VERSION "10.9.1"

NS_ :

BS_:

BU_: ACM ADAS_Body APM ASU_Gateway BCM BCM_BPM CCU_F CCU_R DUMMY_BCM_BPM DUMMY_ECU ETG LDM_L LDM_R OCS_P PSM_D SHVU_F SHVU_R TRM XGW_Body

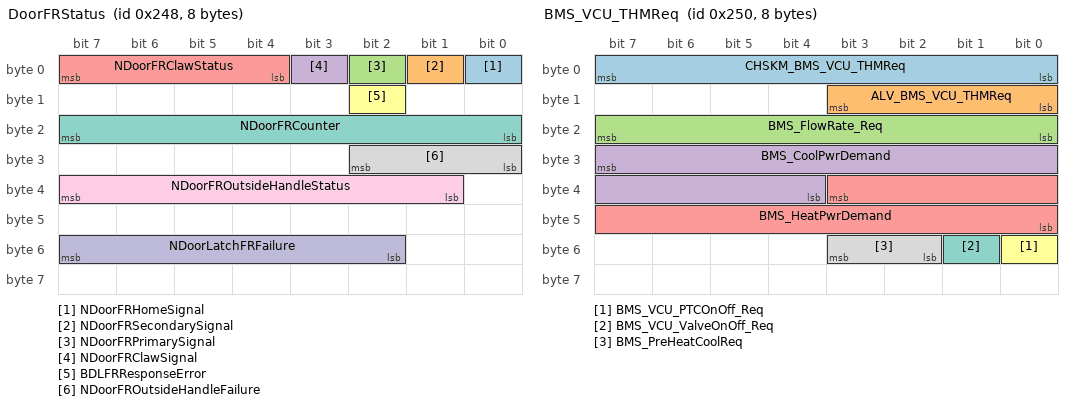
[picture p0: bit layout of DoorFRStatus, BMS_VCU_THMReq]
BO_ 584 DoorFRStatus: 8 XGW_Body
 SG_ NDoorFRHomeSignal : 0|1@0+ (1,0) [0|1] ""  BCM
 SG_ NDoorFRSecondarySignal : 1|1@0+ (1,0) [0|1] ""  BCM
 SG_ NDoorFRPrimarySignal : 2|1@0+ (1,0) [0|1] ""  BCM
 SG_ NDoorFRClawSignal : 3|1@0+ (1,0) [0|1] ""  BCM
 SG_ NDoorFRClawStatus : 7|4@0+ (1,0) [0|15] ""  BCM
 SG_ BDLFRResponseError : 10|1@0+ (1,0) [0|1] ""  BCM
 SG_ NDoorFRCounter : 23|8@0+ (1,0) [0|255] ""  BCM
 SG_ NDoorFROutsideHandleFailure : 26|3@0+ (1,0) [0|7] ""  BCM
 SG_ NDoorFROutsideHandleStatus : 39|7@0+ (1,0) [0|127] ""  BCM
 SG_ NDoorLatchFRFailure : 55|6@0+ (1,0) [0|63] ""  BCM

BO_ 592 BMS_VCU_THMReq: 8 XGW_Body
 SG_ CHSKM_BMS_VCU_THMReq : 7|8@0+ (1,0) [0|255] ""  BCM
 SG_ ALV_BMS_VCU_THMReq : 11|4@0+ (1,0) [0|14] ""  BCM
 SG_ BMS_FlowRate_Req : 23|8@0+ (1,0) [0|50] "l/min"  BCM
 SG_ BMS_CoolPwrDemand : 31|12@0+ (0.1,0) [0|10] "kW"  BCM
 SG_ BMS_HeatPwrDemand : 35|12@0+ (0.1,0) [0|10] "kW"  BCM
 SG_ BMS_VCU_PTCOnOff_Req : 48|1@0+ (1,0) [0|1] ""  BCM
 SG_ BMS_VCU_ValveOnOff_Req : 49|1@0+ (1,0) [0|1] ""  BCM
 SG_ BMS_PreHeatCoolReq : 51|2@0+ (1,0) [0|3] "" BCM

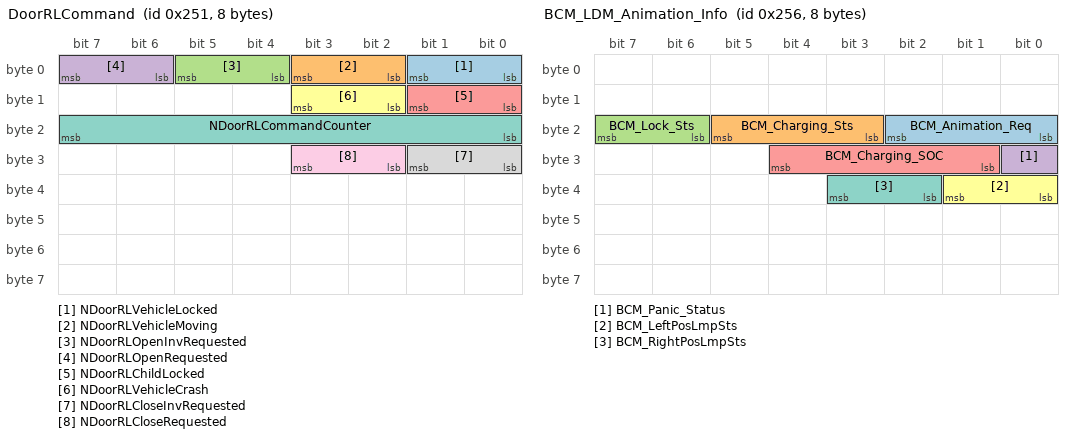
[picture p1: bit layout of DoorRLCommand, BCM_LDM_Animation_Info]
BO_ 593 DoorRLCommand: 8 BCM
 SG_ NDoorRLVehicleLocked : 1|2@0+ (1,0) [0|3] ""  DUMMY_ECU
 SG_ NDoorRLVehicleMoving : 3|2@0+ (1,0) [0|3] ""  DUMMY_ECU
 SG_ NDoorRLOpenInvRequested : 5|2@0+ (1,0) [0|3] ""  XGW_Body
 SG_ NDoorRLOpenRequested : 7|2@0+ (1,0) [0|3] ""  XGW_Body
 SG_ NDoorRLChildLocked : 9|2@0+ (1,0) [0|3] ""  DUMMY_ECU
 SG_ NDoorRLVehicleCrash : 11|2@0+ (1,0) [0|3] ""  DUMMY_ECU
 SG_ NDoorRLCommandCounter : 23|8@0+ (1,0) [0|255] ""  XGW_Body
 SG_ NDoorRLCloseInvRequested : 25|2@0+ (1,0) [0|3] ""  XGW_Body
 SG_ NDoorRLCloseRequested : 27|2@0+ (1,0) [0|3] ""  XGW_Body

BO_ 596 IDB_AVL_RPM_WHL_REAR: 8 XGW_Body
 SG_ CRC_AVL_RPM_WHL_REAR : 7|8@0+ (1,0) [0|255] ""  LDM_L,LDM_R
 SG_ ALIV_AVL_RPM_WHL_REAR : 11|4@0+ (1,0) [0|14] ""  LDM_L,LDM_R
 SG_ AVL_RPM_WHL_RLH : 23|16@0+ (0.0156,-511.9844) [-400|400] "rad/s"  LDM_L,LDM_R
 SG_ AVL_RPM_WHL_RRH : 39|16@0+ (0.0156,-511.9844) [-400|400] "rad/s"  LDM_L,LDM_R
 SG_ QU_AVL_RPM_WHL_RLH : 55|4@0+ (1,0) [0|15] "Bit"  LDM_L,LDM_R
 SG_ QU_AVL_RPM_WHL_RRH : 63|4@0+ (1,0) [0|15] "Bit"  LDM_L,LDM_R

BO_ 597 IDB_AVL_RPM_WHL_FRONT: 8 XGW_Body
 SG_ CRC_AVL_RPM_WHL_FRONT : 7|8@0+ (1,0) [0|255] ""  LDM_L,LDM_R
 SG_ ALIV_AVL_RPM_WHL_FRONT : 11|4@0+ (1,0) [0|14] ""  LDM_L,LDM_R
 SG_ AVL_RPM_WHL_FLH : 23|16@0+ (0.0156,-511.9844) [-400|400] "rad/s"  LDM_L,LDM_R
 SG_ AVL_RPM_WHL_FRH : 39|16@0+ (0.0156,-511.9844) [-400|400] "rad/s"  LDM_L,LDM_R
 SG_ QU_AVL_RPM_WHL_FLH : 55|4@0+ (1,0) [0|15] "Bit"  LDM_L,LDM_R
 SG_ QU_AVL_RPM_WHL_FRH : 63|4@0+ (1,0) [0|15] "Bit"  LDM_L,LDM_R

BO_ 598 BCM_LDM_Animation_Info: 8 BCM
 SG_ BCM_Animation_Req : 18|3@0+ (1,0) [0|7] ""  LDM_L,LDM_R
 SG_ BCM_Charging_Sts : 21|3@0+ (1,0) [0|7] ""  LDM_L,LDM_R
 SG_ BCM_Lock_Sts : 23|2@0+ (1,0) [0|3] ""  LDM_L,LDM_R
 SG_ BCM_Panic_Status : 24|1@0+ (1,0) [0|1] ""  LDM_L,LDM_R
 SG_ BCM_Charging_SOC : 28|4@0+ (1,0) [0|15] ""  LDM_L,LDM_R
 SG_ BCM_LeftPosLmpSts : 33|2@0+ (1,0) [0|3] ""  LDM_L
 SG_ BCM_RightPosLmpSts : 35|2@0+ (1,0) [0|3] ""  LDM_R

BO_ 618 ST_LCS_VEH: 3 ASU_Gateway
 SG_ ALIV_ST_LCS_VEH : 0|4@1+ (1,0) [0|14] ""  BCM,DUMMY_ECU
 SG_ ST_ECU_ST_LCS_VEH : 4|4@1+ (1,0) [0|15] ""  BCM,DUMMY_ECU
 SG_ QU_FN_LCS_VEH : 8|12@1+ (1,0) [0|0] ""  BCM,DUMMY_ECU

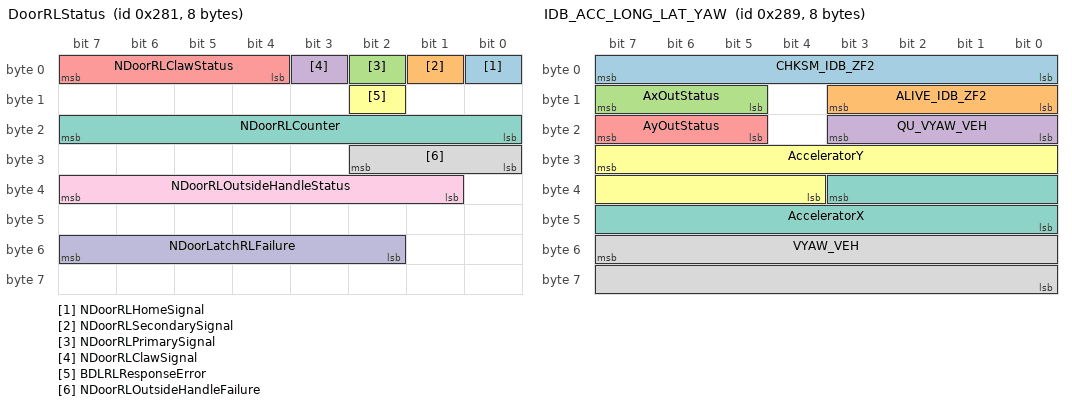
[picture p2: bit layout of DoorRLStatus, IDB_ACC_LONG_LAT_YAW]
BO_ 641 DoorRLStatus: 8 XGW_Body
 SG_ NDoorRLHomeSignal : 0|1@0+ (1,0) [0|1] ""  BCM
 SG_ NDoorRLSecondarySignal : 1|1@0+ (1,0) [0|1] ""  BCM
 SG_ NDoorRLPrimarySignal : 2|1@0+ (1,0) [0|1] ""  BCM
 SG_ NDoorRLClawSignal : 3|1@0+ (1,0) [0|1] ""  BCM
 SG_ NDoorRLClawStatus : 7|4@0+ (1,0) [0|15] ""  BCM
 SG_ BDLRLResponseError : 10|1@0+ (1,0) [0|1] ""  BCM
 SG_ NDoorRLCounter : 23|8@0+ (1,0) [0|255] ""  BCM
 SG_ NDoorRLOutsideHandleFailure : 26|3@0+ (1,0) [0|7] ""  BCM
 SG_ NDoorRLOutsideHandleStatus : 39|7@0+ (1,0) [0|127] ""  BCM
 SG_ NDoorLatchRLFailure : 55|6@0+ (1,0) [0|63] ""  BCM

BO_ 649 IDB_ACC_LONG_LAT_YAW: 8 XGW_Body
 SG_ CHKSM_IDB_ZF2 : 7|8@0+ (1,0) [0|255] ""  LDM_L,LDM_R
 SG_ ALIVE_IDB_ZF2 : 11|4@0+ (1,0) [0|14] ""  LDM_L,LDM_R
 SG_ AxOutStatus : 15|3@0+ (1,0) [0|7] ""  LDM_L,LDM_R
 SG_ QU_VYAW_VEH : 19|4@0+ (1,0) [0|15] ""  LDM_L,LDM_R
 SG_ AyOutStatus : 23|3@0+ (1,0) [0|7] ""  LDM_L,LDM_R
 SG_ AcceleratorY : 31|12@0+ (0.02713,-21.5928) [-21.593|21.5928] "m/s^2"  LDM_L,LDM_R
 SG_ AcceleratorX : 35|12@0+ (0.02713,-21.5928) [-21.593|21.5928] "m/s^2"  LDM_L,LDM_R
 SG_ VYAW_VEH : 55|16@0+ (0.005,-163.84) [-163.84|163.83] "°/s"  LDM_L,LDM_R

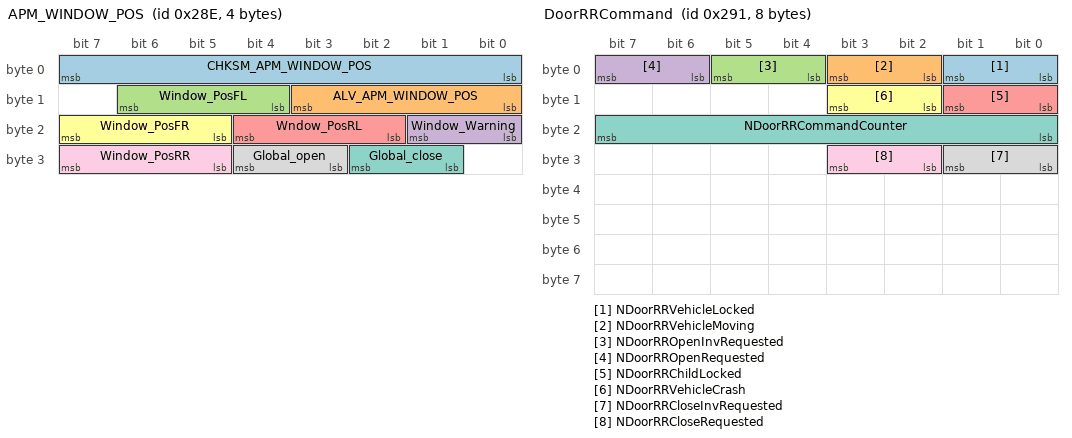
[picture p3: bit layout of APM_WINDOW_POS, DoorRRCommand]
BO_ 654 APM_WINDOW_POS: 4 APM
 SG_ CHKSM_APM_WINDOW_POS : 7|8@0+ (1,0) [0|255] ""  XGW_Body
 SG_ ALV_APM_WINDOW_POS : 11|4@0+ (1,0) [0|14] ""  XGW_Body
 SG_ Window_PosFL : 14|3@0+ (1,0) [0|7] "-"  XGW_Body
 SG_ Window_Warning : 17|2@0+ (1,0) [0|3] ""  XGW_Body
 SG_ Wndow_PosRL : 20|3@0+ (1,0) [0|7] ""  XGW_Body
 SG_ Window_PosFR : 23|3@0+ (1,0) [0|7] ""  XGW_Body
 SG_ Global_close : 26|2@0+ (1,0) [0|3] ""  XGW_Body
 SG_ Global_open : 28|2@0+ (1,0) [0|3] ""  XGW_Body
 SG_ Window_PosRR : 31|3@0+ (1,0) [0|7] "-"  XGW_Body

BO_ 657 DoorRRCommand: 8 BCM
 SG_ NDoorRRVehicleLocked : 1|2@0+ (1,0) [0|3] ""  DUMMY_ECU
 SG_ NDoorRRVehicleMoving : 3|2@0+ (1,0) [0|3] ""  DUMMY_ECU
 SG_ NDoorRROpenInvRequested : 5|2@0+ (1,0) [0|3] ""  XGW_Body
 SG_ NDoorRROpenRequested : 7|2@0+ (1,0) [0|3] ""  XGW_Body
 SG_ NDoorRRChildLocked : 9|2@0+ (1,0) [0|3] ""  DUMMY_ECU
 SG_ NDoorRRVehicleCrash : 11|2@0+ (1,0) [0|3] ""  DUMMY_ECU
 SG_ NDoorRRCommandCounter : 23|8@0+ (1,0) [0|255] ""  XGW_Body
 SG_ NDoorRRCloseInvRequested : 25|2@0+ (1,0) [0|3] ""  XGW_Body
 SG_ NDoorRRCloseRequested : 27|2@0+ (1,0) [0|3] ""  XGW_Body

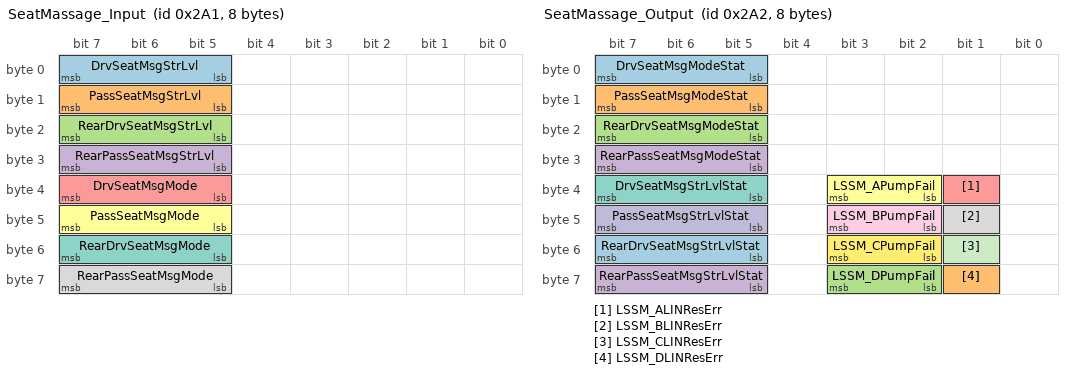
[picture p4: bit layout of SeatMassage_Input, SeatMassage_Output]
BO_ 673 SeatMassage_Input: 8 XGW_Body
 SG_ DrvSeatMsgStrLvl : 7|3@0+ (1,0) [0|7] ""  PSM_D
 SG_ PassSeatMsgStrLvl : 15|3@0+ (1,0) [0|7] ""  PSM_D
 SG_ RearDrvSeatMsgStrLvl : 23|3@0+ (1,0) [0|7] "-"  PSM_D
 SG_ RearPassSeatMsgStrLvl : 31|3@0+ (1,0) [0|7] ""  PSM_D
 SG_ DrvSeatMsgMode : 39|3@0+ (1,0) [0|7] ""  PSM_D
 SG_ PassSeatMsgMode : 47|3@0+ (1,0) [0|7] ""  PSM_D
 SG_ RearDrvSeatMsgMode : 55|3@0+ (1,0) [0|7] ""  PSM_D
 SG_ RearPassSeatMsgMode : 63|3@0+ (1,0) [0|7] "-"  PSM_D

BO_ 674 SeatMassage_Output: 8 PSM_D
 SG_ DrvSeatMsgModeStat : 7|3@0+ (1,0) [0|7] ""  XGW_Body
 SG_ PassSeatMsgModeStat : 15|3@0+ (1,0) [0|7] ""  XGW_Body
 SG_ RearDrvSeatMsgModeStat : 23|3@0+ (1,0) [0|7] ""  XGW_Body
 SG_ RearPassSeatMsgModeStat : 31|3@0+ (1,0) [0|7] ""  XGW_Body
 SG_ LSSM_ALINResErr : 33|1@0+ (1,0) [0|1] ""  XGW_Body
 SG_ LSSM_APumpFail : 35|2@0+ (1,0) [0|3] ""  XGW_Body
 SG_ DrvSeatMsgStrLvlStat : 39|3@0+ (1,0) [0|7] ""  XGW_Body
 SG_ LSSM_BLINResErr : 41|1@0+ (1,0) [0|1] ""  XGW_Body
 SG_ LSSM_BPumpFail : 43|2@0+ (1,0) [0|3] ""  XGW_Body
 SG_ PassSeatMsgStrLvlStat : 47|3@0+ (1,0) [0|7] "-"  XGW_Body
 SG_ LSSM_CLINResErr : 49|1@0+ (1,0) [0|1] ""  XGW_Body
 SG_ LSSM_CPumpFail : 51|2@0+ (1,0) [0|3] "-"  XGW_Body
 SG_ RearDrvSeatMsgStrLvlStat : 55|3@0+ (1,0) [0|7] "-"  XGW_Body
 SG_ LSSM_DLINResErr : 57|1@0+ (1,0) [0|1] ""  XGW_Body
 SG_ LSSM_DPumpFail : 59|2@0+ (1,0) [0|3] "-"  XGW_Body
 SG_ RearPassSeatMsgStrLvlStat : 63|3@0+ (1,0) [0|7] ""  XGW_Body

BO_ 676 SVC_EHC_EHC_2: 8 ASU_Gateway
 SG_ ID2 M : 0|8@1+ (1,0) [0|0] ""  BCM,XGW_Body
 SG_ ECU_ID_WUPREG m39 : 8|8@1+ (1,0) [0|127] ""  BCM,XGW_Body
 SG_ ID_FN_INQY m1 : 8|16@1+ (1,0) [0|0] ""  BCM,XGW_Body
 SG_ ID_FN_RQ_BUS m12 : 8|16@1+ (1,0) [0|0] ""  BCM,XGW_Body
 SG_ NO_CC_MESS_EXT m65 : 8|16@1+ (1,0) [0|65534] ""  BCM,XGW_Body
 SG_ NO_CC_MESS_STD m64 : 8|16@1+ (1,0) [0|65534] ""  BCM,XGW_Body
 SG_ WACA m39 : 16|8@1+ (1,0) [0|0] ""  BCM,XGW_Body
 SG_ ID_RQ_BUS m12 : 24|8@1+ (1,0) [0|0] ""  BCM,XGW_Body
 SG_ ST_CC_MESS_EXT m65 : 24|2@1+ (1,0) [0|0] ""  BCM,XGW_Body
 SG_ ST_CC_MESS_STD m64 : 24|2@1+ (1,0) [0|0] ""  BCM,XGW_Body
 SG_ TRANF_CC_MESS_EXT m65 : 26|4@1+ (1,0) [0|14] ""  BCM,XGW_Body
 SG_ TRANF_CC_MESS_STD m64 : 26|4@1+ (1,0) [0|14] ""  BCM,XGW_Body
 SG_ ST_IDC_CCLK_CC_MESS_EXT m65 : 30|2@1+ (1,0) [0|0] ""  BCM,XGW_Body
 SG_ ST_IDC_CCLK_CC_MESS_STD m64 : 30|2@1+ (1,0) [0|0] ""  BCM,XGW_Body
 SG_ NO_FRM_CC_MESS_EXT m65 : 32|4@1+ (1,0) [0|14] ""  BCM,XGW_Body
 SG_ ST_RQ_BUS m12 : 32|4@1+ (1,0) [0|0] ""  BCM,XGW_Body
 SG_ QUAN_FRM_CC_MESS_EXT m65 : 36|4@1+ (1,0) [0|14] ""  BCM,XGW_Body
 SG_ ST_LAW_RQ m12 : 36|4@1+ (1,0) [0|0] ""  BCM,XGW_Body
 SG_ DUR_FLLUPT m12 : 40|8@1+ (1,0) [0|254] "min"  BCM,XGW_Body
 SG_ UTDT_CC_MESS m65 : 40|24@1+ (1,0) [0|0] ""  BCM,XGW_Body

BO_ 714 IC_SENSOR: 8 XGW_Body
 SG_ CHKSM_IC_SENSOR : 7|8@0+ (1,0) [0|255] ""  ACM,ADAS_Body,APM,ASU_Gateway,BCM,BCM_BPM,CCU_F,CCU_R,ETG,LDM_L,LDM_R,OCS_P,PSM_D,SHVU_F,SHVU_R,TRM
 SG_ ALV_IC_SENSOR : 11|4@0+ (1,0) [0|14] ""  ACM,ADAS_Body,APM,ASU_Gateway,BCM,BCM_BPM,CCU_F,CCU_R,ETG,LDM_L,LDM_R,OCS_P,PSM_D,SHVU_F,SHVU_R,TRM
 SG_ MHU_STAT_AmbientTempRaw : 23|8@0+ (0.5,-40) [-40|85] "°C"  ACM,ADAS_Body,APM,ASU_Gateway,BCM,BCM_BPM,CCU_F,CCU_R,ETG,LDM_L,LDM_R,OCS_P,PSM_D,SHVU_F,SHVU_R,TRM
 SG_ MHU_STAT_FuelLevel : 31|8@0+ (1,0) [0|100] "l"  ACM,ADAS_Body,APM,ASU_Gateway,BCM,BCM_BPM,CCU_F,CCU_R,ETG,LDM_L,LDM_R,OCS_P,PSM_D,SHVU_F,SHVU_R,TRM
 SG_ MHU_STAT_AmbientTemp : 39|8@0+ (0.5,-40) [-40|85] "Degree C"  ACM,ADAS_Body,APM,ASU_Gateway,BCM,BCM_BPM,CCU_F,CCU_R,ETG,LDM_L,LDM_R,OCS_P,PSM_D,SHVU_F,SHVU_R,TRM
 SG_ MHU_STAT_CoolantLevelStatus : 47|2@0+ (1,0) [0|3] "-"  ACM,ADAS_Body,APM,ASU_Gateway,BCM,BCM_BPM,CCU_F,CCU_R,ETG,LDM_L,LDM_R,OCS_P,PSM_D,SHVU_F,SHVU_R,TRM

BO_ 715 IC_TEMP: 8 BCM
 SG_ TEMP_EX : 7|8@0+ (0.5,-40) [-40|85] "°C"  DUMMY_ECU,XGW_Body
 SG_ TEMP_EX_UNFILT : 15|8@0+ (0.5,-40) [-40|85] "°C"  CCU_F,CCU_R,DUMMY_ECU,LDM_L,LDM_R,XGW_Body

BO_ 753 IC_STAT_AIRBAG: 1 XGW_Body
 SG_ MHU_STAT_AirbagWarnLamp : 1|2@0+ (1,0) [0|3] ""  ACM

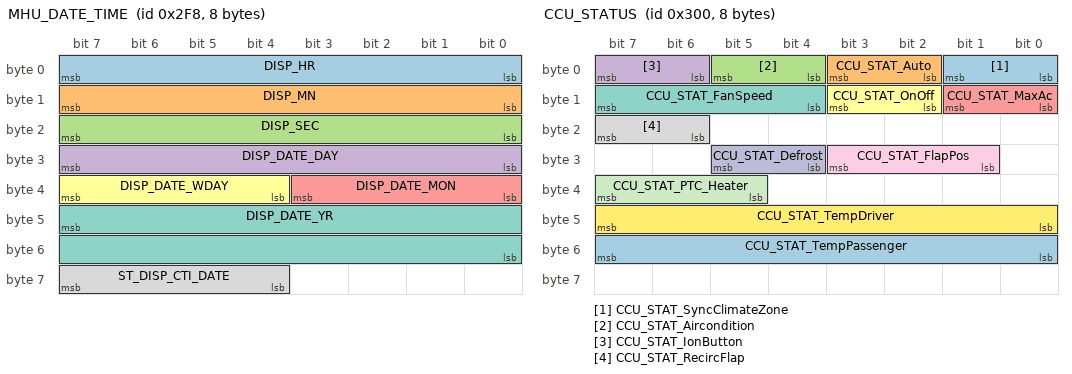
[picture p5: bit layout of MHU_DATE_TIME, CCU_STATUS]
BO_ 760 MHU_DATE_TIME: 8 XGW_Body
 SG_ DISP_HR : 7|8@0+ (1,0) [0|23] "h"  ACM,ADAS_Body,APM,ASU_Gateway,BCM,BCM_BPM,CCU_F,CCU_R,ETG,LDM_L,LDM_R,OCS_P,PSM_D,SHVU_F,SHVU_R,TRM
 SG_ DISP_MN : 15|8@0+ (1,0) [0|59] "min"  ACM,ADAS_Body,APM,ASU_Gateway,BCM,BCM_BPM,CCU_F,CCU_R,ETG,LDM_L,LDM_R,OCS_P,PSM_D,SHVU_F,SHVU_R,TRM
 SG_ DISP_SEC : 23|8@0+ (1,0) [0|59] "s"  ACM,ADAS_Body,APM,ASU_Gateway,BCM,BCM_BPM,CCU_F,CCU_R,ETG,LDM_L,LDM_R,OCS_P,PSM_D,SHVU_F,SHVU_R,TRM
 SG_ DISP_DATE_DAY : 31|8@0+ (1,0) [1|31] "Day"  ACM,ADAS_Body,APM,ASU_Gateway,BCM,BCM_BPM,CCU_F,CCU_R,ETG,LDM_L,LDM_R,OCS_P,PSM_D,SHVU_F,SHVU_R,TRM
 SG_ DISP_DATE_MON : 35|4@0+ (1,0) [1|12] "Month"  ACM,ADAS_Body,APM,ASU_Gateway,BCM,BCM_BPM,CCU_F,CCU_R,ETG,LDM_L,LDM_R,OCS_P,PSM_D,SHVU_F,SHVU_R,TRM
 SG_ DISP_DATE_WDAY : 39|4@0+ (1,0) [0|15] ""  ACM,ADAS_Body,APM,ASU_Gateway,BCM,BCM_BPM,CCU_F,CCU_R,ETG,LDM_L,LDM_R,OCS_P,PSM_D,SHVU_F,SHVU_R,TRM
 SG_ DISP_DATE_YR : 47|16@0+ (1,0) [1|65534] "Year"  ACM,ADAS_Body,APM,ASU_Gateway,BCM,BCM_BPM,CCU_F,CCU_R,ETG,LDM_L,LDM_R,OCS_P,PSM_D,SHVU_F,SHVU_R,TRM
 SG_ ST_DISP_CTI_DATE : 63|4@0+ (1,0) [0|15] ""  ACM,ADAS_Body,APM,ASU_Gateway,BCM,BCM_BPM,CCU_F,CCU_R,ETG,LDM_L,LDM_R,OCS_P,PSM_D,SHVU_F,SHVU_R,TRM

BO_ 768 CCU_STATUS: 8 CCU_F
 SG_ CCU_STAT_SyncClimateZone : 1|2@0+ (1,0) [0|3] ""  CCU_R,XGW_Body
 SG_ CCU_STAT_Auto : 3|2@0+ (1,0) [0|3] "-"  CCU_R,XGW_Body
 SG_ CCU_STAT_Aircondition : 5|2@0+ (1,0) [0|3] ""  CCU_R,XGW_Body
 SG_ CCU_STAT_IonButton : 7|2@0+ (1,0) [0|3] ""  CCU_R,XGW_Body
 SG_ CCU_STAT_MaxAc : 9|2@0+ (1,0) [0|3] ""  CCU_R,XGW_Body
 SG_ CCU_STAT_OnOff : 11|2@0+ (1,0) [0|3] "Bit"  CCU_R,XGW_Body
 SG_ CCU_STAT_FanSpeed : 15|4@0+ (1,0) [0|15] ""  CCU_R,XGW_Body
 SG_ CCU_STAT_RecircFlap : 23|2@0+ (1,0) [0|3] ""  CCU_R,XGW_Body
 SG_ CCU_STAT_FlapPos : 27|3@0+ (1,0) [0|7] ""  CCU_R,XGW_Body
 SG_ CCU_STAT_Defrost : 29|2@0+ (1,0) [0|3] "-"  CCU_R,XGW_Body
 SG_ CCU_STAT_PTC_Heater : 39|3@0+ (1,0) [0|7] "-"  CCU_R,XGW_Body
 SG_ CCU_STAT_TempDriver : 47|8@0+ (0.5,0) [16|32] "Degree C"  CCU_R,XGW_Body
 SG_ CCU_STAT_TempPassenger : 55|8@0+ (0.5,0) [16|32] "Degree C"  CCU_R,XGW_Body

BO_ 770 CCU_TEMP_PRESSURE: 6 CCU_F
 SG_ CHKSM_CCU_TEMP_PRESSURE : 7|8@0+ (1,0) [0|255] ""  XGW_Body
 SG_ ALV_CCU_TEMP_PRESSURE : 11|4@0+ (1,0) [0|14] ""  XGW_Body
 SG_ CCU_Pressure_AC : 23|6@0+ (1,0) [0|62] "bar"  XGW_Body
 SG_ CCU_InteriorTemp : 31|8@0+ (0.5,-40) [-40|85] "Degree C"  ACM,ADAS_Body,APM,ASU_Gateway,BCM,BCM_BPM,CCU_R,ETG,LDM_L,LDM_R,OCS_P,PSM_D,SHVU_F,SHVU_R,TRM,XGW_Body
 SG_ CCU_TempEx_AC : 39|8@0+ (0.5,-40) [-40|85] "Degree C"  ACM,ADAS_Body,APM,ASU_Gateway,BCM,BCM_BPM,CCU_R,ETG,LDM_L,LDM_R,OCS_P,PSM_D,SHVU_F,SHVU_R,TRM,XGW_Body
 SG_ CCU_EvaporatorTemp : 47|8@0+ (0.5,-40) [-40|85] "Degree C"  XGW_Body

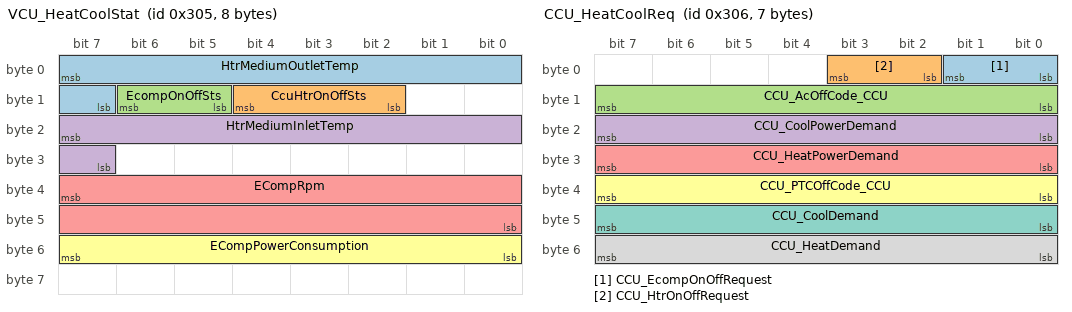
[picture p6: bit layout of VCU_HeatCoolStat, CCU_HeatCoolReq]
BO_ 773 VCU_HeatCoolStat: 8 XGW_Body
 SG_ HtrMediumOutletTemp : 7|9@0+ (0.5,-40) [-40|200] "°C"  CCU_F,CCU_R
 SG_ CcuHtrOnOffSts : 12|3@0+ (1,0) [0|7] ""  CCU_F,CCU_R
 SG_ EcompOnOffSts : 14|2@0+ (1,0) [0|3] ""  CCU_F,CCU_R
 SG_ HtrMediumInletTemp : 23|9@0+ (0.5,-40) [-40|200] "Degree C"  CCU_F,CCU_R
 SG_ ECompRpm : 39|16@0+ (1,0) [0|12000] "1/min"  CCU_F,CCU_R
 SG_ ECompPowerConsumption : 55|8@0+ (0.1,0) [0|12] "kW"  CCU_F,CCU_R

BO_ 774 CCU_HeatCoolReq: 7 CCU_F
 SG_ CCU_EcompOnOffRequest : 1|2@0+ (1,0) [0|3] ""  XGW_Body
 SG_ CCU_HtrOnOffRequest : 3|2@0+ (1,0) [0|3] ""  XGW_Body
 SG_ CCU_AcOffCode_CCU : 15|8@0+ (1,0) [0|255] ""  XGW_Body
 SG_ CCU_CoolPowerDemand : 23|8@0+ (0.1,0) [0|10] "kW"  XGW_Body
 SG_ CCU_HeatPowerDemand : 31|8@0+ (0.1,0) [0|10] "kW"  XGW_Body
 SG_ CCU_PTCOffCode_CCU : 39|8@0+ (1,0) [0|255] ""  XGW_Body
 SG_ CCU_CoolDemand : 47|8@0+ (0.5,0) [0|100] "%"  XGW_Body
 SG_ CCU_HeatDemand : 55|8@0+ (0.5,0) [0|100] "%"  XGW_Body

BO_ 775 CPD_OUTPUT: 3 XGW_Body
 SG_ CHKSM_CPD_Output_1 : 7|8@0+ (1,0) [0|255] ""  BCM
 SG_ ALV_CPD_Output_1 : 11|4@0+ (1,0) [0|14] ""  BCM
 SG_ OUT_Alert_TO_BCM : 14|3@0+ (1,0) [0|7] "-"  BCM,CCU_F,CCU_R
 SG_ CPD_State_information : 20|3@0+ (1,0) [0|7] "-"  BCM

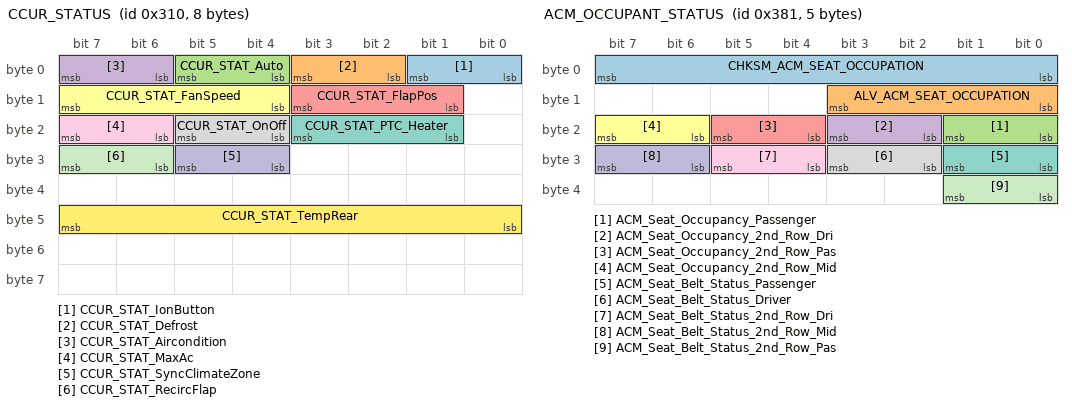
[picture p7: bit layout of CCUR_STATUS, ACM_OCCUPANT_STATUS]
BO_ 784 CCUR_STATUS: 8 CCU_F
 SG_ CCUR_STAT_IonButton : 1|2@0+ (1,0) [0|3] "-"  XGW_Body
 SG_ CCUR_STAT_Defrost : 3|2@0+ (1,0) [0|3] ""  XGW_Body
 SG_ CCUR_STAT_Auto : 5|2@0+ (1,0) [0|3] ""  XGW_Body
 SG_ CCUR_STAT_Aircondition : 7|2@0+ (1,0) [0|3] "-"  XGW_Body
 SG_ CCUR_STAT_FlapPos : 11|3@0+ (1,0) [0|7] "-"  XGW_Body
 SG_ CCUR_STAT_FanSpeed : 15|4@0+ (1,0) [0|15] "-"  XGW_Body
 SG_ CCUR_STAT_PTC_Heater : 19|3@0+ (1,0) [0|7] ""  XGW_Body
 SG_ CCUR_STAT_OnOff : 21|2@0+ (1,0) [0|3] "Bit"  XGW_Body
 SG_ CCUR_STAT_MaxAc : 23|2@0+ (1,0) [0|3] ""  XGW_Body
 SG_ CCUR_STAT_SyncClimateZone : 29|2@0+ (1,0) [0|3] "-"  XGW_Body
 SG_ CCUR_STAT_RecircFlap : 31|2@0+ (1,0) [0|3] "-"  XGW_Body
 SG_ CCUR_STAT_TempRear : 47|8@0+ (0.5,0) [16|32] "Degree C"  XGW_Body

BO_ 808 IC_RELATIVTIME: 8 BCM
 SG_ T_SEC_COU_REL : 0|32@1+ (1,0) [0|4294967294] "s"  ASU_Gateway
 SG_ T_DAY_COU_ABSL : 32|16@1+ (1,0) [0|65534] "Day"  ADAS_Body,DUMMY_ECU

BO_ 806 POD_StatusDCDC1: 8 XGW_Body
  SG_ CHSKM_POD_StatusDCDC1 : 7|8@0+ (1,0) [0|255] "" BCM
  SG_ ALV_POD_StatusDCDC1 : 11|4@0+ (1,0) [0|14] "" BCM
  SG_ POD_statusDCDC : 14|3@0+ (1,0) [0|7] "" BCM

BO_ 809 BCM_ODO: 8 BCM
 SG_ CRC_BCM_ODO : 7|8@0+ (1,0) [0|255] ""  XGW_Body
 SG_ ALIV_BCM_ODO : 11|4@0+ (1,0) [0|14] ""  XGW_Body
 SG_ Odometer_BCM : 23|20@0+ (1,0) [0|999999] "km"  XGW_Body
 SG_ SECCAN_BCM_ODO : 63|8@0+ (1,0) [0|255] ""  XGW_Body

BO_ 812 ASU_HEIGHT_LEVEL: 8 ASU_Gateway
 SG_ CRC_HGLV_EHC : 0|8@1+ (1,0) [0|255] ""  BCM,DUMMY_ECU
 SG_ ALIV_HGLV_EHC : 8|4@1+ (1,0) [0|14] ""  BCM,DUMMY_ECU
 SG_ HGLV_RLH_EHC : 16|8@1+ (1,-127) [-127|127] "mm"  BCM,DUMMY_ECU
 SG_ HGLV_RRH_EHC : 24|8@1+ (1,-127) [-127|127] "mm"  BCM,DUMMY_ECU
 SG_ QU_HGLV_RLH_EHC : 32|4@1+ (1,0) [0|15] ""  BCM,DUMMY_ECU
 SG_ QU_HGLV_RRH_EHC : 36|4@1+ (1,0) [0|15] ""  BCM,DUMMY_ECU

BO_ 816 IC_MILEAGE: 8 BCM
 SG_ MILE_KM : 7|24@0+ (1,0) [0|999999] "km"  ACM,ADAS_Body,APM,ASU_Gateway,BCM_BPM,CCU_F,CCU_R,DUMMY_ECU,ETG,LDM_L,LDM_R,OCS_P,PSM_D,SHVU_F,SHVU_R,TRM,XGW_Body
 SG_ FLLV_FUTA : 31|8@0+ (1,0) [0|254] "l"  ACM,ADAS_Body,APM,ASU_Gateway,BCM_BPM,CCU_F,CCU_R,DUMMY_ECU,ETG,LDM_L,LDM_R,OCS_P,PSM_D,SHVU_F,SHVU_R,TRM,XGW_Body
 SG_ RNG : 51|12@0+ (1,0) [0|4094] "km"  ACM,ADAS_Body,APM,ASU_Gateway,BCM_BPM,CCU_F,CCU_R,DUMMY_ECU,ETG,LDM_L,LDM_R,OCS_P,PSM_D,SHVU_F,SHVU_R,TRM,XGW_Body
 SG_ ST_FLLV_FUTA_SPAR : 55|2@0+ (1,0) [0|3] ""  ACM,ADAS_Body,APM,ASU_Gateway,BCM_BPM,CCU_F,CCU_R,DUMMY_ECU,ETG,LDM_L,LDM_R,OCS_P,PSM_D,SHVU_F,SHVU_R,TRM,XGW_Body

BO_ 880 MHU_SBR_Status: 8 XGW_Body
 SG_ CRC_MHU_SBR_Status : 7|8@0+ (1,0) [0|255] ""  ACM
 SG_ ALV_MHU_SBR_Status : 11|4@0+ (1,0) [0|14] ""  ACM
 SG_ SBR_STAT_Chime : 13|2@0+ (1,0) [0|3] ""  ACM
 SG_ SBR_STAT_Telltale : 15|2@0+ (1,0) [0|3] ""  ACM
 SG_ SBR_STAT_Active : 16|1@0+ (1,0) [0|1] ""  ACM

BO_ 896 BCM_VEHICLE_IDENT_NUMBER: 8 BCM
 SG_ VIN_Byte1 : 7|8@0+ (1,0) [0|255] ""  ACM,ADAS_Body,APM,ASU_Gateway,BCM_BPM,CCU_F,CCU_R,ETG,LDM_L,LDM_R,OCS_P,PSM_D,SHVU_F,SHVU_R,TRM,XGW_Body
 SG_ VIN_Byte2 : 15|8@0+ (1,0) [0|255] ""  ACM,ADAS_Body,APM,ASU_Gateway,BCM_BPM,CCU_F,CCU_R,ETG,LDM_L,LDM_R,OCS_P,PSM_D,SHVU_F,SHVU_R,TRM,XGW_Body
 SG_ VIN_Byte3 : 23|8@0+ (1,0) [0|255] ""  ACM,ADAS_Body,APM,ASU_Gateway,BCM_BPM,CCU_F,CCU_R,ETG,LDM_L,LDM_R,OCS_P,PSM_D,SHVU_F,SHVU_R,TRM,XGW_Body
 SG_ VIN_Byte4 : 31|8@0+ (1,0) [0|255] ""  ACM,ADAS_Body,APM,ASU_Gateway,BCM_BPM,CCU_F,CCU_R,ETG,LDM_L,LDM_R,OCS_P,PSM_D,SHVU_F,SHVU_R,TRM,XGW_Body
 SG_ VIN_Byte5 : 39|8@0+ (1,0) [0|255] ""  ACM,ADAS_Body,APM,ASU_Gateway,BCM_BPM,CCU_F,CCU_R,ETG,LDM_L,LDM_R,OCS_P,PSM_D,SHVU_F,SHVU_R,TRM,XGW_Body
 SG_ VIN_Byte6 : 47|8@0+ (1,0) [0|255] ""  ACM,ADAS_Body,APM,ASU_Gateway,BCM_BPM,CCU_F,CCU_R,ETG,LDM_L,LDM_R,OCS_P,PSM_D,SHVU_F,SHVU_R,TRM,XGW_Body
 SG_ VIN_Byte7 : 55|8@0+ (1,0) [0|255] ""  ACM,ADAS_Body,APM,ASU_Gateway,BCM_BPM,CCU_F,CCU_R,ETG,LDM_L,LDM_R,OCS_P,PSM_D,SHVU_F,SHVU_R,TRM,XGW_Body

BO_ 897 ACM_OCCUPANT_STATUS: 5 ACM
 SG_ CHKSM_ACM_SEAT_OCCUPATION : 7|8@0+ (1,0) [0|255] ""  ADAS_Body,XGW_Body,CCU_F
 SG_ ALV_ACM_SEAT_OCCUPATION : 11|4@0+ (1,0) [0|14] ""  ADAS_Body,XGW_Body,CCU_F
 SG_ ACM_Seat_Occupancy_Passenger : 17|2@0+ (1,0) [0|3] ""  BCM,XGW_Body,CCU_F
 SG_ ACM_Seat_Occupancy_2nd_Row_Dri : 19|2@0+ (1,0) [0|3] ""  BCM,XGW_Body,CCU_F
 SG_ ACM_Seat_Occupancy_2nd_Row_Pas : 21|2@0+ (1,0) [0|3] "-"  BCM,XGW_Body,CCU_F
 SG_ ACM_Seat_Occupancy_2nd_Row_Mid : 23|2@0+ (1,0) [0|3] "-"  BCM,XGW_Body,CCU_F
 SG_ ACM_Seat_Belt_Status_Passenger : 25|2@0+ (1,0) [0|3] ""  XGW_Body,CCU_F
 SG_ ACM_Seat_Belt_Status_Driver : 27|2@0+ (1,0) [0|3] ""  ADAS_Body,BCM,XGW_Body,CCU_F
 SG_ ACM_Seat_Belt_Status_2nd_Row_Dri : 29|2@0+ (1,0) [0|3] "-"  XGW_Body,CCU_F
 SG_ ACM_Seat_Belt_Status_2nd_Row_Mid : 31|2@0+ (1,0) [0|3] ""  XGW_Body,CCU_F
 SG_ ACM_Seat_Belt_Status_2nd_Row_Pas : 33|2@0+ (1,0) [0|3] "-"  XGW_Body,CCU_F

BO_ 905 VCU_Sts3: 8 XGW_Body
 SG_ VCU_IMMO_Sts : 35|2@0+ (1,0) [0|3] ""  BCM
 SG_ SECCAN_VCU_IMMO_Sts : 63|8@0+ (1,0) [0|255] ""  BCM

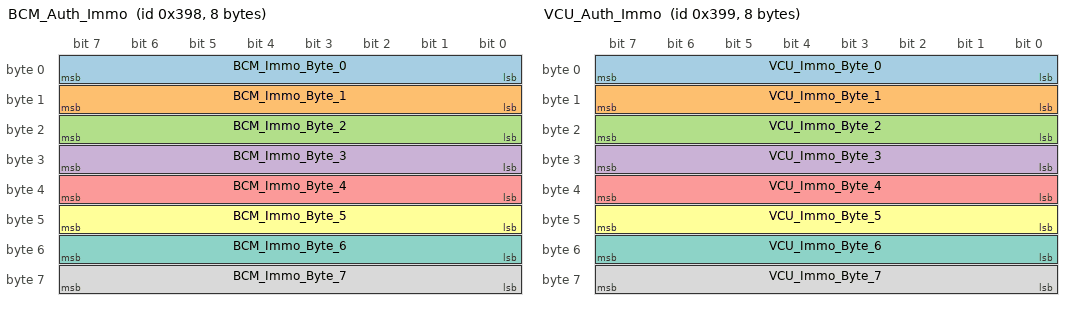
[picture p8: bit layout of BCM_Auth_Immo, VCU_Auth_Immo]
BO_ 920 BCM_Auth_Immo: 8 BCM
 SG_ BCM_Immo_Byte_0 : 7|8@0+ (1,0) [0|255] ""  XGW_Body
 SG_ BCM_Immo_Byte_1 : 15|8@0+ (1,0) [0|255] ""  XGW_Body
 SG_ BCM_Immo_Byte_2 : 23|8@0+ (1,0) [0|255] ""  XGW_Body
 SG_ BCM_Immo_Byte_3 : 31|8@0+ (1,0) [0|255] ""  XGW_Body
 SG_ BCM_Immo_Byte_4 : 39|8@0+ (1,0) [0|255] ""  XGW_Body
 SG_ BCM_Immo_Byte_5 : 47|8@0+ (1,0) [0|255] ""  XGW_Body
 SG_ BCM_Immo_Byte_6 : 55|8@0+ (1,0) [0|255] ""  XGW_Body
 SG_ BCM_Immo_Byte_7 : 63|8@0+ (1,0) [0|255] ""  XGW_Body

BO_ 921 VCU_Auth_Immo: 8 XGW_Body
 SG_ VCU_Immo_Byte_0 : 7|8@0+ (1,0) [0|255] ""  BCM
 SG_ VCU_Immo_Byte_1 : 15|8@0+ (1,0) [0|255] ""  BCM
 SG_ VCU_Immo_Byte_2 : 23|8@0+ (1,0) [0|255] ""  BCM
 SG_ VCU_Immo_Byte_3 : 31|8@0+ (1,0) [0|255] ""  BCM
 SG_ VCU_Immo_Byte_4 : 39|8@0+ (1,0) [0|255] ""  BCM
 SG_ VCU_Immo_Byte_5 : 47|8@0+ (1,0) [0|255] ""  BCM
 SG_ VCU_Immo_Byte_6 : 55|8@0+ (1,0) [0|255] ""  BCM
 SG_ VCU_Immo_Byte_7 : 63|8@0+ (1,0) [0|255] ""  BCM

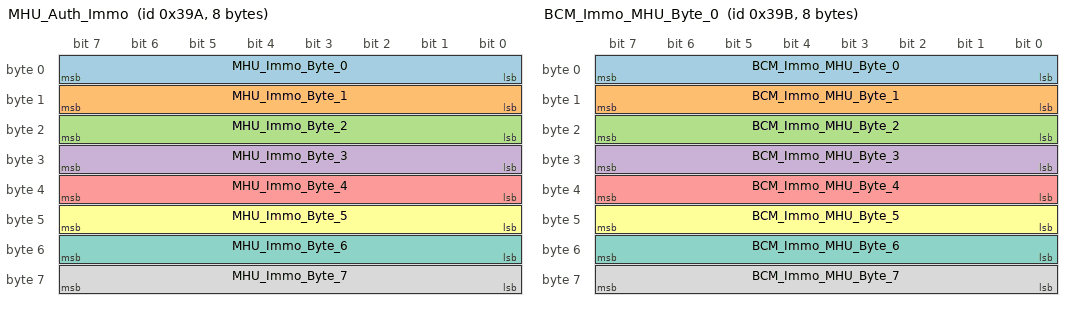
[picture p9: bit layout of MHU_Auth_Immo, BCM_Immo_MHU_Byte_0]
BO_ 922 MHU_Auth_Immo: 8 XGW_Body
 SG_ MHU_Immo_Byte_0 : 7|8@0+ (1,0) [0|255] "-"  ADAS_Body,BCM
 SG_ MHU_Immo_Byte_1 : 15|8@0+ (1,0) [0|255] "-"  BCM
 SG_ MHU_Immo_Byte_2 : 23|8@0+ (1,0) [0|255] ""  BCM
 SG_ MHU_Immo_Byte_3 : 31|8@0+ (1,0) [0|255] ""  BCM
 SG_ MHU_Immo_Byte_4 : 39|8@0+ (1,0) [0|255] ""  BCM
 SG_ MHU_Immo_Byte_5 : 47|8@0+ (1,0) [0|255] ""  BCM
 SG_ MHU_Immo_Byte_6 : 55|8@0+ (1,0) [0|255] ""  BCM
 SG_ MHU_Immo_Byte_7 : 63|8@0+ (1,0) [0|255] "-"  BCM

BO_ 923 BCM_Immo_MHU_Byte_0: 8 BCM
 SG_ BCM_Immo_MHU_Byte_0 : 7|8@0+ (1,0) [0|255] "-"  XGW_Body
 SG_ BCM_Immo_MHU_Byte_1 : 15|8@0+ (1,0) [0|255] "-"  XGW_Body
 SG_ BCM_Immo_MHU_Byte_2 : 23|8@0+ (1,0) [0|255] "-"  XGW_Body
 SG_ BCM_Immo_MHU_Byte_3 : 31|8@0+ (1,0) [0|255] "-"  XGW_Body
 SG_ BCM_Immo_MHU_Byte_4 : 39|8@0+ (1,0) [0|255] "-"  XGW_Body
 SG_ BCM_Immo_MHU_Byte_5 : 47|8@0+ (1,0) [0|255] ""  XGW_Body
 SG_ BCM_Immo_MHU_Byte_6 : 55|8@0+ (1,0) [0|255] "-"  XGW_Body
 SG_ BCM_Immo_MHU_Byte_7 : 63|8@0+ (1,0) [0|255] "-"  XGW_Body

BO_ 924 ADAS_Request_BODY: 4 ADAS_Body
 SG_ ADAS_Body_Checksum : 7|8@0+ (1,0) [0|255] ""  BCM
 SG_ ADAS_Body_Alive : 11|4@0+ (1,0) [0|14] ""  BCM
 SG_ SECCAN_Request_BODY : 23|8@0+ (1,0) [0|255] ""  BCM
 SG_ ADAS_AHB_LBPos : 28|3@0+ (1,0) [0|7] "-"  BCM
 SG_ ADAS_AHB_RBPos : 31|3@0+ (1,0) [0|7] ""  BCM

BO_ 925 BCM_HighBeam_PosReq: 4 BCM
 SG_ BCM_AHB_Override : 17|2@0+ (1,0) [0|3] ""  ADAS_Body,LDM_L,LDM_R,XGW_Body
 SG_ BCM_ADAS_AHB_RBPos_feed : 20|3@0+ (1,0) [0|7] ""  ADAS_Body
 SG_ BCM_ADAS_AHB_LBPos_feed : 23|3@0+ (1,0) [0|7] ""  ADAS_Body
 SG_ SECCAN_BCM_AHB_L : 31|8@0+ (1,0) [0|255] ""  ADAS_Body

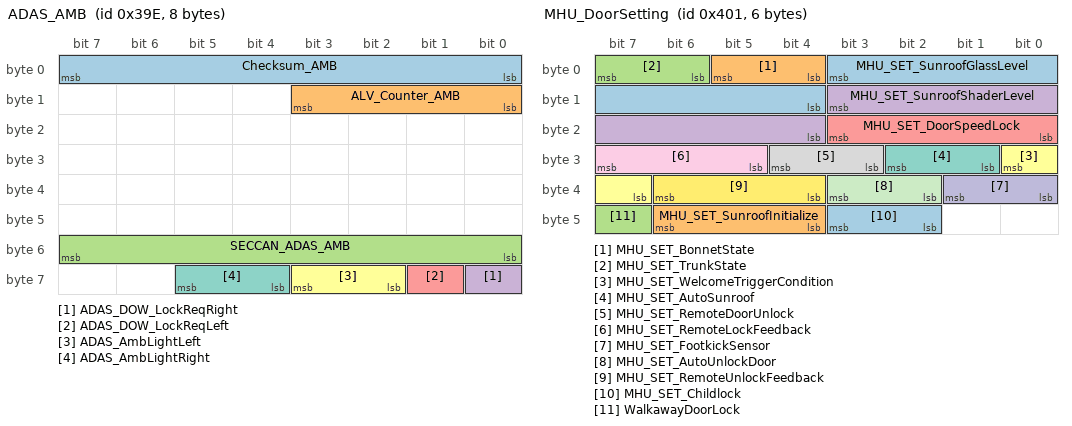
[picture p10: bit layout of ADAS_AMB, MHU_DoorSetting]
BO_ 926 ADAS_AMB: 8 ADAS_Body
 SG_ Checksum_AMB : 7|8@0+ (1,0) [0|255] ""  BCM
 SG_ ALV_Counter_AMB : 11|4@0+ (1,0) [0|14] ""  BCM
 SG_ SECCAN_ADAS_AMB : 55|8@0+ (1,0) [0|255] ""  BCM
 SG_ ADAS_DOW_LockReqRight : 56|1@0+ (1,0) [0|1] ""  BCM
 SG_ ADAS_DOW_LockReqLeft : 57|1@0+ (1,0) [0|1] ""  BCM
 SG_ ADAS_AmbLightLeft : 59|2@0+ (1,0) [0|3] ""  BCM
 SG_ ADAS_AmbLightRight : 61|2@0+ (1,0) [0|3] ""  BCM

BO_ 1015 MFS_Control_Button: 8 XGW_Body
 SG_ CHSKM_MFS_Control_Button : 7|8@0+ (1,0) [0|255] ""  BCM
 SG_ ALV_MFS_Control_Button : 11|4@0+ (1,0) [0|14] ""  BCM
 SG_ MFS_VoiceRecognitionOn_Off : 15|3@0+ (1,0) [0|4] "Bit"  BCM
 SG_ MFS_ISAControl : 17|2@0+ (1,0) [0|3] "Bit"  BCM
 SG_ MFS_CruiseSpeedIncrease : 20|3@0+ (1,0) [0|4] "Bit"  BCM
 SG_ MFS_TelephoneCall_EndCall : 23|3@0+ (1,0) [0|4] "Bit"  BCM
 SG_ MFS_LKAControl : 25|2@0+ (1,0) [0|3] "Bit"  BCM
 SG_ MFS_CruiseGapIncrease : 28|3@0+ (1,0) [0|4] "Bit"  BCM
 SG_ MFS_CruiseOn_Off : 31|3@0+ (1,0) [0|4] "Bit"  BCM
 SG_ MFS_CruiseGapDecrease : 34|3@0+ (1,0) [0|4] "Bit"  BCM
 SG_ MFS_CAN_RESControl : 36|2@0+ (1,0) [0|3] "-"  BCM
 SG_ MFS_CruiseSpeedDecrease : 39|3@0+ (1,0) [0|4] "Bit"  BCM
 SG_ MFS_M2Control : 41|2@0+ (1,0) [0|3] "Bit"  BCM
 SG_ MFS_SourseControl : 44|3@0+ (1,0) [0|4] "Bit"  BCM
 SG_ MFS_UpControl : 47|3@0+ (1,0) [0|4] "Bit"  BCM
 SG_ MFS_DownControl : 52|3@0+ (1,0) [0|4] "Bit"  BCM
 SG_ MFS_LeftControl : 55|3@0+ (1,0) [0|4] "Bit"  BCM
 SG_ MFS_Failure : 57|1@0+ (1,0) [0|1] "Bit"  BCM
 SG_ MFS_RightControl : 60|3@0+ (1,0) [0|4] "Bit"  BCM
 SG_ MFS_OK_Control : 63|3@0+ (1,0) [0|4] "Bit"  BCM

BO_ 1025 MHU_DoorSetting: 6 XGW_Body
 SG_ MHU_SET_SunroofGlassLevel : 3|8@0+ (1,0) [0|255] "%"  BCM
 SG_ MHU_SET_BonnetState : 5|2@0+ (1,0) [0|3] "-"  BCM
 SG_ MHU_SET_TrunkState : 7|2@0+ (1,0) [0|3] "-"  BCM
 SG_ MHU_SET_SunroofShaderLevel : 11|8@0+ (1,0) [0|255] "%"  BCM
 SG_ MHU_SET_DoorSpeedLock : 19|4@0+ (1,0) [0|7] ""  BCM
 SG_ MHU_SET_WelcomeTriggerCondition : 24|2@0+ (1,0) [0|3] ""  BCM
 SG_ MHU_SET_AutoSunroof : 26|2@0+ (1,0) [0|3] ""  BCM
 SG_ MHU_SET_RemoteDoorUnlock : 28|2@0+ (1,0) [0|3] "-"  BCM
 SG_ MHU_SET_RemoteLockFeedback : 31|3@0+ (1,0) [0|7] "-"  BCM
 SG_ MHU_SET_FootkickSensor : 33|2@0+ (1,0) [0|3] "-"  BCM
 SG_ MHU_SET_AutoUnlockDoor : 35|2@0+ (1,0) [0|3] ""  BCM
 SG_ MHU_SET_RemoteUnlockFeedback : 38|3@0+ (1,0) [0|7] ""  BCM
 SG_ MHU_SET_Childlock : 43|2@0+ (1,0) [0|3] ""  BCM
 SG_ MHU_SET_SunroofInitialize : 46|3@0+ (1,0) [0|7] ""  BCM
 SG_ WalkawayDoorLock : 47|1@0+ (1,0) [0|1] "" BCM

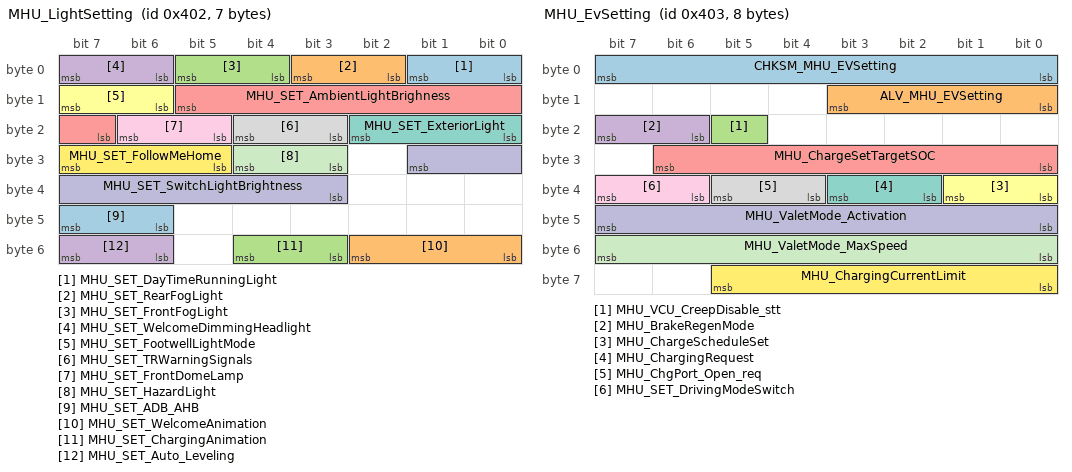
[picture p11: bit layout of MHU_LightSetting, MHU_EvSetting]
BO_ 1026 MHU_LightSetting: 7 XGW_Body
 SG_ MHU_SET_DayTimeRunningLight : 1|2@0+ (1,0) [0|3] "-"  BCM,LDM_L,LDM_R
 SG_ MHU_SET_RearFogLight : 3|2@0+ (1,0) [0|3] ""  BCM,LDM_L,LDM_R
 SG_ MHU_SET_FrontFogLight : 5|2@0+ (1,0) [0|3] ""  BCM,LDM_L,LDM_R
 SG_ MHU_SET_WelcomeDimmingHeadlight : 7|2@0+ (1,0) [0|3] ""  BCM,LDM_L,LDM_R
 SG_ MHU_SET_AmbientLightBrighness : 13|7@0+ (1,0) [0|100] "%"  BCM,LDM_L,LDM_R
 SG_ MHU_SET_FootwellLightMode : 15|2@0+ (1,0) [0|3] "-"  BCM,LDM_L,LDM_R
 SG_ MHU_SET_ExteriorLight : 18|3@0+ (1,0) [0|7] ""  BCM,LDM_L,LDM_R
 SG_ MHU_SET_TRWarningSignals : 20|2@0+ (1,0) [0|3] "" BCM
 SG_ MHU_SET_FrontDomeLamp : 22|2@0+ (1,0) [0|3] ""  BCM,LDM_L,LDM_R
 SG_ MHU_SET_SwitchLightBrightness : 25|7@0+ (1,0) [0|100] "%"  BCM,LDM_L,LDM_R
 SG_ MHU_SET_HazardLight : 28|2@0+ (1,0) [0|3] ""  BCM
 SG_ MHU_SET_FollowMeHome : 31|3@0+ (1,0) [0|7] ""  BCM,LDM_L,LDM_R
 SG_ MHU_SET_ADB_AHB : 47|2@0+ (1,0) [0|3] ""  BCM,LDM_L
 SG_ MHU_SET_WelcomeAnimation : 50|3@0+ (1,0) [0|5] ""  BCM
 SG_ MHU_SET_ChargingAnimation : 52|2@0+ (1,0) [0|3] ""  BCM
 SG_ MHU_SET_Auto_Leveling : 55|2@0+ (1,0) [0|3] "-"  BCM,LDM_L

BO_ 1027 MHU_EvSetting: 8 XGW_Body
 SG_ CHKSM_MHU_EVSetting : 7|8@0+ (1,0) [0|255] ""  BCM
 SG_ ALV_MHU_EVSetting : 11|4@0+ (1,0) [0|14] ""  BCM
 SG_ MHU_VCU_CreepDisable_stt : 21|1@0+ (1,0) [0|1] ""  BCM
 SG_ MHU_BrakeRegenMode : 23|2@0+ (1,0) [0|3] ""  DUMMY_ECU
 SG_ MHU_ChargeSetTargetSOC : 30|7@0+ (1,0) [10|100] "%"  DUMMY_ECU
 SG_ MHU_ChargeScheduleSet : 33|2@0+ (1,0) [0|3] ""  DUMMY_ECU
 SG_ MHU_ChargingRequest : 35|2@0+ (1,0) [0|3] "-"  BCM,DUMMY_ECU
 SG_ MHU_ChgPort_Open_req : 37|2@0+ (1,0) [0|3] "-"  BCM
 SG_ MHU_SET_DrivingModeSwitch : 39|2@0+ (1,0) [0|3] "-"  BCM
 SG_ MHU_ValetMode_Activation : 47|8@0+ (1,0) [0|255] ""  DUMMY_ECU
 SG_ MHU_ValetMode_MaxSpeed : 55|8@0+ (1,0) [0|255] "km/h"  DUMMY_ECU
 SG_ MHU_ChargingCurrentLimit : 61|6@0+ (1,0) [0|63] "A"  BCM

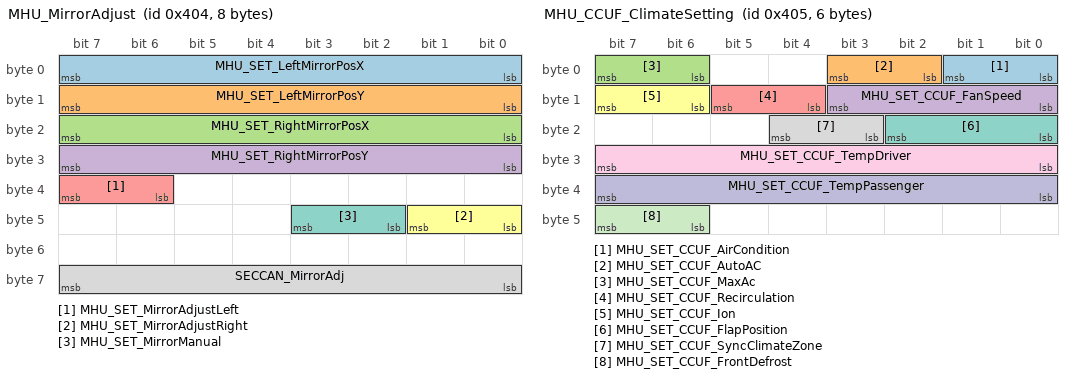
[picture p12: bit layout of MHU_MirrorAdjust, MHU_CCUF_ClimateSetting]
BO_ 1028 MHU_MirrorAdjust: 8 XGW_Body
 SG_ MHU_SET_LeftMirrorPosX : 7|8@0+ (1,-15) [-15|15] "deg"  BCM
 SG_ MHU_SET_LeftMirrorPosY : 15|8@0+ (1,-15) [-15|15] "deg"  BCM
 SG_ MHU_SET_RightMirrorPosX : 23|8@0+ (1,-15) [-15|15] "deg"  BCM
 SG_ MHU_SET_RightMirrorPosY : 31|8@0+ (1,-15) [-15|15] "deg"  BCM
 SG_ MHU_SET_MirrorAdjustLeft : 39|2@0+ (1,0) [0|3] "-"  BCM
 SG_ MHU_SET_MirrorAdjustRight : 41|2@0+ (1,0) [0|3] "-"  BCM
 SG_ MHU_SET_MirrorManual : 43|2@0+ (1,0) [0|3] ""  BCM
 SG_ SECCAN_MirrorAdj : 63|8@0+ (1,0) [0|255] ""  BCM

BO_ 1029 MHU_CCUF_ClimateSetting: 6 XGW_Body
 SG_ MHU_SET_CCUF_AirCondition : 1|2@0+ (1,0) [0|3] ""  CCU_F
 SG_ MHU_SET_CCUF_AutoAC : 3|2@0+ (1,0) [0|3] ""  CCU_F
 SG_ MHU_SET_CCUF_MaxAc : 7|2@0+ (1,0) [0|3] ""  CCU_F
 SG_ MHU_SET_CCUF_FanSpeed : 11|4@0+ (1,0) [0|7] "-"  CCU_F
 SG_ MHU_SET_CCUF_Recirculation : 13|2@0+ (1,0) [0|3] ""  CCU_F
 SG_ MHU_SET_CCUF_Ion : 15|2@0+ (1,0) [0|3] "-"  CCU_F
 SG_ MHU_SET_CCUF_FlapPosition : 18|3@0+ (1,0) [0|7] "-"  CCU_F
 SG_ MHU_SET_CCUF_SyncClimateZone : 20|2@0+ (1,0) [0|3] "-"  CCU_F
 SG_ MHU_SET_CCUF_TempDriver : 31|8@0+ (0.5,0) [16|32] "Degree C"  CCU_F
 SG_ MHU_SET_CCUF_TempPassenger : 39|8@0+ (0.5,0) [16|32] "Degree C"  CCU_F
 SG_ MHU_SET_CCUF_FrontDefrost : 47|2@0+ (1,0) [0|3] ""  CCU_F

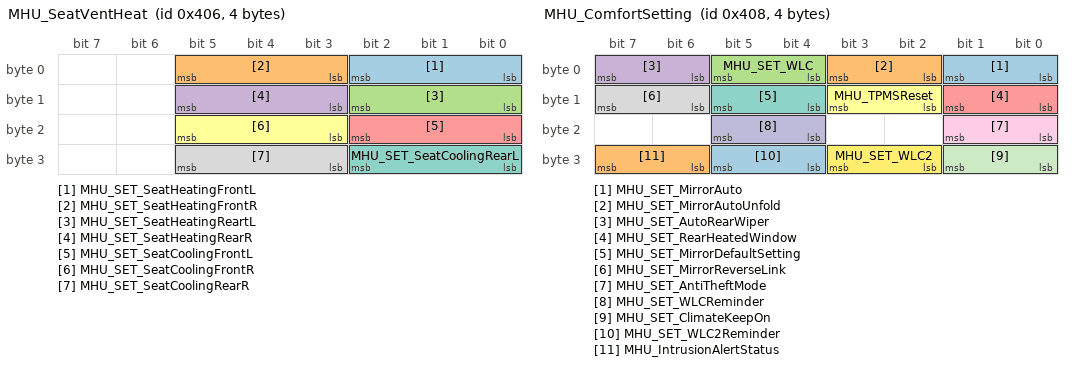
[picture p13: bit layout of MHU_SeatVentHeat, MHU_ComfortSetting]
BO_ 1030 MHU_SeatVentHeat: 4 XGW_Body
 SG_ MHU_SET_SeatHeatingFrontL : 2|3@0+ (1,0) [0|7] "-"  SHVU_F
 SG_ MHU_SET_SeatHeatingFrontR : 5|3@0+ (1,0) [0|7] "-"  SHVU_F
 SG_ MHU_SET_SeatHeatingReartL : 10|3@0+ (1,0) [0|7] "-"  SHVU_R
 SG_ MHU_SET_SeatHeatingRearR : 13|3@0+ (1,0) [0|7] "-"  SHVU_R
 SG_ MHU_SET_SeatCoolingFrontL : 18|3@0+ (1,0) [0|7] "-"  SHVU_F
 SG_ MHU_SET_SeatCoolingFrontR : 21|3@0+ (1,0) [0|7] ""  SHVU_F
 SG_ MHU_SET_SeatCoolingRearL : 26|3@0+ (1,0) [0|7] ""  SHVU_R
 SG_ MHU_SET_SeatCoolingRearR : 29|3@0+ (1,0) [0|7] "-"  SHVU_R

BO_ 1032 MHU_ComfortSetting: 4 XGW_Body
 SG_ MHU_SET_MirrorAuto : 1|2@0+ (1,0) [0|3] ""  BCM
 SG_ MHU_SET_MirrorAutoUnfold : 3|2@0+ (1,0) [0|3] ""  BCM
 SG_ MHU_SET_WLC : 5|2@0+ (1,0) [0|3] "-"  BCM
 SG_ MHU_SET_AutoRearWiper : 7|2@0+ (1,0) [0|3] "-"  BCM
 SG_ MHU_SET_RearHeatedWindow : 9|2@0+ (1,0) [0|3] ""  BCM
 SG_ MHU_TPMSReset : 11|2@0+ (1,0) [0|3] ""  BCM
 SG_ MHU_SET_MirrorDefaultSetting : 13|2@0+ (1,0) [0|3] ""  BCM
 SG_ MHU_SET_MirrorReverseLink : 15|2@0+ (1,0) [0|3] "-"  BCM
 SG_ MHU_SET_AntiTheftMode : 17|2@0+ (1,0) [0|3] ""  BCM
 SG_ MHU_SET_WLCReminder : 21|2@0+ (1,0) [0|3] ""  BCM
 SG_ MHU_SET_ClimateKeepOn : 25|2@0+ (1,0) [0|3] ""  BCM
 SG_ MHU_SET_WLC2 : 27|2@0+ (1,0) [0|3] "-"  BCM
 SG_ MHU_SET_WLC2Reminder : 29|2@0+ (1,0) [0|3] "-"  BCM
 SG_ MHU_IntrusionAlertStatus : 31|2@0+ (1,0) [0|3] "-"  BCM

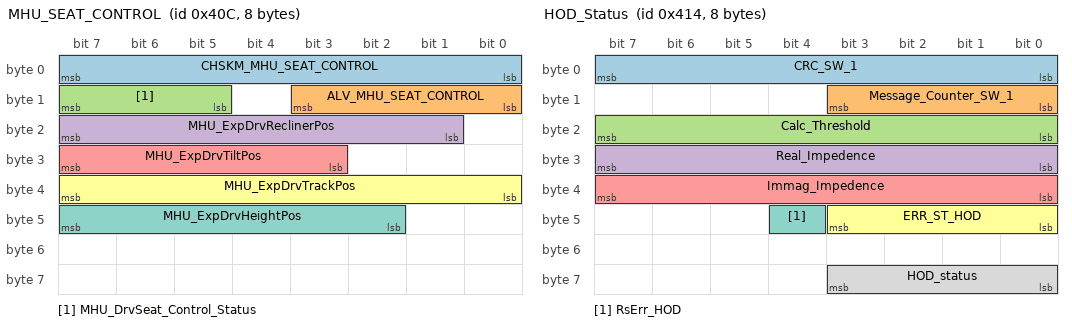
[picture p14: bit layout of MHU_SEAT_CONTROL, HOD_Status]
BO_ 1036 MHU_SEAT_CONTROL: 8 XGW_Body
 SG_ CHSKM_MHU_SEAT_CONTROL : 7|8@0+ (1,0) [0|255] ""  PSM_D
 SG_ ALV_MHU_SEAT_CONTROL : 11|4@0+ (1,0) [0|14] ""  PSM_D
 SG_ MHU_DrvSeat_Control_Status : 15|3@0+ (1,0) [0|7] "-"  PSM_D
 SG_ MHU_ExpDrvReclinerPos : 23|7@0+ (1,0) [0|127] "degree"  PSM_D
 SG_ MHU_ExpDrvTiltPos : 31|5@0+ (1,0) [0|31] "mm"  PSM_D
 SG_ MHU_ExpDrvTrackPos : 39|8@0+ (1,0) [0|255] "mm"  PSM_D
 SG_ MHU_ExpDrvHeightPos : 47|6@0+ (1,0) [0|63] "mm"  PSM_D

BO_ 1037 MHU_DIGIT_SPEED: 5 XGW_Body
 SG_ CHKSM_MHU_DIGIT_SPEED : 7|8@0+ (1,0) [0|255] ""  ACM
 SG_ ALV_MHU_DIGIT_SPEED : 11|4@0+ (1,0) [0|14] ""  ACM
 SG_ MHU_DigitSpeed : 23|9@0+ (1,0) [0|300] "km/h"  ACM

BO_ 1044 HOD_Status: 8 XGW_Body
 SG_ CRC_SW_1 : 7|8@0+ (1,0) [0|255] ""  ADAS_Body
 SG_ Message_Counter_SW_1 : 11|4@0+ (1,0) [0|14] ""  ADAS_Body
 SG_ Calc_Threshold : 23|8@0+ (1,0) [0|255] ""  ADAS_Body
 SG_ Real_Impedence : 31|8@0+ (1,0) [0|255] ""  ADAS_Body
 SG_ Immag_Impedence : 39|8@0+ (1,0) [0|255] ""  ADAS_Body
 SG_ ERR_ST_HOD : 43|4@0+ (1,0) [0|15] ""  ADAS_Body
 SG_ RsErr_HOD : 44|1@0+ (1,0) [0|1] ""  ADAS_Body
 SG_ HOD_status : 59|4@0+ (1,0) [0|15] ""  ADAS_Body

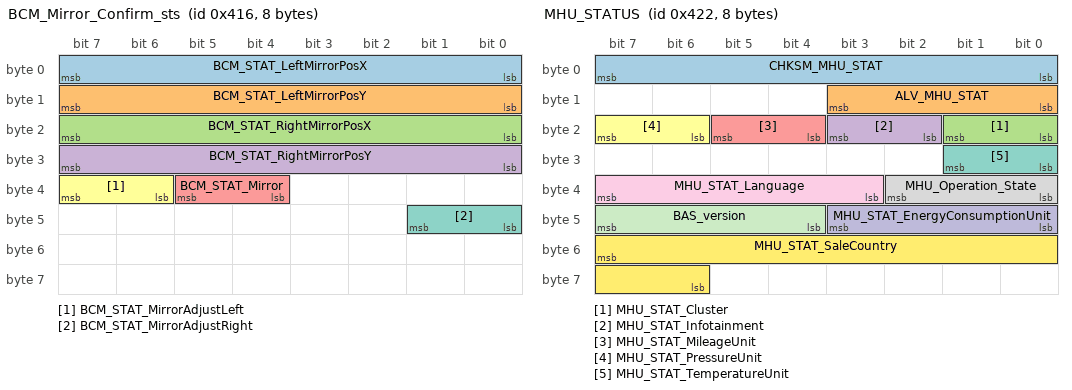
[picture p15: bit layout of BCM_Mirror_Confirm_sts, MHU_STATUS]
BO_ 1046 BCM_Mirror_Confirm_sts: 8 BCM
 SG_ BCM_STAT_LeftMirrorPosX : 7|8@0+ (1,-15) [-15|15] "deg"  ADAS_Body,XGW_Body
 SG_ BCM_STAT_LeftMirrorPosY : 15|8@0+ (1,-15) [-15|15] "deg"  ADAS_Body,XGW_Body
 SG_ BCM_STAT_RightMirrorPosX : 23|8@0+ (1,-15) [-15|15] "deg"  ADAS_Body,XGW_Body
 SG_ BCM_STAT_RightMirrorPosY : 31|8@0+ (1,-15) [-15|15] "deg"  ADAS_Body,XGW_Body
 SG_ BCM_STAT_Mirror : 37|2@0+ (1,0) [0|3] ""  ADAS_Body,XGW_Body
 SG_ BCM_STAT_MirrorAdjustLeft : 39|2@0+ (1,0) [0|3] "-"  ADAS_Body,XGW_Body
 SG_ BCM_STAT_MirrorAdjustRight : 41|2@0+ (1,0) [0|3] ""  ADAS_Body,XGW_Body

BO_ 1049 SHVU_F_Confirm_Sts: 2 SHVU_F
 SG_ SHVU_STAT_SeatHeatingFrontL : 2|3@0+ (1,0) [0|7] "-"  XGW_Body
 SG_ SHVU_STAT_SeatHeatingFrontR : 5|3@0+ (1,0) [0|7] "-"  XGW_Body
 SG_ SHVU_STAT_SeatCoolingFrontL : 10|3@0+ (1,0) [0|7] "-"  XGW_Body
 SG_ SHVU_STAT_SeatCoolingFrontR : 13|3@0+ (1,0) [0|7] ""  XGW_Body
 SG_ SHVU_STAT_FrontSeatVentSts : 15|2@0+ (1,0) [0|3] ""  XGW_Body

BO_ 1050 SHVU_R_Confirm_Sts: 2 SHVU_R
 SG_ SHVU_STAT_SeatCoolingRearL : 2|3@0+ (1,0) [0|7] "-"  XGW_Body
 SG_ SHVU_STAT_SeatCoolingRearR : 5|3@0+ (1,0) [0|7] ""  XGW_Body
 SG_ SHVU_STAT_SeatHeatingReartL : 10|3@0+ (1,0) [0|7] ""  XGW_Body
 SG_ SHVU_STAT_SeatHeatingRearR : 13|3@0+ (1,0) [0|7] ""  XGW_Body
 SG_ SHVU_STAT_RearSeatVentSts : 15|2@0+ (1,0) [0|3] ""  XGW_Body

BO_ 1052 PSM_SEAT_POSITION: 3 PSM_D
 SG_ CHKSM_PSM_SEAT_POSITION : 7|8@0+ (1,0) [0|255] ""  ACM,XGW_Body
 SG_ AVL_PSM_SEAT_POSITION : 11|4@0+ (1,0) [0|14] "-"  ACM,XGW_Body
 SG_ PSM_Seat_track_pos_Dri : 19|2@0+ (1,0) [0|3] ""  ACM,XGW_Body
 SG_ PSM_Seat_track_posPas : 21|2@0+ (1,0) [0|3] ""  ACM,XGW_Body

BO_ 1053 BCM_Comfort_Confirm_sts: 8 BCM
 SG_ BCM_STAT_AutoRearWiper : 1|2@0+ (1,0) [0|3] "-"  XGW_Body
 SG_ BCM_STAT_MirrorFoldSetting : 3|2@0+ (1,0) [0|3] ""  XGW_Body
 SG_ BCM_STAT_IMMO_KeyfobID2 : 7|3@0+ (1,0) [0|7] ""  XGW_Body
 SG_ BCM_STAT_MirrorAutoUnfold : 9|2@0+ (1,0) [0|3] "-"  XGW_Body
 SG_ BCM_STAT_MirrorReverseLink : 11|2@0+ (1,0) [0|3] ""  XGW_Body
 SG_ BCM_STAT_MirrorDefaultSTATting : 13|2@0+ (1,0) [0|3] "-"  XGW_Body
 SG_ BCM_STAT_WelcomeTriggerCondition : 15|2@0+ (1,0) [0|3] ""  XGW_Body
 SG_ BCM_STAT_FrontDomeLamp : 17|2@0+ (1,0) [0|3] "-"  XGW_Body
 SG_ BCM_STAT_FollowMeHome : 20|3@0+ (1,0) [0|7] "-"  XGW_Body
 SG_ BCM_STAT_ExteriorLight : 23|3@0+ (1,0) [0|7] "-"  XGW_Body
 SG_ BCM_STAT_RemoteLockFeedback : 26|3@0+ (1,0) [0|7] "-"  XGW_Body
 SG_ BCM_STAT_RemoteDoorUnlock : 28|2@0+ (1,0) [0|3] ""  XGW_Body
 SG_ BCM_STAT_AutoDoorUnlock : 30|2@0+ (1,0) [0|3] ""  XGW_Body
 SG_ BCM_STAT_WalkawayDoorLock : 31|1@0+ (1,0) [0|1] "" XGW_Body
 SG_ BCM_STAT_AmbientLightBrighness : 39|7@0+ (1,0) [0|100] "%"  XGW_Body
 SG_ BCM_STAT_WiperServiceMode : 42|2@0+ (1,0) [0|3] ""  XGW_Body
 SG_ BCM_STAT_IMMO_KeyfobID : 45|2@0+ (1,0) [0|3] ""  XGW_Body
 SG_ BCM_STAT_RearHeatedWindowMirror : 47|2@0+ (1,0) [0|3] ""  XGW_Body
 SG_ BCM_STAT_AntiTheftMode : 50|3@0+ (1,0) [0|7] "-"  XGW_Body
 SG_ BCM_STAT_ClimateKeepOnSts : 53|2@0+ (1,0) [0|3] ""  XGW_Body,CCU_F,CCU_R
 SG_ BCM_STAT_FKSfeedback : 55|2@0+ (1,0) [0|3] ""  XGW_Body
 SG_ SECCAN_CmftCnfrm : 63|8@0+ (1,0) [0|255] ""  XGW_Body

BO_ 1055 OCS_PasSts: 3 OCS_P
 SG_ OCS_P_CHKSM : 7|8@0+ (1,0) [0|255] ""  ACM
 SG_ OCS_P_AVL : 11|4@0+ (1,0) [0|14] ""  ACM
 SG_ OCS_Passenger_class_stat : 17|2@0+ (1,0) [0|3] ""  ACM

BO_ 1058 MHU_STATUS: 8 XGW_Body
 SG_ CHKSM_MHU_STAT : 7|8@0+ (1,0) [0|255] ""  ADAS_Body,CCU_F,PSM_D,SHVU_F,SHVU_R
 SG_ ALV_MHU_STAT : 11|4@0+ (1,0) [0|14] ""  ADAS_Body,CCU_F,PSM_D,SHVU_F,SHVU_R
 SG_ MHU_STAT_Cluster : 17|2@0+ (1,0) [0|3] "-"  CCU_F
 SG_ MHU_STAT_Infotainment : 19|2@0+ (1,0) [0|3] ""  CCU_F,PSM_D,SHVU_F,SHVU_R
 SG_ MHU_STAT_MileageUnit : 21|2@0+ (1,0) [0|3] ""  ADAS_Body,CCU_F,PSM_D,SHVU_F,SHVU_R
 SG_ MHU_STAT_PressureUnit : 23|2@0+ (1,0) [0|3] "-"  CCU_F,PSM_D,SHVU_F,SHVU_R
 SG_ MHU_STAT_TemperatureUnit : 25|2@0+ (1,0) [0|3] "-"  CCU_F,PSM_D,SHVU_F,SHVU_R
 SG_ MHU_Operation_State : 34|3@0+ (1,0) [0|7] ""  CCU_F,PSM_D,SHVU_F,SHVU_R
 SG_ MHU_STAT_Language : 39|5@0+ (1,0) [0|31] "-"  CCU_F,PSM_D,SHVU_F,SHVU_R
 SG_ MHU_STAT_EnergyConsumptionUnit : 43|4@0+ (1,0) [0|15] "-"  CCU_F,PSM_D,SHVU_F,SHVU_R
 SG_ BAS_version : 47|4@0+ (1,0) [0|15] "" Vector__XXX
 SG_ MHU_STAT_SaleCountry : 55|10@0+ (1,0) [0|1023] "-"  CCU_F,PSM_D,SHVU_F,SHVU_R

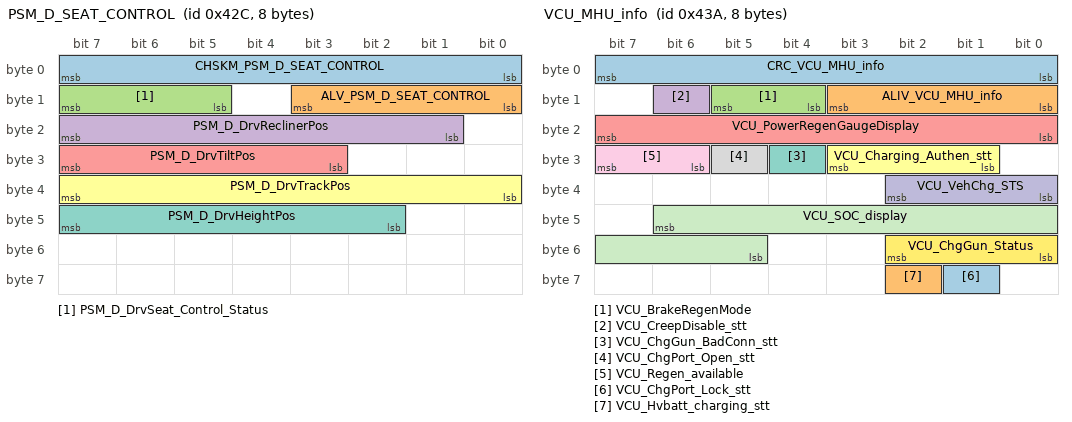
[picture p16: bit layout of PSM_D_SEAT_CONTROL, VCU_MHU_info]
BO_ 1068 PSM_D_SEAT_CONTROL: 8 PSM_D
 SG_ CHSKM_PSM_D_SEAT_CONTROL : 7|8@0+ (1,0) [0|255] ""  XGW_Body
 SG_ ALV_PSM_D_SEAT_CONTROL : 11|4@0+ (1,0) [0|14] ""  XGW_Body
 SG_ PSM_D_DrvSeat_Control_Status : 15|3@0+ (1,0) [0|7] ""  XGW_Body
 SG_ PSM_D_DrvReclinerPos : 23|7@0+ (1,0) [0|127] "degree"  XGW_Body
 SG_ PSM_D_DrvTiltPos : 31|5@0+ (1,0) [0|31] "mm"  XGW_Body
 SG_ PSM_D_DrvTrackPos : 39|8@0+ (1,0) [0|255] "mm"  XGW_Body
 SG_ PSM_D_DrvHeightPos : 47|6@0+ (1,0) [0|63] "mm"  XGW_Body

BO_ 1074 MHU_FOTA_STATUS: 8 XGW_Body
 SG_ MHU_FOTA_Checksum : 7|8@0+ (1,0) [0|255] ""  ACM,APM,ASU_Gateway,BCM,BCM_BPM,CCU_F,CCU_R,ETG,LDM_L,LDM_R,OCS_P,PSM_D,TRM
 SG_ MHU_FOTA_Alive_Counter : 11|4@0+ (1,0) [0|14] ""  ACM,APM,ASU_Gateway,BCM,BCM_BPM,CCU_F,CCU_R,ETG,LDM_L,LDM_R,OCS_P,PSM_D,TRM
 SG_ MHU_FOTA_State : 15|4@0+ (1,0) [0|14] "-"  ACM,APM,ASU_Gateway,BCM,BCM_BPM,CCU_F,CCU_R,ETG,LDM_L,LDM_R,OCS_P,PSM_D,TRM
 SG_ MHU_FOTA_Error_Code : 23|8@0+ (1,0) [0|255] "-"  ACM,APM,ASU_Gateway,BCM,BCM_BPM,CCU_F,CCU_R,ETG,LDM_L,LDM_R,OCS_P,PSM_D,TRM

BO_ 1077 BCM_SCM_LIN_Info: 1 BCM
 SG_ BCM_SCM_BC_Button : 1|2@0+ (1,0) [0|3] "-"  XGW_Body

BO_ 1082 VCU_MHU_info: 8 XGW_Body
 SG_ CRC_VCU_MHU_info : 7|8@0+ (1,0) [0|255] ""  BCM
 SG_ ALIV_VCU_MHU_info : 11|4@0+ (1,0) [0|14] ""  BCM
 SG_ VCU_BrakeRegenMode : 13|2@0+ (1,0) [0|3] "-"  BCM
 SG_ VCU_CreepDisable_stt : 14|1@0+ (1,0) [0|1] ""  BCM
 SG_ VCU_PowerRegenGaugeDisplay : 23|8@0+ (1,-100) [-100|100] "%"  BCM
 SG_ VCU_Charging_Authen_stt : 27|3@0+ (1,0) [0|7] "-"  BCM
 SG_ VCU_ChgGun_BadConn_stt : 28|1@0+ (1,0) [0|1] ""  BCM
 SG_ VCU_ChgPort_Open_stt : 29|1@0+ (1,0) [0|1] ""  BCM
 SG_ VCU_Regen_available : 31|2@0+ (1,0) [0|3] ""  BCM
 SG_ VCU_VehChg_STS : 34|3@0+ (1,0) [0|7] ""  BCM
 SG_ VCU_SOC_display : 46|10@0+ (0.1,0) [0|100] "%"  BCM
 SG_ VCU_ChgGun_Status : 50|3@0+ (1,0) [0|7] ""  BCM
 SG_ VCU_ChgPort_Lock_stt : 57|1@0+ (1,0) [0|1] ""  BCM
 SG_ VCU_Hvbatt_charging_stt : 58|1@0+ (1,0) [0|1] "-"  BCM

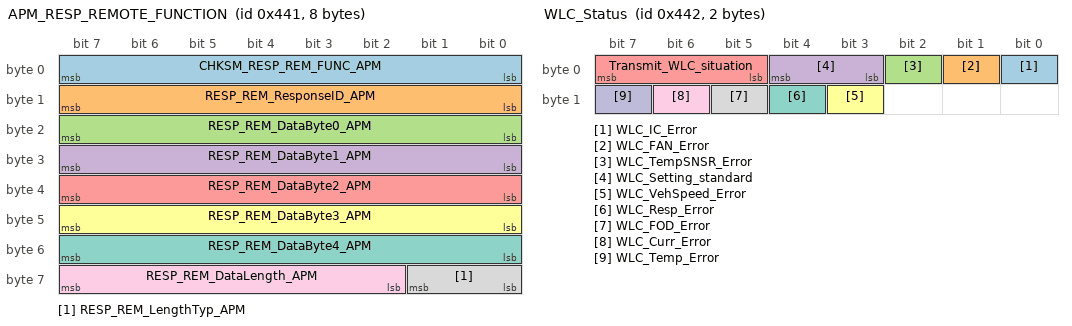
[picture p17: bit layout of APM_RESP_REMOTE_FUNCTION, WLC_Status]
BO_ 1089 APM_RESP_REMOTE_FUNCTION: 8 APM
 SG_ CHKSM_RESP_REM_FUNC_APM : 7|8@0+ (1,0) [0|255] ""  XGW_Body
 SG_ RESP_REM_ResponseID_APM : 15|8@0+ (1,0) [0|254] ""  XGW_Body
 SG_ RESP_REM_DataByte0_APM : 23|8@0+ (1,0) [0|254] ""  XGW_Body
 SG_ RESP_REM_DataByte1_APM : 31|8@0+ (1,0) [0|254] ""  XGW_Body
 SG_ RESP_REM_DataByte2_APM : 39|8@0+ (1,0) [0|254] ""  XGW_Body
 SG_ RESP_REM_DataByte3_APM : 47|8@0+ (1,0) [0|254] ""  XGW_Body
 SG_ RESP_REM_DataByte4_APM : 55|8@0+ (1,0) [0|254] ""  XGW_Body
 SG_ RESP_REM_LengthTyp_APM : 57|2@0+ (1,0) [0|3] ""  XGW_Body
 SG_ RESP_REM_DataLength_APM : 63|6@0+ (1,0) [0|63] ""  XGW_Body

BO_ 1090 WLC_Status: 2 BCM
 SG_ WLC_IC_Error : 0|1@0+ (1,0) [0|1] ""  XGW_Body
 SG_ WLC_FAN_Error : 1|1@0+ (1,0) [0|1] "-"  XGW_Body
 SG_ WLC_TempSNSR_Error : 2|1@0+ (1,0) [0|1] "-"  XGW_Body
 SG_ WLC_Setting_standard : 4|2@0+ (1,0) [0|3] "-"  XGW_Body
 SG_ Transmit_WLC_situation : 7|3@0+ (1,0) [0|7] ""  XGW_Body
 SG_ WLC_VehSpeed_Error : 11|1@0+ (1,0) [0|1] ""  XGW_Body
 SG_ WLC_Resp_Error : 12|1@0+ (1,0) [0|1] ""  XGW_Body
 SG_ WLC_FOD_Error : 13|1@0+ (1,0) [0|1] "-"  XGW_Body
 SG_ WLC_Curr_Error : 14|1@0+ (1,0) [0|1] "-"  XGW_Body
 SG_ WLC_Temp_Error : 15|1@0+ (1,0) [0|1] ""  XGW_Body

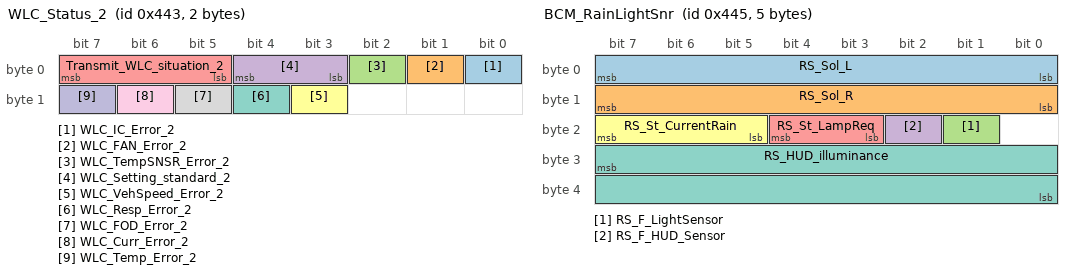
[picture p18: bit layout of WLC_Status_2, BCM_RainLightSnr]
BO_ 1091 WLC_Status_2: 2 BCM
 SG_ WLC_IC_Error_2 : 0|1@0+ (1,0) [0|1] "-"  XGW_Body
 SG_ WLC_FAN_Error_2 : 1|1@0+ (1,0) [0|1] ""  XGW_Body
 SG_ WLC_TempSNSR_Error_2 : 2|1@0+ (1,0) [0|1] "-"  XGW_Body
 SG_ WLC_Setting_standard_2 : 4|2@0+ (1,0) [0|3] ""  XGW_Body
 SG_ Transmit_WLC_situation_2 : 7|3@0+ (1,0) [0|7] ""  XGW_Body
 SG_ WLC_VehSpeed_Error_2 : 11|1@0+ (1,0) [0|1] ""  XGW_Body
 SG_ WLC_Resp_Error_2 : 12|1@0+ (1,0) [0|1] "-"  XGW_Body
 SG_ WLC_FOD_Error_2 : 13|1@0+ (1,0) [0|1] "-"  XGW_Body
 SG_ WLC_Curr_Error_2 : 14|1@0+ (1,0) [0|1] "-"  XGW_Body
 SG_ WLC_Temp_Error_2 : 15|1@0+ (1,0) [0|1] ""  XGW_Body

BO_ 1093 BCM_RainLightSnr: 5 BCM
 SG_ RS_Sol_L : 7|8@0+ (5,0) [0|1000] "W/m^2"  CCU_F,LDM_L,LDM_R,XGW_Body
 SG_ RS_Sol_R : 15|8@0+ (5,0) [0|1000] "W/m^2"  CCU_F,LDM_L,LDM_R,XGW_Body
 SG_ RS_F_LightSensor : 17|1@0+ (1,0) [0|1] ""  XGW_Body
 SG_ RS_F_HUD_Sensor : 18|1@0+ (1,0) [0|1] "cd/m2"  XGW_Body
 SG_ RS_St_LampReq : 20|2@0+ (1,0) [0|3] ""  CCU_F,LDM_L,LDM_R,XGW_Body
 SG_ RS_St_CurrentRain : 23|3@0+ (1,0) [0|7] ""  ADAS_Body,CCU_F,XGW_Body
 SG_ RS_HUD_illuminance : 31|16@0+ (1,0) [0|10000] "cd/m2"  ADAS_Body,XGW_Body

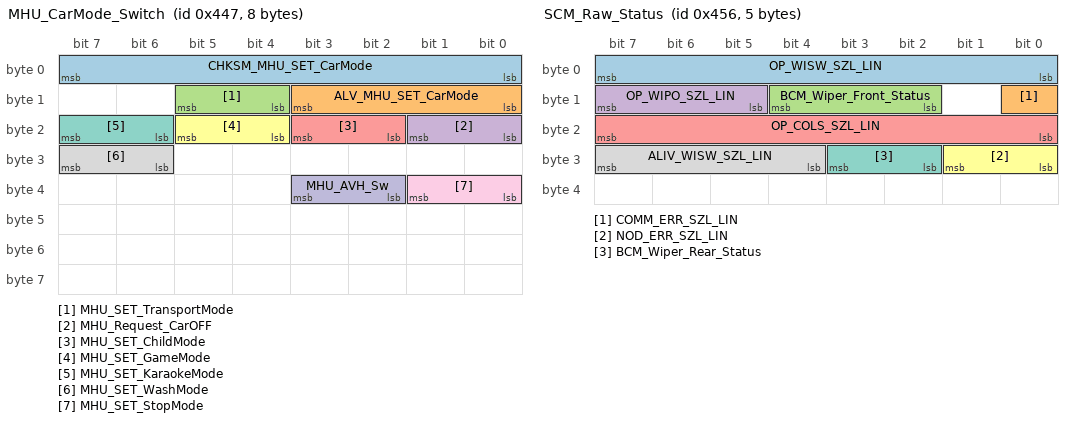
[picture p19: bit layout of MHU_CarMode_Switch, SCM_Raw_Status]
BO_ 1095 MHU_CarMode_Switch: 8 XGW_Body
 SG_ CHKSM_MHU_SET_CarMode : 7|8@0+ (1,0) [0|255] ""  BCM
 SG_ ALV_MHU_SET_CarMode : 11|4@0+ (1,0) [0|14] ""  BCM
 SG_ MHU_SET_TransportMode : 13|2@0+ (1,0) [0|3] "" BCM
 SG_ MHU_Request_CarOFF : 17|2@0+ (1,0) [0|3] "-"  BCM
 SG_ MHU_SET_ChildMode : 19|2@0+ (1,0) [0|3] ""  BCM
 SG_ MHU_SET_GameMode : 21|2@0+ (1,0) [0|3] ""  BCM
 SG_ MHU_SET_KaraokeMode : 23|2@0+ (1,0) [0|3] ""  BCM
 SG_ MHU_SET_WashMode : 31|2@0+ (1,0) [0|3] ""  BCM
 SG_ MHU_SET_StopMode : 33|2@0+ (1,0) [0|3] ""  BCM
 SG_ MHU_AVH_Sw : 35|2@0+ (1,0) [0|3] "" BCM

BO_ 1104 MHU_WindowSetting: 8 XGW_Body
 SG_ WindowLifterFrontL : 7|3@0+ (1,0) [0|7] ""  APM
 SG_ WindowLifterFrontR : 15|3@0+ (1,0) [0|7] ""  APM
 SG_ WindowLifterRearL : 23|3@0+ (1,0) [0|7] ""  APM
 SG_ WindowLifterRearR : 31|3@0+ (1,0) [0|7] ""  APM
 SG_ MHU_SET_WindowAutoClose : 39|3@0+ (1,0) [0|3] ""  APM

BO_ 1110 SCM_Raw_Status: 5 BCM
 SG_ OP_WISW_SZL_LIN : 7|8@0+ (1,0) [0|255] ""  ADAS_Body,XGW_Body
 SG_ COMM_ERR_SZL_LIN : 8|1@0+ (1,0) [0|1] ""  XGW_Body
 SG_ BCM_Wiper_Front_Status : 12|3@0+ (1,0) [0|7] ""  ADAS_Body,XGW_Body
 SG_ OP_WIPO_SZL_LIN : 15|3@0+ (1,0) [0|7] "-"  ADAS_Body,XGW_Body
 SG_ OP_COLS_SZL_LIN : 23|8@0+ (1,0) [0|255] "-"  ADAS_Body,XGW_Body
 SG_ NOD_ERR_SZL_LIN : 25|2@0+ (1,0) [0|3] ""  XGW_Body
 SG_ BCM_Wiper_Rear_Status : 27|2@0+ (1,0) [0|3] ""  XGW_Body
 SG_ ALIV_WISW_SZL_LIN : 31|4@0+ (1,0) [0|14] ""  ADAS_Body,XGW_Body

BO_ 1111 BCM_ALM_warning: 1 BCM
 SG_ AmbLight_Error_Z5 : 3|1@0+ (1,0) [0|1] "-"  XGW_Body
 SG_ AmbLight_Error_Z4 : 4|1@0+ (1,0) [0|1] ""  XGW_Body
 SG_ AmbLight_Error_Z3 : 5|1@0+ (1,0) [0|1] "-"  XGW_Body
 SG_ AmbLight_Error_Z2 : 6|1@0+ (1,0) [0|1] ""  XGW_Body
 SG_ AmbLight_Error_Z1 : 7|1@0+ (1,0) [0|1] ""  XGW_Body

BA_DEF_ BO_  "GenMsgSendType" ENUM  "Cyclic","NotUsed","NotUsed","NotUsed","NotUsed","NotUsed","NotUsed","IfActive","NoMsgSendType","NotUsed";
BA_DEF_ BO_  "GenMsgILSupport" ENUM  "No","Yes";
BA_DEF_ BO_  "DiagResponse" ENUM  "No","Yes";
BA_DEF_ BO_  "DiagRequest" ENUM  "No","Yes";
BA_DEF_ BO_  "NmAsrMessage" ENUM  "No","Yes";
BA_DEF_ BO_  "DiagState" ENUM  "No","Yes";
BA_DEF_ BO_  "DiagUudtResponse" ENUM  "False","True";
BA_DEF_ BO_  "GenMsgStartDelayTime" INT 0 65535;
BA_DEF_ BO_  "GenMsgDelayTime" INT 0 0;
BA_DEF_ BO_  "GenMsgNrOfRepetition" INT 0 0;
BA_DEF_ BO_  "GenMsgCycleTimeFast" INT 0 0;
BA_DEF_ BO_  "GenMsgCycleTime" INT 0 0;
BA_DEF_ SG_  "GenSigSendType" ENUM  "Cyclic","OnWrite","OnWriteWithRepetition","OnChange","OnChangeWithRepetition","IfActive","IfActiveWithRepetition","NoSigSendType","NotUsed","NotUsed","NotUsed","NotUsed","NotUsed";
BA_DEF_ SG_  "InvalidValue" STRING ;
BA_DEF_ SG_  "GenSigStartValue" INT 0 0;
BA_DEF_ SG_  "GenSigTimeoutTime_ALL" INT 0 65535;
BA_DEF_DEF_  "GenMsgSendType" "NoMsgSendType";
BA_DEF_DEF_  "GenMsgILSupport" "Yes";
BA_DEF_DEF_  "DiagResponse" "No";
BA_DEF_DEF_  "DiagRequest" "No";
BA_DEF_DEF_  "NmAsrMessage" "No";
BA_DEF_DEF_  "DiagState" "No";
BA_DEF_DEF_  "DiagUudtResponse" "False";
BA_DEF_DEF_  "GenMsgStartDelayTime" 0;
BA_DEF_DEF_  "GenMsgDelayTime" 0;
BA_DEF_DEF_  "GenMsgNrOfRepetition" 0;
BA_DEF_DEF_  "GenMsgCycleTimeFast" 0;
BA_DEF_DEF_  "GenMsgCycleTime" 0;
BA_DEF_DEF_  "GenSigSendType" "Cyclic";
BA_DEF_DEF_  "InvalidValue" "";
BA_DEF_DEF_  "GenSigStartValue" 0;
BA_DEF_DEF_  "GenSigTimeoutTime_ALL" 0;
BA_ "GenMsgCycleTime" BO_ 584 20;
BA_ "GenMsgSendType" BO_ 584 0;
BA_ "GenMsgCycleTime" BO_ 592 100;
BA_ "GenMsgILSupport" BO_ 592 0;
BA_ "GenMsgSendType" BO_ 592 0;
BA_ "GenMsgCycleTime" BO_ 593 20;
BA_ "GenMsgSendType" BO_ 593 0;
BA_ "GenMsgCycleTime" BO_ 596 20;
BA_ "GenMsgSendType" BO_ 596 0;
BA_ "GenMsgCycleTime" BO_ 597 20;
BA_ "GenMsgSendType" BO_ 597 0;
BA_ "GenMsgCycleTime" BO_ 598 50;
BA_ "GenMsgSendType" BO_ 598 0;
BA_ "GenMsgCycleTime" BO_ 618 200;
BA_ "GenMsgSendType" BO_ 618 0;
BA_ "GenMsgCycleTime" BO_ 641 20;
BA_ "GenMsgSendType" BO_ 641 0;
BA_ "GenMsgCycleTime" BO_ 649 20;
BA_ "GenMsgSendType" BO_ 649 0;
BA_ "GenMsgCycleTime" BO_ 654 100;
BA_ "GenMsgSendType" BO_ 654 0;
BA_ "GenMsgCycleTime" BO_ 657 20;
BA_ "GenMsgSendType" BO_ 657 0;
BA_ "GenMsgCycleTime" BO_ 673 80;
BA_ "GenMsgSendType" BO_ 673 0;
BA_ "GenMsgCycleTime" BO_ 674 80;
BA_ "GenMsgSendType" BO_ 674 0;
BA_ "GenMsgCycleTime" BO_ 676 1000;
BA_ "GenMsgCycleTime" BO_ 714 100;
BA_ "GenMsgSendType" BO_ 714 0;
BA_ "GenMsgCycleTime" BO_ 715 100;
BA_ "GenMsgSendType" BO_ 715 0;
BA_ "GenMsgCycleTime" BO_ 753 100;
BA_ "GenMsgSendType" BO_ 753 0;
BA_ "GenMsgCycleTime" BO_ 760 1000;
BA_ "GenMsgSendType" BO_ 760 0;
BA_ "GenMsgSendType" BO_ 768 0;
BA_ "GenMsgCycleTime" BO_ 768 1000;
BA_ "GenMsgCycleTimeFast" BO_ 768 20;
BA_ "GenMsgNrOfRepetition" BO_ 768 2;
BA_ "GenMsgCycleTime" BO_ 770 1000;
BA_ "GenMsgSendType" BO_ 770 0;
BA_ "GenMsgStartDelayTime" BO_ 770 25;
BA_ "GenMsgCycleTime" BO_ 773 100;
BA_ "GenMsgSendType" BO_ 773 0;
BA_ "GenMsgCycleTime" BO_ 774 100;
BA_ "GenMsgSendType" BO_ 774 0;
BA_ "GenMsgStartDelayTime" BO_ 774 5;
BA_ "GenMsgCycleTime" BO_ 775 1000;
BA_ "GenMsgSendType" BO_ 775 0;
BA_ "GenMsgSendType" BO_ 784 0;
BA_ "GenMsgCycleTime" BO_ 784 1000;
BA_ "GenMsgCycleTimeFast" BO_ 784 20;
BA_ "GenMsgNrOfRepetition" BO_ 784 2;
BA_ "GenMsgCycleTime" BO_ 806 100;
BA_ "GenMsgSendType" BO_ 806 0;
BA_ "GenMsgCycleTime" BO_ 808 1000;
BA_ "GenMsgSendType" BO_ 808 0;
BA_ "GenMsgCycleTime" BO_ 809 1000;
BA_ "GenMsgSendType" BO_ 809 0;
BA_ "GenMsgCycleTime" BO_ 812 200;
BA_ "GenMsgSendType" BO_ 812 0;
BA_ "GenMsgCycleTime" BO_ 816 100;
BA_ "GenMsgSendType" BO_ 816 0;
BA_ "GenMsgCycleTime" BO_ 880 300;
BA_ "GenMsgSendType" BO_ 880 0;
BA_ "GenMsgCycleTime" BO_ 896 1000;
BA_ "GenMsgSendType" BO_ 896 0;
BA_ "GenMsgCycleTime" BO_ 897 200;
BA_ "GenMsgSendType" BO_ 897 0;
BA_ "GenMsgDelayTime" BO_ 905 10;
BA_ "GenMsgDelayTime" BO_ 920 10;
BA_ "GenMsgDelayTime" BO_ 921 10;
BA_ "GenMsgCycleTimeFast" BO_ 922 100;
BA_ "GenMsgNrOfRepetition" BO_ 922 3;
BA_ "GenMsgCycleTimeFast" BO_ 923 100;
BA_ "GenMsgNrOfRepetition" BO_ 923 3;
BA_ "GenMsgCycleTime" BO_ 924 50;
BA_ "GenMsgSendType" BO_ 924 0;
BA_ "GenMsgCycleTime" BO_ 925 50;
BA_ "GenMsgSendType" BO_ 925 0;
BA_ "GenMsgCycleTime" BO_ 926 100;
BA_ "GenMsgSendType" BO_ 926 0;
BA_ "GenMsgCycleTime" BO_ 1015 1000;
BA_ "GenMsgCycleTimeFast" BO_ 1015 50;
BA_ "GenMsgNrOfRepetition" BO_ 1015 3;
BA_ "GenMsgSendType" BO_ 1015 0;
BA_ "GenMsgCycleTimeFast" BO_ 1025 100;
BA_ "GenMsgNrOfRepetition" BO_ 1025 3;
BA_ "GenMsgCycleTime" BO_ 1026 100;
BA_ "GenMsgCycleTimeFast" BO_ 1026 100;
BA_ "GenMsgNrOfRepetition" BO_ 1026 3;
BA_ "GenMsgSendType" BO_ 1026 0;
BA_ "GenMsgCycleTime" BO_ 1027 100;
BA_ "GenMsgSendType" BO_ 1027 0;
BA_ "GenMsgCycleTimeFast" BO_ 1028 100;
BA_ "GenMsgNrOfRepetition" BO_ 1028 3;
BA_ "GenMsgCycleTimeFast" BO_ 1029 50;
BA_ "GenMsgNrOfRepetition" BO_ 1029 3;
BA_ "GenMsgCycleTimeFast" BO_ 1030 100;
BA_ "GenMsgNrOfRepetition" BO_ 1030 3;
BA_ "GenMsgCycleTimeFast" BO_ 1032 100;
BA_ "GenMsgNrOfRepetition" BO_ 1032 3;
BA_ "GenMsgCycleTime" BO_ 1036 200;
BA_ "GenMsgSendType" BO_ 1036 0;
BA_ "GenMsgCycleTime" BO_ 1037 120;
BA_ "GenMsgSendType" BO_ 1037 0;
BA_ "GenMsgCycleTime" BO_ 1044 500;
BA_ "GenMsgSendType" BO_ 1044 0;
BA_ "GenMsgCycleTime" BO_ 1046 100;
BA_ "GenMsgSendType" BO_ 1046 0;
BA_ "GenMsgCycleTime" BO_ 1052 1000;
BA_ "GenMsgSendType" BO_ 1052 0;
BA_ "GenMsgCycleTime" BO_ 1053 100;
BA_ "GenMsgSendType" BO_ 1053 0;
BA_ "GenMsgCycleTime" BO_ 1055 500;
BA_ "GenMsgSendType" BO_ 1055 0;
BA_ "GenMsgCycleTime" BO_ 1058 1000;
BA_ "GenMsgSendType" BO_ 1058 0;
BA_ "GenMsgCycleTime" BO_ 1068 200;
BA_ "GenMsgSendType" BO_ 1068 0;
BA_ "GenMsgCycleTime" BO_ 1074 500;
BA_ "GenMsgSendType" BO_ 1074 0;
BA_ "GenMsgCycleTimeFast" BO_ 1077 100;
BA_ "GenMsgNrOfRepetition" BO_ 1077 3;
BA_ "GenMsgCycleTime" BO_ 1082 100;
BA_ "GenMsgSendType" BO_ 1082 0;
BA_ "GenMsgCycleTimeFast" BO_ 1089 100;
BA_ "GenMsgNrOfRepetition" BO_ 1089 3;
BA_ "GenMsgCycleTime" BO_ 1090 500;
BA_ "GenMsgSendType" BO_ 1090 0;
BA_ "GenMsgCycleTime" BO_ 1091 500;
BA_ "GenMsgSendType" BO_ 1091 0;
BA_ "GenMsgCycleTime" BO_ 1093 100;
BA_ "GenMsgSendType" BO_ 1093 0;
BA_ "GenMsgCycleTime" BO_ 1095 200;
BA_ "GenMsgSendType" BO_ 1095 0;
BA_ "GenMsgCycleTimeFast" BO_ 1104 100;
BA_ "GenMsgNrOfRepetition" BO_ 1104 3;
BA_ "GenSigStartValue" SG_ 584 NDoorFRHomeSignal 1;
BA_ "GenSigTimeoutTime_ALL" SG_ 584 NDoorFRHomeSignal 200;
BA_ "InvalidValue" SG_ 584 NDoorFRHomeSignal "null";
BA_ "GenSigStartValue" SG_ 584 NDoorFRSecondarySignal 1;
BA_ "GenSigTimeoutTime_ALL" SG_ 584 NDoorFRSecondarySignal 200;
BA_ "InvalidValue" SG_ 584 NDoorFRSecondarySignal "null";
BA_ "GenSigStartValue" SG_ 584 NDoorFRPrimarySignal 1;
BA_ "GenSigTimeoutTime_ALL" SG_ 584 NDoorFRPrimarySignal 200;
BA_ "InvalidValue" SG_ 584 NDoorFRPrimarySignal "null";
BA_ "GenSigStartValue" SG_ 584 NDoorFRClawSignal 1;
BA_ "GenSigTimeoutTime_ALL" SG_ 584 NDoorFRClawSignal 200;
BA_ "InvalidValue" SG_ 584 NDoorFRClawSignal "null";
BA_ "GenSigStartValue" SG_ 584 NDoorFRClawStatus 15;
BA_ "GenSigTimeoutTime_ALL" SG_ 584 NDoorFRClawStatus 200;
BA_ "InvalidValue" SG_ 584 NDoorFRClawStatus "null";
BA_ "GenSigTimeoutTime_ALL" SG_ 584 BDLFRResponseError 200;
BA_ "InvalidValue" SG_ 584 BDLFRResponseError "null";
BA_ "GenSigTimeoutTime_ALL" SG_ 584 NDoorFRCounter 200;
BA_ "InvalidValue" SG_ 584 NDoorFRCounter "null";
BA_ "GenSigTimeoutTime_ALL" SG_ 584 NDoorFROutsideHandleFailure 200;
BA_ "InvalidValue" SG_ 584 NDoorFROutsideHandleFailure "null";
BA_ "GenSigStartValue" SG_ 584 NDoorFROutsideHandleStatus 1;
BA_ "GenSigTimeoutTime_ALL" SG_ 584 NDoorFROutsideHandleStatus 200;
BA_ "InvalidValue" SG_ 584 NDoorFROutsideHandleStatus "null";
BA_ "GenSigTimeoutTime_ALL" SG_ 584 NDoorLatchFRFailure 200;
BA_ "InvalidValue" SG_ 584 NDoorLatchFRFailure "null";
BA_ "GenSigTimeoutTime_ALL" SG_ 592 CHSKM_BMS_VCU_THMReq 500;
BA_ "InvalidValue" SG_ 592 CHSKM_BMS_VCU_THMReq "null";
BA_ "GenSigTimeoutTime_ALL" SG_ 592 ALV_BMS_VCU_THMReq 500;
BA_ "InvalidValue" SG_ 592 ALV_BMS_VCU_THMReq "Fh";
BA_ "GenSigTimeoutTime_ALL" SG_ 592 BMS_FlowRate_Req 500;
BA_ "InvalidValue" SG_ 592 BMS_FlowRate_Req "FFh";
BA_ "GenSigTimeoutTime_ALL" SG_ 592 BMS_CoolPwrDemand 500;
BA_ "InvalidValue" SG_ 592 BMS_CoolPwrDemand "FFFh";
BA_ "GenSigTimeoutTime_ALL" SG_ 592 BMS_HeatPwrDemand 500;
BA_ "InvalidValue" SG_ 592 BMS_HeatPwrDemand "FFFh";
BA_ "GenSigTimeoutTime_ALL" SG_ 592 BMS_VCU_PTCOnOff_Req 500;
BA_ "InvalidValue" SG_ 592 BMS_VCU_PTCOnOff_Req "null";
BA_ "GenSigTimeoutTime_ALL" SG_ 592 BMS_VCU_ValveOnOff_Req 500;
BA_ "InvalidValue" SG_ 592 BMS_VCU_ValveOnOff_Req "null";
BA_ "GenSigTimeoutTime_ALL" SG_ 592 BMS_PreHeatCoolReq 500;
BA_ "InvalidValue" SG_ 592 BMS_PreHeatCoolReq "3h";
BA_ "GenSigTimeoutTime_ALL" SG_ 593 NDoorRLVehicleLocked 200;
BA_ "InvalidValue" SG_ 593 NDoorRLVehicleLocked "1h";
BA_ "GenSigTimeoutTime_ALL" SG_ 593 NDoorRLVehicleMoving 200;
BA_ "InvalidValue" SG_ 593 NDoorRLVehicleMoving "1h";
BA_ "GenSigTimeoutTime_ALL" SG_ 593 NDoorRLOpenInvRequested 200;
BA_ "InvalidValue" SG_ 593 NDoorRLOpenInvRequested "1h";
BA_ "GenSigStartValue" SG_ 593 NDoorRLOpenRequested 3;
BA_ "GenSigTimeoutTime_ALL" SG_ 593 NDoorRLOpenRequested 200;
BA_ "InvalidValue" SG_ 593 NDoorRLOpenRequested "2h";
BA_ "GenSigStartValue" SG_ 593 NDoorRLChildLocked 3;
BA_ "GenSigTimeoutTime_ALL" SG_ 593 NDoorRLChildLocked 200;
BA_ "InvalidValue" SG_ 593 NDoorRLChildLocked "1h";
BA_ "GenSigStartValue" SG_ 593 NDoorRLVehicleCrash 3;
BA_ "GenSigTimeoutTime_ALL" SG_ 593 NDoorRLVehicleCrash 200;
BA_ "InvalidValue" SG_ 593 NDoorRLVehicleCrash "1h";
BA_ "GenSigTimeoutTime_ALL" SG_ 593 NDoorRLCommandCounter 200;
BA_ "InvalidValue" SG_ 593 NDoorRLCommandCounter "null";
BA_ "GenSigTimeoutTime_ALL" SG_ 593 NDoorRLCloseInvRequested 200;
BA_ "InvalidValue" SG_ 593 NDoorRLCloseInvRequested "null";
BA_ "GenSigTimeoutTime_ALL" SG_ 593 NDoorRLCloseRequested 200;
BA_ "InvalidValue" SG_ 593 NDoorRLCloseRequested "null";
BA_ "GenSigTimeoutTime_ALL" SG_ 596 CRC_AVL_RPM_WHL_REAR 200;
BA_ "InvalidValue" SG_ 596 CRC_AVL_RPM_WHL_REAR "null";
BA_ "GenSigTimeoutTime_ALL" SG_ 596 ALIV_AVL_RPM_WHL_REAR 200;
BA_ "InvalidValue" SG_ 596 ALIV_AVL_RPM_WHL_REAR "Fh";
BA_ "GenSigStartValue" SG_ 596 AVL_RPM_WHL_RLH 32819;
BA_ "GenSigTimeoutTime_ALL" SG_ 596 AVL_RPM_WHL_RLH 200;
BA_ "InvalidValue" SG_ 596 AVL_RPM_WHL_RLH "null";
BA_ "GenSigStartValue" SG_ 596 AVL_RPM_WHL_RRH 32819;
BA_ "GenSigTimeoutTime_ALL" SG_ 596 AVL_RPM_WHL_RRH 200;
BA_ "InvalidValue" SG_ 596 AVL_RPM_WHL_RRH "null";
BA_ "GenSigTimeoutTime_ALL" SG_ 596 QU_AVL_RPM_WHL_RLH 200;
BA_ "InvalidValue" SG_ 596 QU_AVL_RPM_WHL_RLH "Fh";
BA_ "GenSigTimeoutTime_ALL" SG_ 596 QU_AVL_RPM_WHL_RRH 200;
BA_ "InvalidValue" SG_ 596 QU_AVL_RPM_WHL_RRH "Fh";
BA_ "GenSigTimeoutTime_ALL" SG_ 597 CRC_AVL_RPM_WHL_FRONT 200;
BA_ "InvalidValue" SG_ 597 CRC_AVL_RPM_WHL_FRONT "null";
BA_ "GenSigTimeoutTime_ALL" SG_ 597 ALIV_AVL_RPM_WHL_FRONT 200;
BA_ "InvalidValue" SG_ 597 ALIV_AVL_RPM_WHL_FRONT "Fh";
BA_ "GenSigStartValue" SG_ 597 AVL_RPM_WHL_FLH 32819;
BA_ "GenSigTimeoutTime_ALL" SG_ 597 AVL_RPM_WHL_FLH 200;
BA_ "InvalidValue" SG_ 597 AVL_RPM_WHL_FLH "null";
BA_ "GenSigStartValue" SG_ 597 AVL_RPM_WHL_FRH 32819;
BA_ "GenSigTimeoutTime_ALL" SG_ 597 AVL_RPM_WHL_FRH 200;
BA_ "InvalidValue" SG_ 597 AVL_RPM_WHL_FRH "null";
BA_ "GenSigTimeoutTime_ALL" SG_ 597 QU_AVL_RPM_WHL_FLH 200;
BA_ "InvalidValue" SG_ 597 QU_AVL_RPM_WHL_FLH "Fh";
BA_ "GenSigTimeoutTime_ALL" SG_ 597 QU_AVL_RPM_WHL_FRH 200;
BA_ "InvalidValue" SG_ 597 QU_AVL_RPM_WHL_FRH "Fh";
BA_ "GenSigTimeoutTime_ALL" SG_ 598 BCM_Animation_Req 200;
BA_ "InvalidValue" SG_ 598 BCM_Animation_Req "7h";
BA_ "GenSigTimeoutTime_ALL" SG_ 598 BCM_Charging_Sts 200;
BA_ "InvalidValue" SG_ 598 BCM_Charging_Sts "7h";
BA_ "GenSigTimeoutTime_ALL" SG_ 598 BCM_Lock_Sts 200;
BA_ "InvalidValue" SG_ 598 BCM_Lock_Sts "3h";
BA_ "GenSigTimeoutTime_ALL" SG_ 598 BCM_Panic_Status 200;
BA_ "InvalidValue" SG_ 598 BCM_Panic_Status "null";
BA_ "GenSigTimeoutTime_ALL" SG_ 598 BCM_Charging_SOC 200;
BA_ "InvalidValue" SG_ 598 BCM_Charging_SOC "Fh";
BA_ "GenSigTimeoutTime_ALL" SG_ 598 BCM_LeftPosLmpSts 200;
BA_ "InvalidValue" SG_ 598 BCM_LeftPosLmpSts "3h";
BA_ "GenSigTimeoutTime_ALL" SG_ 598 BCM_RightPosLmpSts 200;
BA_ "InvalidValue" SG_ 598 BCM_RightPosLmpSts "3h";
BA_ "GenSigTimeoutTime_ALL" SG_ 618 ALIV_ST_LCS_VEH 1000;
BA_ "InvalidValue" SG_ 618 ALIV_ST_LCS_VEH "Fh";
BA_ "GenSigTimeoutTime_ALL" SG_ 618 ST_ECU_ST_LCS_VEH 1000;
BA_ "InvalidValue" SG_ 618 ST_ECU_ST_LCS_VEH "null";
BA_ "GenSigTimeoutTime_ALL" SG_ 618 QU_FN_LCS_VEH 1000;
BA_ "InvalidValue" SG_ 618 QU_FN_LCS_VEH "null";
BA_ "GenSigStartValue" SG_ 641 NDoorRLHomeSignal 1;
BA_ "GenSigTimeoutTime_ALL" SG_ 641 NDoorRLHomeSignal 200;
BA_ "InvalidValue" SG_ 641 NDoorRLHomeSignal "null";
BA_ "GenSigStartValue" SG_ 641 NDoorRLSecondarySignal 1;
BA_ "GenSigTimeoutTime_ALL" SG_ 641 NDoorRLSecondarySignal 200;
BA_ "InvalidValue" SG_ 641 NDoorRLSecondarySignal "null";
BA_ "GenSigStartValue" SG_ 641 NDoorRLPrimarySignal 1;
BA_ "GenSigTimeoutTime_ALL" SG_ 641 NDoorRLPrimarySignal 200;
BA_ "InvalidValue" SG_ 641 NDoorRLPrimarySignal "null";
BA_ "GenSigStartValue" SG_ 641 NDoorRLClawSignal 1;
BA_ "GenSigTimeoutTime_ALL" SG_ 641 NDoorRLClawSignal 200;
BA_ "InvalidValue" SG_ 641 NDoorRLClawSignal "null";
BA_ "GenSigStartValue" SG_ 641 NDoorRLClawStatus 15;
BA_ "GenSigTimeoutTime_ALL" SG_ 641 NDoorRLClawStatus 200;
BA_ "InvalidValue" SG_ 641 NDoorRLClawStatus "Fh";
BA_ "GenSigTimeoutTime_ALL" SG_ 641 BDLRLResponseError 200;
BA_ "InvalidValue" SG_ 641 BDLRLResponseError "null";
BA_ "GenSigTimeoutTime_ALL" SG_ 641 NDoorRLCounter 200;
BA_ "InvalidValue" SG_ 641 NDoorRLCounter "null";
BA_ "GenSigTimeoutTime_ALL" SG_ 641 NDoorRLOutsideHandleFailure 200;
BA_ "InvalidValue" SG_ 641 NDoorRLOutsideHandleFailure "null";
BA_ "GenSigStartValue" SG_ 641 NDoorRLOutsideHandleStatus 1;
BA_ "GenSigTimeoutTime_ALL" SG_ 641 NDoorRLOutsideHandleStatus 200;
BA_ "InvalidValue" SG_ 641 NDoorRLOutsideHandleStatus "null";
BA_ "GenSigTimeoutTime_ALL" SG_ 641 NDoorLatchRLFailure 200;
BA_ "InvalidValue" SG_ 641 NDoorLatchRLFailure "null";
BA_ "GenSigTimeoutTime_ALL" SG_ 649 CHKSM_IDB_ZF2 200;
BA_ "InvalidValue" SG_ 649 CHKSM_IDB_ZF2 "0";
BA_ "GenSigTimeoutTime_ALL" SG_ 649 ALIVE_IDB_ZF2 200;
BA_ "InvalidValue" SG_ 649 ALIVE_IDB_ZF2 "Fh";
BA_ "GenSigTimeoutTime_ALL" SG_ 649 AxOutStatus 200;
BA_ "InvalidValue" SG_ 649 AxOutStatus "1h";
BA_ "GenSigStartValue" SG_ 649 QU_VYAW_VEH 8;
BA_ "GenSigTimeoutTime_ALL" SG_ 649 QU_VYAW_VEH 200;
BA_ "InvalidValue" SG_ 649 QU_VYAW_VEH "Fh";
BA_ "GenSigTimeoutTime_ALL" SG_ 649 AyOutStatus 200;
BA_ "InvalidValue" SG_ 649 AyOutStatus "1h";
BA_ "GenSigStartValue" SG_ 649 AcceleratorY 795;
BA_ "GenSigTimeoutTime_ALL" SG_ 649 AcceleratorY 200;
BA_ "InvalidValue" SG_ 649 AcceleratorY "FFFh";
BA_ "GenSigTimeoutTime_ALL" SG_ 649 AcceleratorX 200;
BA_ "InvalidValue" SG_ 649 AcceleratorX "FFFh";
BA_ "GenSigStartValue" SG_ 649 VYAW_VEH 32768;
BA_ "GenSigTimeoutTime_ALL" SG_ 649 VYAW_VEH 200;
BA_ "InvalidValue" SG_ 649 VYAW_VEH "FFFFh";
BA_ "GenSigTimeoutTime_ALL" SG_ 654 CHKSM_APM_WINDOW_POS 500;
BA_ "InvalidValue" SG_ 654 CHKSM_APM_WINDOW_POS "null";
BA_ "GenSigTimeoutTime_ALL" SG_ 654 ALV_APM_WINDOW_POS 500;
BA_ "InvalidValue" SG_ 654 ALV_APM_WINDOW_POS "Fh";
BA_ "GenSigTimeoutTime_ALL" SG_ 654 Window_PosFL 500;
BA_ "InvalidValue" SG_ 654 Window_PosFL "7h";
BA_ "GenSigTimeoutTime_ALL" SG_ 654 Window_Warning 500;
BA_ "InvalidValue" SG_ 654 Window_Warning "3h";
BA_ "GenSigTimeoutTime_ALL" SG_ 654 Wndow_PosRL 500;
BA_ "InvalidValue" SG_ 654 Wndow_PosRL "7h";
BA_ "GenSigTimeoutTime_ALL" SG_ 654 Window_PosFR 500;
BA_ "InvalidValue" SG_ 654 Window_PosFR "7h";
BA_ "GenSigTimeoutTime_ALL" SG_ 654 Global_close 500;
BA_ "InvalidValue" SG_ 654 Global_close "3h";
BA_ "GenSigTimeoutTime_ALL" SG_ 654 Global_open 500;
BA_ "InvalidValue" SG_ 654 Global_open "3h";
BA_ "GenSigTimeoutTime_ALL" SG_ 654 Window_PosRR 500;
BA_ "InvalidValue" SG_ 654 Window_PosRR "7h";
BA_ "GenSigTimeoutTime_ALL" SG_ 657 NDoorRRVehicleLocked 200;
BA_ "InvalidValue" SG_ 657 NDoorRRVehicleLocked "1h";
BA_ "GenSigTimeoutTime_ALL" SG_ 657 NDoorRRVehicleMoving 200;
BA_ "InvalidValue" SG_ 657 NDoorRRVehicleMoving "1h";
BA_ "GenSigTimeoutTime_ALL" SG_ 657 NDoorRROpenInvRequested 200;
BA_ "InvalidValue" SG_ 657 NDoorRROpenInvRequested "1h";
BA_ "GenSigStartValue" SG_ 657 NDoorRROpenRequested 3;
BA_ "GenSigTimeoutTime_ALL" SG_ 657 NDoorRROpenRequested 200;
BA_ "InvalidValue" SG_ 657 NDoorRROpenRequested "2h";
BA_ "GenSigStartValue" SG_ 657 NDoorRRChildLocked 3;
BA_ "GenSigTimeoutTime_ALL" SG_ 657 NDoorRRChildLocked 200;
BA_ "InvalidValue" SG_ 657 NDoorRRChildLocked "1h";
BA_ "GenSigStartValue" SG_ 657 NDoorRRVehicleCrash 3;
BA_ "GenSigTimeoutTime_ALL" SG_ 657 NDoorRRVehicleCrash 200;
BA_ "InvalidValue" SG_ 657 NDoorRRVehicleCrash "1h";
BA_ "GenSigTimeoutTime_ALL" SG_ 657 NDoorRRCommandCounter 200;
BA_ "InvalidValue" SG_ 657 NDoorRRCommandCounter "null";
BA_ "GenSigTimeoutTime_ALL" SG_ 657 NDoorRRCloseInvRequested 200;
BA_ "InvalidValue" SG_ 657 NDoorRRCloseInvRequested "null";
BA_ "GenSigTimeoutTime_ALL" SG_ 657 NDoorRRCloseRequested 200;
BA_ "InvalidValue" SG_ 657 NDoorRRCloseRequested "null";
BA_ "GenSigStartValue" SG_ 673 DrvSeatMsgStrLvl 1;
BA_ "GenSigTimeoutTime_ALL" SG_ 673 DrvSeatMsgStrLvl 800;
BA_ "InvalidValue" SG_ 673 DrvSeatMsgStrLvl "7h";
BA_ "GenSigStartValue" SG_ 673 PassSeatMsgStrLvl 1;
BA_ "GenSigTimeoutTime_ALL" SG_ 673 PassSeatMsgStrLvl 800;
BA_ "InvalidValue" SG_ 673 PassSeatMsgStrLvl "7h";
BA_ "GenSigStartValue" SG_ 673 RearDrvSeatMsgStrLvl 1;
BA_ "GenSigTimeoutTime_ALL" SG_ 673 RearDrvSeatMsgStrLvl 800;
BA_ "InvalidValue" SG_ 673 RearDrvSeatMsgStrLvl "7h";
BA_ "GenSigStartValue" SG_ 673 RearPassSeatMsgStrLvl 1;
BA_ "GenSigTimeoutTime_ALL" SG_ 673 RearPassSeatMsgStrLvl 800;
BA_ "InvalidValue" SG_ 673 RearPassSeatMsgStrLvl "7h";
BA_ "GenSigTimeoutTime_ALL" SG_ 673 DrvSeatMsgMode 800;
BA_ "InvalidValue" SG_ 673 DrvSeatMsgMode "7h";
BA_ "GenSigTimeoutTime_ALL" SG_ 673 PassSeatMsgMode 800;
BA_ "InvalidValue" SG_ 673 PassSeatMsgMode "7h";
BA_ "GenSigTimeoutTime_ALL" SG_ 673 RearDrvSeatMsgMode 800;
BA_ "InvalidValue" SG_ 673 RearDrvSeatMsgMode "7h";
BA_ "GenSigTimeoutTime_ALL" SG_ 673 RearPassSeatMsgMode 800;
BA_ "InvalidValue" SG_ 673 RearPassSeatMsgMode "7h";
BA_ "GenSigTimeoutTime_ALL" SG_ 674 DrvSeatMsgModeStat 800;
BA_ "InvalidValue" SG_ 674 DrvSeatMsgModeStat "7h";
BA_ "GenSigTimeoutTime_ALL" SG_ 674 PassSeatMsgModeStat 800;
BA_ "InvalidValue" SG_ 674 PassSeatMsgModeStat "7h";
BA_ "GenSigTimeoutTime_ALL" SG_ 674 RearDrvSeatMsgModeStat 800;
BA_ "InvalidValue" SG_ 674 RearDrvSeatMsgModeStat "7h";
BA_ "GenSigTimeoutTime_ALL" SG_ 674 RearPassSeatMsgModeStat 800;
BA_ "InvalidValue" SG_ 674 RearPassSeatMsgModeStat "7h";
BA_ "GenSigTimeoutTime_ALL" SG_ 674 LSSM_ALINResErr 800;
BA_ "InvalidValue" SG_ 674 LSSM_ALINResErr "null";
BA_ "GenSigTimeoutTime_ALL" SG_ 674 LSSM_APumpFail 800;
BA_ "InvalidValue" SG_ 674 LSSM_APumpFail "null";
BA_ "GenSigStartValue" SG_ 674 DrvSeatMsgStrLvlStat 1;
BA_ "GenSigTimeoutTime_ALL" SG_ 674 DrvSeatMsgStrLvlStat 800;
BA_ "InvalidValue" SG_ 674 DrvSeatMsgStrLvlStat "7h";
BA_ "GenSigTimeoutTime_ALL" SG_ 674 LSSM_BLINResErr 800;
BA_ "InvalidValue" SG_ 674 LSSM_BLINResErr "null";
BA_ "GenSigTimeoutTime_ALL" SG_ 674 LSSM_BPumpFail 800;
BA_ "InvalidValue" SG_ 674 LSSM_BPumpFail "null";
BA_ "GenSigStartValue" SG_ 674 PassSeatMsgStrLvlStat 1;
BA_ "GenSigTimeoutTime_ALL" SG_ 674 PassSeatMsgStrLvlStat 800;
BA_ "InvalidValue" SG_ 674 PassSeatMsgStrLvlStat "7h";
BA_ "GenSigTimeoutTime_ALL" SG_ 674 LSSM_CLINResErr 800;
BA_ "InvalidValue" SG_ 674 LSSM_CLINResErr "null";
BA_ "GenSigTimeoutTime_ALL" SG_ 674 LSSM_CPumpFail 800;
BA_ "InvalidValue" SG_ 674 LSSM_CPumpFail "null";
BA_ "GenSigStartValue" SG_ 674 RearDrvSeatMsgStrLvlStat 1;
BA_ "GenSigTimeoutTime_ALL" SG_ 674 RearDrvSeatMsgStrLvlStat 800;
BA_ "InvalidValue" SG_ 674 RearDrvSeatMsgStrLvlStat "7h";
BA_ "GenSigTimeoutTime_ALL" SG_ 674 LSSM_DLINResErr 800;
BA_ "InvalidValue" SG_ 674 LSSM_DLINResErr "null";
BA_ "GenSigTimeoutTime_ALL" SG_ 674 LSSM_DPumpFail 800;
BA_ "InvalidValue" SG_ 674 LSSM_DPumpFail "null";
BA_ "GenSigStartValue" SG_ 674 RearPassSeatMsgStrLvlStat 1;
BA_ "GenSigTimeoutTime_ALL" SG_ 674 RearPassSeatMsgStrLvlStat 800;
BA_ "InvalidValue" SG_ 674 RearPassSeatMsgStrLvlStat "7h";
BA_ "GenSigTimeoutTime_ALL" SG_ 676 ID2 5000;
BA_ "GenSigTimeoutTime_ALL" SG_ 676 ECU_ID_WUPREG 5000;
BA_ "InvalidValue" SG_ 676 ECU_ID_WUPREG "null";
BA_ "GenSigTimeoutTime_ALL" SG_ 676 ID_FN_INQY 5000;
BA_ "InvalidValue" SG_ 676 ID_FN_INQY "null";
BA_ "GenSigTimeoutTime_ALL" SG_ 676 ID_FN_RQ_BUS 5000;
BA_ "InvalidValue" SG_ 676 ID_FN_RQ_BUS "null";
BA_ "GenSigTimeoutTime_ALL" SG_ 676 NO_CC_MESS_EXT 5000;
BA_ "GenSigTimeoutTime_ALL" SG_ 676 NO_CC_MESS_STD 5000;
BA_ "InvalidValue" SG_ 676 NO_CC_MESS_STD "null";
BA_ "GenSigTimeoutTime_ALL" SG_ 676 WACA 5000;
BA_ "InvalidValue" SG_ 676 WACA "null";
BA_ "GenSigTimeoutTime_ALL" SG_ 676 ID_RQ_BUS 5000;
BA_ "GenSigTimeoutTime_ALL" SG_ 676 ST_CC_MESS_EXT 5000;
BA_ "GenSigTimeoutTime_ALL" SG_ 676 ST_CC_MESS_STD 5000;
BA_ "GenSigTimeoutTime_ALL" SG_ 676 TRANF_CC_MESS_EXT 5000;
BA_ "GenSigTimeoutTime_ALL" SG_ 676 TRANF_CC_MESS_STD 5000;
BA_ "GenSigTimeoutTime_ALL" SG_ 676 ST_IDC_CCLK_CC_MESS_EXT 5000;
BA_ "GenSigTimeoutTime_ALL" SG_ 676 ST_IDC_CCLK_CC_MESS_STD 5000;
BA_ "GenSigTimeoutTime_ALL" SG_ 676 NO_FRM_CC_MESS_EXT 5000;
BA_ "GenSigTimeoutTime_ALL" SG_ 676 ST_RQ_BUS 5000;
BA_ "GenSigTimeoutTime_ALL" SG_ 676 QUAN_FRM_CC_MESS_EXT 5000;
BA_ "GenSigTimeoutTime_ALL" SG_ 676 ST_LAW_RQ 5000;
BA_ "GenSigTimeoutTime_ALL" SG_ 676 DUR_FLLUPT 5000;
BA_ "GenSigTimeoutTime_ALL" SG_ 676 UTDT_CC_MESS 5000;
BA_ "GenSigTimeoutTime_ALL" SG_ 714 CHKSM_IC_SENSOR 500;
BA_ "InvalidValue" SG_ 714 CHKSM_IC_SENSOR "null";
BA_ "GenSigTimeoutTime_ALL" SG_ 714 ALV_IC_SENSOR 500;
BA_ "InvalidValue" SG_ 714 ALV_IC_SENSOR "Fh";
BA_ "GenSigStartValue" SG_ 714 MHU_STAT_AmbientTempRaw 80;
BA_ "GenSigTimeoutTime_ALL" SG_ 714 MHU_STAT_AmbientTempRaw 500;
BA_ "InvalidValue" SG_ 714 MHU_STAT_AmbientTempRaw "FFh";
BA_ "GenSigTimeoutTime_ALL" SG_ 714 MHU_STAT_FuelLevel 500;
BA_ "InvalidValue" SG_ 714 MHU_STAT_FuelLevel "FFh";
BA_ "GenSigStartValue" SG_ 714 MHU_STAT_AmbientTemp 80;
BA_ "GenSigTimeoutTime_ALL" SG_ 714 MHU_STAT_AmbientTemp 500;
BA_ "InvalidValue" SG_ 714 MHU_STAT_AmbientTemp "FFh";
BA_ "GenSigTimeoutTime_ALL" SG_ 714 MHU_STAT_CoolantLevelStatus 500;
BA_ "InvalidValue" SG_ 714 MHU_STAT_CoolantLevelStatus "3h";
BA_ "GenSigTimeoutTime_ALL" SG_ 715 TEMP_EX 500;
BA_ "InvalidValue" SG_ 715 TEMP_EX "FFh";
BA_ "GenSigTimeoutTime_ALL" SG_ 715 TEMP_EX_UNFILT 500;
BA_ "InvalidValue" SG_ 715 TEMP_EX_UNFILT "FFh";
BA_ "GenSigTimeoutTime_ALL" SG_ 753 MHU_STAT_AirbagWarnLamp 500;
BA_ "InvalidValue" SG_ 753 MHU_STAT_AirbagWarnLamp "3h";
BA_ "GenSigTimeoutTime_ALL" SG_ 760 DISP_HR 5000;
BA_ "InvalidValue" SG_ 760 DISP_HR "FFh";
BA_ "GenSigTimeoutTime_ALL" SG_ 760 DISP_MN 5000;
BA_ "InvalidValue" SG_ 760 DISP_MN "FFh";
BA_ "GenSigTimeoutTime_ALL" SG_ 760 DISP_SEC 5000;
BA_ "InvalidValue" SG_ 760 DISP_SEC "FFh";
BA_ "GenSigStartValue" SG_ 760 DISP_DATE_DAY 1;
BA_ "GenSigTimeoutTime_ALL" SG_ 760 DISP_DATE_DAY 5000;
BA_ "InvalidValue" SG_ 760 DISP_DATE_DAY "FFh";
BA_ "GenSigStartValue" SG_ 760 DISP_DATE_MON 1;
BA_ "GenSigTimeoutTime_ALL" SG_ 760 DISP_DATE_MON 5000;
BA_ "InvalidValue" SG_ 760 DISP_DATE_MON "Fh";
BA_ "GenSigTimeoutTime_ALL" SG_ 760 DISP_DATE_WDAY 5000;
BA_ "InvalidValue" SG_ 760 DISP_DATE_WDAY "Fh";
BA_ "GenSigStartValue" SG_ 760 DISP_DATE_YR 1;
BA_ "GenSigTimeoutTime_ALL" SG_ 760 DISP_DATE_YR 5000;
BA_ "InvalidValue" SG_ 760 DISP_DATE_YR "FFFFh";
BA_ "GenSigTimeoutTime_ALL" SG_ 760 ST_DISP_CTI_DATE 5000;
BA_ "InvalidValue" SG_ 760 ST_DISP_CTI_DATE "Fh";
BA_ "GenSigSendType" SG_ 768 CCU_STAT_SyncClimateZone 4;
BA_ "InvalidValue" SG_ 768 CCU_STAT_SyncClimateZone "3h";
BA_ "GenSigSendType" SG_ 768 CCU_STAT_Auto 4;
BA_ "InvalidValue" SG_ 768 CCU_STAT_Auto "3h";
BA_ "GenSigSendType" SG_ 768 CCU_STAT_Aircondition 4;
BA_ "InvalidValue" SG_ 768 CCU_STAT_Aircondition "3h";
BA_ "GenSigSendType" SG_ 768 CCU_STAT_IonButton 4;
BA_ "InvalidValue" SG_ 768 CCU_STAT_IonButton "3h";
BA_ "GenSigSendType" SG_ 768 CCU_STAT_MaxAc 4;
BA_ "InvalidValue" SG_ 768 CCU_STAT_MaxAc "3h";
BA_ "GenSigSendType" SG_ 768 CCU_STAT_OnOff 4;
BA_ "GenSigStartValue" SG_ 768 CCU_STAT_OnOff 3;
BA_ "InvalidValue" SG_ 768 CCU_STAT_OnOff "3h";
BA_ "GenSigSendType" SG_ 768 CCU_STAT_FanSpeed 4;
BA_ "InvalidValue" SG_ 768 CCU_STAT_FanSpeed "Fh";
BA_ "GenSigSendType" SG_ 768 CCU_STAT_RecircFlap 4;
BA_ "GenSigStartValue" SG_ 768 CCU_STAT_RecircFlap 1;
BA_ "InvalidValue" SG_ 768 CCU_STAT_RecircFlap "3h";
BA_ "GenSigSendType" SG_ 768 CCU_STAT_FlapPos 4;
BA_ "InvalidValue" SG_ 768 CCU_STAT_FlapPos "7h";
BA_ "GenSigSendType" SG_ 768 CCU_STAT_Defrost 4;
BA_ "InvalidValue" SG_ 768 CCU_STAT_Defrost "3h";
BA_ "GenSigSendType" SG_ 768 CCU_STAT_PTC_Heater 4;
BA_ "InvalidValue" SG_ 768 CCU_STAT_PTC_Heater "7h";
BA_ "GenSigSendType" SG_ 768 CCU_STAT_TempDriver 4;
BA_ "GenSigStartValue" SG_ 768 CCU_STAT_TempDriver 40;
BA_ "InvalidValue" SG_ 768 CCU_STAT_TempDriver "FFh";
BA_ "GenSigSendType" SG_ 768 CCU_STAT_TempPassenger 4;
BA_ "GenSigStartValue" SG_ 768 CCU_STAT_TempPassenger 40;
BA_ "InvalidValue" SG_ 768 CCU_STAT_TempPassenger "FFh";
BA_ "GenSigTimeoutTime_ALL" SG_ 770 CHKSM_CCU_TEMP_PRESSURE 5000;
BA_ "InvalidValue" SG_ 770 CHKSM_CCU_TEMP_PRESSURE "null";
BA_ "GenSigTimeoutTime_ALL" SG_ 770 ALV_CCU_TEMP_PRESSURE 5000;
BA_ "InvalidValue" SG_ 770 ALV_CCU_TEMP_PRESSURE "Fh";
BA_ "GenSigTimeoutTime_ALL" SG_ 770 CCU_Pressure_AC 5000;
BA_ "InvalidValue" SG_ 770 CCU_Pressure_AC "3Fh";
BA_ "GenSigStartValue" SG_ 770 CCU_InteriorTemp 80;
BA_ "GenSigTimeoutTime_ALL" SG_ 770 CCU_InteriorTemp 5000;
BA_ "InvalidValue" SG_ 770 CCU_InteriorTemp "FFh";
BA_ "GenSigStartValue" SG_ 770 CCU_TempEx_AC 80;
BA_ "GenSigTimeoutTime_ALL" SG_ 770 CCU_TempEx_AC 5000;
BA_ "InvalidValue" SG_ 770 CCU_TempEx_AC "FFh";
BA_ "GenSigStartValue" SG_ 770 CCU_EvaporatorTemp 80;
BA_ "GenSigTimeoutTime_ALL" SG_ 770 CCU_EvaporatorTemp 5000;
BA_ "InvalidValue" SG_ 770 CCU_EvaporatorTemp "FFh";
BA_ "GenSigStartValue" SG_ 773 HtrMediumOutletTemp 80;
BA_ "GenSigTimeoutTime_ALL" SG_ 773 HtrMediumOutletTemp 500;
BA_ "InvalidValue" SG_ 773 HtrMediumOutletTemp "1FFh";
BA_ "GenSigTimeoutTime_ALL" SG_ 773 CcuHtrOnOffSts 500;
BA_ "InvalidValue" SG_ 773 CcuHtrOnOffSts "7h";
BA_ "GenSigTimeoutTime_ALL" SG_ 773 EcompOnOffSts 500;
BA_ "InvalidValue" SG_ 773 EcompOnOffSts "3h";
BA_ "GenSigStartValue" SG_ 773 HtrMediumInletTemp 80;
BA_ "GenSigTimeoutTime_ALL" SG_ 773 HtrMediumInletTemp 500;
BA_ "InvalidValue" SG_ 773 HtrMediumInletTemp "1FFh";
BA_ "GenSigTimeoutTime_ALL" SG_ 773 ECompRpm 500;
BA_ "InvalidValue" SG_ 773 ECompRpm "FFFFh";
BA_ "GenSigTimeoutTime_ALL" SG_ 773 ECompPowerConsumption 500;
BA_ "InvalidValue" SG_ 773 ECompPowerConsumption "null";
BA_ "GenSigTimeoutTime_ALL" SG_ 774 CCU_EcompOnOffRequest 500;
BA_ "InvalidValue" SG_ 774 CCU_EcompOnOffRequest "3h";
BA_ "GenSigTimeoutTime_ALL" SG_ 774 CCU_HtrOnOffRequest 500;
BA_ "InvalidValue" SG_ 774 CCU_HtrOnOffRequest "3h";
BA_ "GenSigTimeoutTime_ALL" SG_ 774 CCU_AcOffCode_CCU 500;
BA_ "InvalidValue" SG_ 774 CCU_AcOffCode_CCU "FFh";
BA_ "GenSigTimeoutTime_ALL" SG_ 774 CCU_CoolPowerDemand 500;
BA_ "InvalidValue" SG_ 774 CCU_CoolPowerDemand "FFh";
BA_ "GenSigTimeoutTime_ALL" SG_ 774 CCU_HeatPowerDemand 500;
BA_ "InvalidValue" SG_ 774 CCU_HeatPowerDemand "FFh";
BA_ "GenSigTimeoutTime_ALL" SG_ 774 CCU_PTCOffCode_CCU 500;
BA_ "InvalidValue" SG_ 774 CCU_PTCOffCode_CCU "FFh";
BA_ "GenSigTimeoutTime_ALL" SG_ 774 CCU_CoolDemand 500;
BA_ "InvalidValue" SG_ 774 CCU_CoolDemand "FFh";
BA_ "GenSigTimeoutTime_ALL" SG_ 774 CCU_HeatDemand 500;
BA_ "InvalidValue" SG_ 774 CCU_HeatDemand "FFh";
BA_ "GenSigTimeoutTime_ALL" SG_ 775 CHKSM_CPD_Output_1 5000;
BA_ "InvalidValue" SG_ 775 CHKSM_CPD_Output_1 "null";
BA_ "GenSigTimeoutTime_ALL" SG_ 775 ALV_CPD_Output_1 5000;
BA_ "InvalidValue" SG_ 775 ALV_CPD_Output_1 "Fh";
BA_ "GenSigTimeoutTime_ALL" SG_ 775 OUT_Alert_TO_BCM 5000;
BA_ "InvalidValue" SG_ 775 OUT_Alert_TO_BCM "7h";
BA_ "GenSigTimeoutTime_ALL" SG_ 775 CPD_State_information 5000;
BA_ "InvalidValue" SG_ 775 CPD_State_information "null";
BA_ "GenSigSendType" SG_ 784 CCUR_STAT_IonButton 4;
BA_ "InvalidValue" SG_ 784 CCUR_STAT_IonButton "3h";
BA_ "GenSigSendType" SG_ 784 CCUR_STAT_Defrost 4;
BA_ "InvalidValue" SG_ 784 CCUR_STAT_Defrost "3h";
BA_ "GenSigSendType" SG_ 784 CCUR_STAT_Auto 4;
BA_ "InvalidValue" SG_ 784 CCUR_STAT_Auto "3h";
BA_ "GenSigSendType" SG_ 784 CCUR_STAT_Aircondition 4;
BA_ "InvalidValue" SG_ 784 CCUR_STAT_Aircondition "3h";
BA_ "GenSigSendType" SG_ 784 CCUR_STAT_FlapPos 4;
BA_ "InvalidValue" SG_ 784 CCUR_STAT_FlapPos "7h";
BA_ "GenSigSendType" SG_ 784 CCUR_STAT_FanSpeed 4;
BA_ "InvalidValue" SG_ 784 CCUR_STAT_FanSpeed "Fh";
BA_ "GenSigSendType" SG_ 784 CCUR_STAT_PTC_Heater 4;
BA_ "InvalidValue" SG_ 784 CCUR_STAT_PTC_Heater "7h";
BA_ "GenSigSendType" SG_ 784 CCUR_STAT_OnOff 4;
BA_ "GenSigStartValue" SG_ 784 CCUR_STAT_OnOff 3;
BA_ "InvalidValue" SG_ 784 CCUR_STAT_OnOff "3h";
BA_ "GenSigSendType" SG_ 784 CCUR_STAT_MaxAc 4;
BA_ "InvalidValue" SG_ 784 CCUR_STAT_MaxAc "3h";
BA_ "GenSigSendType" SG_ 784 CCUR_STAT_SyncClimateZone 4;
BA_ "InvalidValue" SG_ 784 CCUR_STAT_SyncClimateZone "3h";
BA_ "GenSigSendType" SG_ 784 CCUR_STAT_RecircFlap 4;
BA_ "GenSigStartValue" SG_ 784 CCUR_STAT_RecircFlap 1;
BA_ "InvalidValue" SG_ 784 CCUR_STAT_RecircFlap "3h";
BA_ "GenSigSendType" SG_ 784 CCUR_STAT_TempRear 4;
BA_ "GenSigStartValue" SG_ 784 CCUR_STAT_TempRear 40;
BA_ "InvalidValue" SG_ 784 CCUR_STAT_TempRear "null";
BA_ "GenSigTimeoutTime_ALL" SG_ 806 CHSKM_POD_StatusDCDC1 500;
BA_ "GenSigTimeoutTime_ALL" SG_ 806 ALV_POD_StatusDCDC1 500;
BA_ "InvalidValue" SG_ 806 ALV_POD_StatusDCDC1 "Fh";
BA_ "GenSigTimeoutTime_ALL" SG_ 806 POD_statusDCDC 500;
BA_ "InvalidValue" SG_ 806 POD_statusDCDC "7h";
BA_ "GenSigTimeoutTime_ALL" SG_ 808 T_SEC_COU_REL 5000;
BA_ "InvalidValue" SG_ 808 T_SEC_COU_REL "FFFFFFFFh";
BA_ "GenSigTimeoutTime_ALL" SG_ 808 T_DAY_COU_ABSL 5000;
BA_ "InvalidValue" SG_ 808 T_DAY_COU_ABSL "FFFFh";
BA_ "GenSigTimeoutTime_ALL" SG_ 809 CRC_BCM_ODO 5000;
BA_ "InvalidValue" SG_ 809 CRC_BCM_ODO "null";
BA_ "GenSigTimeoutTime_ALL" SG_ 809 ALIV_BCM_ODO 5000;
BA_ "InvalidValue" SG_ 809 ALIV_BCM_ODO "Fh";
BA_ "GenSigTimeoutTime_ALL" SG_ 809 Odometer_BCM 5000;
BA_ "InvalidValue" SG_ 809 Odometer_BCM "FFFFFh";
BA_ "GenSigTimeoutTime_ALL" SG_ 809 SECCAN_BCM_ODO 5000;
BA_ "InvalidValue" SG_ 809 SECCAN_BCM_ODO "null";
BA_ "GenSigTimeoutTime_ALL" SG_ 812 CRC_HGLV_EHC 1000;
BA_ "InvalidValue" SG_ 812 CRC_HGLV_EHC "null";
BA_ "GenSigTimeoutTime_ALL" SG_ 812 ALIV_HGLV_EHC 1000;
BA_ "InvalidValue" SG_ 812 ALIV_HGLV_EHC "Fh";
BA_ "GenSigStartValue" SG_ 812 HGLV_RLH_EHC 127;
BA_ "GenSigTimeoutTime_ALL" SG_ 812 HGLV_RLH_EHC 1000;
BA_ "InvalidValue" SG_ 812 HGLV_RLH_EHC "null";
BA_ "GenSigStartValue" SG_ 812 HGLV_RRH_EHC 127;
BA_ "GenSigTimeoutTime_ALL" SG_ 812 HGLV_RRH_EHC 1000;
BA_ "InvalidValue" SG_ 812 HGLV_RRH_EHC "null";
BA_ "GenSigTimeoutTime_ALL" SG_ 812 QU_HGLV_RLH_EHC 1000;
BA_ "InvalidValue" SG_ 812 QU_HGLV_RLH_EHC "null";
BA_ "GenSigTimeoutTime_ALL" SG_ 812 QU_HGLV_RRH_EHC 1000;
BA_ "InvalidValue" SG_ 812 QU_HGLV_RRH_EHC "null";
BA_ "GenSigTimeoutTime_ALL" SG_ 816 MILE_KM 500;
BA_ "InvalidValue" SG_ 816 MILE_KM "FFFFFFh";
BA_ "GenSigTimeoutTime_ALL" SG_ 816 FLLV_FUTA 500;
BA_ "InvalidValue" SG_ 816 FLLV_FUTA "FFh";
BA_ "GenSigTimeoutTime_ALL" SG_ 816 RNG 500;
BA_ "InvalidValue" SG_ 816 RNG "FFFh";
BA_ "GenSigTimeoutTime_ALL" SG_ 816 ST_FLLV_FUTA_SPAR 500;
BA_ "InvalidValue" SG_ 816 ST_FLLV_FUTA_SPAR "3h";
BA_ "GenSigTimeoutTime_ALL" SG_ 880 CRC_MHU_SBR_Status 1500;
BA_ "GenSigTimeoutTime_ALL" SG_ 880 ALV_MHU_SBR_Status 1500;
BA_ "InvalidValue" SG_ 880 ALV_MHU_SBR_Status "Fh";
BA_ "GenSigStartValue" SG_ 880 SBR_STAT_Chime 3;
BA_ "GenSigTimeoutTime_ALL" SG_ 880 SBR_STAT_Chime 1500;
BA_ "InvalidValue" SG_ 880 SBR_STAT_Chime "3h";
BA_ "GenSigStartValue" SG_ 880 SBR_STAT_Telltale 3;
BA_ "GenSigTimeoutTime_ALL" SG_ 880 SBR_STAT_Telltale 1500;
BA_ "InvalidValue" SG_ 880 SBR_STAT_Telltale "3h";
BA_ "GenSigTimeoutTime_ALL" SG_ 880 SBR_STAT_Active 1500;
BA_ "GenSigTimeoutTime_ALL" SG_ 896 VIN_Byte1 5000;
BA_ "InvalidValue" SG_ 896 VIN_Byte1 "null";
BA_ "GenSigTimeoutTime_ALL" SG_ 896 VIN_Byte2 5000;
BA_ "InvalidValue" SG_ 896 VIN_Byte2 "null";
BA_ "GenSigTimeoutTime_ALL" SG_ 896 VIN_Byte3 5000;
BA_ "InvalidValue" SG_ 896 VIN_Byte3 "null";
BA_ "GenSigTimeoutTime_ALL" SG_ 896 VIN_Byte4 5000;
BA_ "InvalidValue" SG_ 896 VIN_Byte4 "null";
BA_ "GenSigTimeoutTime_ALL" SG_ 896 VIN_Byte5 5000;
BA_ "InvalidValue" SG_ 896 VIN_Byte5 "null";
BA_ "GenSigTimeoutTime_ALL" SG_ 896 VIN_Byte6 5000;
BA_ "InvalidValue" SG_ 896 VIN_Byte6 "null";
BA_ "GenSigTimeoutTime_ALL" SG_ 896 VIN_Byte7 5000;
BA_ "InvalidValue" SG_ 896 VIN_Byte7 "null";
BA_ "GenSigTimeoutTime_ALL" SG_ 897 CHKSM_ACM_SEAT_OCCUPATION 1000;
BA_ "InvalidValue" SG_ 897 CHKSM_ACM_SEAT_OCCUPATION "null";
BA_ "GenSigTimeoutTime_ALL" SG_ 897 ALV_ACM_SEAT_OCCUPATION 1000;
BA_ "InvalidValue" SG_ 897 ALV_ACM_SEAT_OCCUPATION "Fh";
BA_ "GenSigTimeoutTime_ALL" SG_ 897 ACM_Seat_Occupancy_Passenger 1000;
BA_ "InvalidValue" SG_ 897 ACM_Seat_Occupancy_Passenger "null";
BA_ "GenSigTimeoutTime_ALL" SG_ 897 ACM_Seat_Occupancy_2nd_Row_Dri 1000;
BA_ "InvalidValue" SG_ 897 ACM_Seat_Occupancy_2nd_Row_Dri "null";
BA_ "GenSigTimeoutTime_ALL" SG_ 897 ACM_Seat_Occupancy_2nd_Row_Pas 1000;
BA_ "InvalidValue" SG_ 897 ACM_Seat_Occupancy_2nd_Row_Pas "null";
BA_ "GenSigTimeoutTime_ALL" SG_ 897 ACM_Seat_Occupancy_2nd_Row_Mid 1000;
BA_ "InvalidValue" SG_ 897 ACM_Seat_Occupancy_2nd_Row_Mid "null";
BA_ "GenSigTimeoutTime_ALL" SG_ 897 ACM_Seat_Belt_Status_Passenger 1000;
BA_ "InvalidValue" SG_ 897 ACM_Seat_Belt_Status_Passenger "null";
BA_ "GenSigTimeoutTime_ALL" SG_ 897 ACM_Seat_Belt_Status_Driver 1000;
BA_ "InvalidValue" SG_ 897 ACM_Seat_Belt_Status_Driver "null";
BA_ "GenSigTimeoutTime_ALL" SG_ 897 ACM_Seat_Belt_Status_2nd_Row_Dri 1000;
BA_ "InvalidValue" SG_ 897 ACM_Seat_Belt_Status_2nd_Row_Dri "null";
BA_ "GenSigTimeoutTime_ALL" SG_ 897 ACM_Seat_Belt_Status_2nd_Row_Mid 1000;
BA_ "InvalidValue" SG_ 897 ACM_Seat_Belt_Status_2nd_Row_Mid "null";
BA_ "GenSigTimeoutTime_ALL" SG_ 897 ACM_Seat_Belt_Status_2nd_Row_Pas 1000;
BA_ "InvalidValue" SG_ 897 ACM_Seat_Belt_Status_2nd_Row_Pas "null";
BA_ "GenSigSendType" SG_ 905 VCU_IMMO_Sts 1;
BA_ "InvalidValue" SG_ 905 VCU_IMMO_Sts "null";
BA_ "GenSigSendType" SG_ 905 SECCAN_VCU_IMMO_Sts 1;
BA_ "InvalidValue" SG_ 905 SECCAN_VCU_IMMO_Sts "null";
BA_ "GenSigSendType" SG_ 920 BCM_Immo_Byte_0 1;
BA_ "InvalidValue" SG_ 920 BCM_Immo_Byte_0 "null";
BA_ "GenSigSendType" SG_ 920 BCM_Immo_Byte_1 1;
BA_ "InvalidValue" SG_ 920 BCM_Immo_Byte_1 "null";
BA_ "GenSigSendType" SG_ 920 BCM_Immo_Byte_2 1;
BA_ "InvalidValue" SG_ 920 BCM_Immo_Byte_2 "null";
BA_ "GenSigSendType" SG_ 920 BCM_Immo_Byte_3 1;
BA_ "InvalidValue" SG_ 920 BCM_Immo_Byte_3 "null";
BA_ "GenSigSendType" SG_ 920 BCM_Immo_Byte_4 1;
BA_ "InvalidValue" SG_ 920 BCM_Immo_Byte_4 "null";
BA_ "GenSigSendType" SG_ 920 BCM_Immo_Byte_5 1;
BA_ "InvalidValue" SG_ 920 BCM_Immo_Byte_5 "null";
BA_ "GenSigSendType" SG_ 920 BCM_Immo_Byte_6 1;
BA_ "InvalidValue" SG_ 920 BCM_Immo_Byte_6 "null";
BA_ "GenSigSendType" SG_ 920 BCM_Immo_Byte_7 1;
BA_ "InvalidValue" SG_ 920 BCM_Immo_Byte_7 "null";
BA_ "GenSigSendType" SG_ 921 VCU_Immo_Byte_0 1;
BA_ "InvalidValue" SG_ 921 VCU_Immo_Byte_0 "null";
BA_ "GenSigSendType" SG_ 921 VCU_Immo_Byte_1 1;
BA_ "InvalidValue" SG_ 921 VCU_Immo_Byte_1 "null";
BA_ "GenSigSendType" SG_ 921 VCU_Immo_Byte_2 1;
BA_ "InvalidValue" SG_ 921 VCU_Immo_Byte_2 "null";
BA_ "GenSigSendType" SG_ 921 VCU_Immo_Byte_3 1;
BA_ "InvalidValue" SG_ 921 VCU_Immo_Byte_3 "null";
BA_ "GenSigSendType" SG_ 921 VCU_Immo_Byte_4 1;
BA_ "InvalidValue" SG_ 921 VCU_Immo_Byte_4 "null";
BA_ "GenSigSendType" SG_ 921 VCU_Immo_Byte_5 1;
BA_ "InvalidValue" SG_ 921 VCU_Immo_Byte_5 "null";
BA_ "GenSigSendType" SG_ 921 VCU_Immo_Byte_6 1;
BA_ "InvalidValue" SG_ 921 VCU_Immo_Byte_6 "null";
BA_ "GenSigSendType" SG_ 921 VCU_Immo_Byte_7 1;
BA_ "InvalidValue" SG_ 921 VCU_Immo_Byte_7 "null";
BA_ "GenSigSendType" SG_ 922 MHU_Immo_Byte_0 2;
BA_ "InvalidValue" SG_ 922 MHU_Immo_Byte_0 "null";
BA_ "GenSigSendType" SG_ 922 MHU_Immo_Byte_1 2;
BA_ "InvalidValue" SG_ 922 MHU_Immo_Byte_1 "null";
BA_ "GenSigSendType" SG_ 922 MHU_Immo_Byte_2 2;
BA_ "InvalidValue" SG_ 922 MHU_Immo_Byte_2 "null";
BA_ "GenSigSendType" SG_ 922 MHU_Immo_Byte_3 2;
BA_ "InvalidValue" SG_ 922 MHU_Immo_Byte_3 "null";
BA_ "GenSigSendType" SG_ 922 MHU_Immo_Byte_4 2;
BA_ "InvalidValue" SG_ 922 MHU_Immo_Byte_4 "null";
BA_ "GenSigSendType" SG_ 922 MHU_Immo_Byte_5 2;
BA_ "InvalidValue" SG_ 922 MHU_Immo_Byte_5 "null";
BA_ "GenSigSendType" SG_ 922 MHU_Immo_Byte_6 2;
BA_ "InvalidValue" SG_ 922 MHU_Immo_Byte_6 "null";
BA_ "GenSigSendType" SG_ 922 MHU_Immo_Byte_7 2;
BA_ "InvalidValue" SG_ 922 MHU_Immo_Byte_7 "null";
BA_ "GenSigSendType" SG_ 923 BCM_Immo_MHU_Byte_0 2;
BA_ "InvalidValue" SG_ 923 BCM_Immo_MHU_Byte_0 "null";
BA_ "GenSigSendType" SG_ 923 BCM_Immo_MHU_Byte_1 2;
BA_ "InvalidValue" SG_ 923 BCM_Immo_MHU_Byte_1 "null";
BA_ "GenSigSendType" SG_ 923 BCM_Immo_MHU_Byte_2 2;
BA_ "InvalidValue" SG_ 923 BCM_Immo_MHU_Byte_2 "null";
BA_ "GenSigSendType" SG_ 923 BCM_Immo_MHU_Byte_3 2;
BA_ "InvalidValue" SG_ 923 BCM_Immo_MHU_Byte_3 "null";
BA_ "GenSigSendType" SG_ 923 BCM_Immo_MHU_Byte_4 2;
BA_ "InvalidValue" SG_ 923 BCM_Immo_MHU_Byte_4 "null";
BA_ "GenSigSendType" SG_ 923 BCM_Immo_MHU_Byte_5 2;
BA_ "InvalidValue" SG_ 923 BCM_Immo_MHU_Byte_5 "null";
BA_ "GenSigSendType" SG_ 923 BCM_Immo_MHU_Byte_6 2;
BA_ "InvalidValue" SG_ 923 BCM_Immo_MHU_Byte_6 "null";
BA_ "GenSigSendType" SG_ 923 BCM_Immo_MHU_Byte_7 2;
BA_ "InvalidValue" SG_ 923 BCM_Immo_MHU_Byte_7 "null";
BA_ "GenSigTimeoutTime_ALL" SG_ 924 ADAS_Body_Checksum 500;
BA_ "InvalidValue" SG_ 924 ADAS_Body_Checksum "null";
BA_ "GenSigTimeoutTime_ALL" SG_ 924 ADAS_Body_Alive 500;
BA_ "InvalidValue" SG_ 924 ADAS_Body_Alive "Fh";
BA_ "GenSigTimeoutTime_ALL" SG_ 924 SECCAN_Request_BODY 500;
BA_ "GenSigTimeoutTime_ALL" SG_ 924 ADAS_AHB_LBPos 500;
BA_ "InvalidValue" SG_ 924 ADAS_AHB_LBPos "7h";
BA_ "GenSigTimeoutTime_ALL" SG_ 924 ADAS_AHB_RBPos 500;
BA_ "InvalidValue" SG_ 924 ADAS_AHB_RBPos "null";
BA_ "GenSigTimeoutTime_ALL" SG_ 925 BCM_AHB_Override 500;
BA_ "InvalidValue" SG_ 925 BCM_AHB_Override "3h";
BA_ "GenSigTimeoutTime_ALL" SG_ 925 BCM_ADAS_AHB_RBPos_feed 500;
BA_ "InvalidValue" SG_ 925 BCM_ADAS_AHB_RBPos_feed "null";
BA_ "GenSigTimeoutTime_ALL" SG_ 925 BCM_ADAS_AHB_LBPos_feed 500;
BA_ "InvalidValue" SG_ 925 BCM_ADAS_AHB_LBPos_feed "null";
BA_ "GenSigTimeoutTime_ALL" SG_ 925 SECCAN_BCM_AHB_L 500;
BA_ "GenSigTimeoutTime_ALL" SG_ 926 Checksum_AMB 500;
BA_ "InvalidValue" SG_ 926 Checksum_AMB "null";
BA_ "GenSigTimeoutTime_ALL" SG_ 926 ALV_Counter_AMB 500;
BA_ "InvalidValue" SG_ 926 ALV_Counter_AMB "Fh";
BA_ "GenSigTimeoutTime_ALL" SG_ 926 SECCAN_ADAS_AMB 500;
BA_ "GenSigTimeoutTime_ALL" SG_ 926 ADAS_DOW_LockReqRight 500;
BA_ "InvalidValue" SG_ 926 ADAS_DOW_LockReqRight "null";
BA_ "GenSigTimeoutTime_ALL" SG_ 926 ADAS_DOW_LockReqLeft 500;
BA_ "InvalidValue" SG_ 926 ADAS_DOW_LockReqLeft "null";
BA_ "GenSigTimeoutTime_ALL" SG_ 926 ADAS_AmbLightLeft 500;
BA_ "InvalidValue" SG_ 926 ADAS_AmbLightLeft "3h";
BA_ "GenSigTimeoutTime_ALL" SG_ 926 ADAS_AmbLightRight 500;
BA_ "InvalidValue" SG_ 926 ADAS_AmbLightRight "3h";
BA_ "GenSigSendType" SG_ 1015 CHSKM_MFS_Control_Button 4;
BA_ "GenSigTimeoutTime_ALL" SG_ 1015 CHSKM_MFS_Control_Button 5000;
BA_ "InvalidValue" SG_ 1015 CHSKM_MFS_Control_Button "null";
BA_ "GenSigSendType" SG_ 1015 ALV_MFS_Control_Button 4;
BA_ "GenSigTimeoutTime_ALL" SG_ 1015 ALV_MFS_Control_Button 5000;
BA_ "InvalidValue" SG_ 1015 ALV_MFS_Control_Button "Fh";
BA_ "GenSigSendType" SG_ 1015 MFS_VoiceRecognitionOn_Off 4;
BA_ "GenSigTimeoutTime_ALL" SG_ 1015 MFS_VoiceRecognitionOn_Off 5000;
BA_ "InvalidValue" SG_ 1015 MFS_VoiceRecognitionOn_Off "null";
BA_ "GenSigSendType" SG_ 1015 MFS_ISAControl 4;
BA_ "GenSigTimeoutTime_ALL" SG_ 1015 MFS_ISAControl 5000;
BA_ "InvalidValue" SG_ 1015 MFS_ISAControl "null";
BA_ "GenSigSendType" SG_ 1015 MFS_CruiseSpeedIncrease 4;
BA_ "GenSigTimeoutTime_ALL" SG_ 1015 MFS_CruiseSpeedIncrease 5000;
BA_ "InvalidValue" SG_ 1015 MFS_CruiseSpeedIncrease "null";
BA_ "GenSigSendType" SG_ 1015 MFS_TelephoneCall_EndCall 4;
BA_ "GenSigTimeoutTime_ALL" SG_ 1015 MFS_TelephoneCall_EndCall 5000;
BA_ "InvalidValue" SG_ 1015 MFS_TelephoneCall_EndCall "null";
BA_ "GenSigSendType" SG_ 1015 MFS_LKAControl 4;
BA_ "GenSigTimeoutTime_ALL" SG_ 1015 MFS_LKAControl 5000;
BA_ "InvalidValue" SG_ 1015 MFS_LKAControl "null";
BA_ "GenSigSendType" SG_ 1015 MFS_CruiseGapIncrease 4;
BA_ "GenSigTimeoutTime_ALL" SG_ 1015 MFS_CruiseGapIncrease 5000;
BA_ "InvalidValue" SG_ 1015 MFS_CruiseGapIncrease "null";
BA_ "GenSigSendType" SG_ 1015 MFS_CruiseOn_Off 4;
BA_ "GenSigTimeoutTime_ALL" SG_ 1015 MFS_CruiseOn_Off 5000;
BA_ "InvalidValue" SG_ 1015 MFS_CruiseOn_Off "null";
BA_ "GenSigSendType" SG_ 1015 MFS_CruiseGapDecrease 4;
BA_ "GenSigTimeoutTime_ALL" SG_ 1015 MFS_CruiseGapDecrease 5000;
BA_ "InvalidValue" SG_ 1015 MFS_CruiseGapDecrease "null";
BA_ "GenSigSendType" SG_ 1015 MFS_CAN_RESControl 4;
BA_ "GenSigTimeoutTime_ALL" SG_ 1015 MFS_CAN_RESControl 5000;
BA_ "InvalidValue" SG_ 1015 MFS_CAN_RESControl "3h";
BA_ "GenSigSendType" SG_ 1015 MFS_CruiseSpeedDecrease 4;
BA_ "GenSigTimeoutTime_ALL" SG_ 1015 MFS_CruiseSpeedDecrease 5000;
BA_ "InvalidValue" SG_ 1015 MFS_CruiseSpeedDecrease "null";
BA_ "GenSigSendType" SG_ 1015 MFS_M2Control 4;
BA_ "GenSigTimeoutTime_ALL" SG_ 1015 MFS_M2Control 5000;
BA_ "InvalidValue" SG_ 1015 MFS_M2Control "null";
BA_ "GenSigSendType" SG_ 1015 MFS_SourseControl 4;
BA_ "GenSigTimeoutTime_ALL" SG_ 1015 MFS_SourseControl 5000;
BA_ "InvalidValue" SG_ 1015 MFS_SourseControl "null";
BA_ "GenSigSendType" SG_ 1015 MFS_UpControl 4;
BA_ "GenSigTimeoutTime_ALL" SG_ 1015 MFS_UpControl 5000;
BA_ "InvalidValue" SG_ 1015 MFS_UpControl "null";
BA_ "GenSigSendType" SG_ 1015 MFS_DownControl 4;
BA_ "GenSigTimeoutTime_ALL" SG_ 1015 MFS_DownControl 5000;
BA_ "InvalidValue" SG_ 1015 MFS_DownControl "null";
BA_ "GenSigSendType" SG_ 1015 MFS_LeftControl 4;
BA_ "GenSigTimeoutTime_ALL" SG_ 1015 MFS_LeftControl 5000;
BA_ "InvalidValue" SG_ 1015 MFS_LeftControl "null";
BA_ "GenSigSendType" SG_ 1015 MFS_Failure 4;
BA_ "GenSigTimeoutTime_ALL" SG_ 1015 MFS_Failure 5000;
BA_ "InvalidValue" SG_ 1015 MFS_Failure "null";
BA_ "GenSigSendType" SG_ 1015 MFS_RightControl 4;
BA_ "GenSigTimeoutTime_ALL" SG_ 1015 MFS_RightControl 5000;
BA_ "InvalidValue" SG_ 1015 MFS_RightControl "null";
BA_ "GenSigSendType" SG_ 1015 MFS_OK_Control 4;
BA_ "GenSigTimeoutTime_ALL" SG_ 1015 MFS_OK_Control 5000;
BA_ "InvalidValue" SG_ 1015 MFS_OK_Control "null";
BA_ "GenSigSendType" SG_ 1025 MHU_SET_SunroofGlassLevel 2;
BA_ "GenSigStartValue" SG_ 1025 MHU_SET_SunroofGlassLevel 255;
BA_ "InvalidValue" SG_ 1025 MHU_SET_SunroofGlassLevel "7Fh";
BA_ "GenSigSendType" SG_ 1025 MHU_SET_BonnetState 2;
BA_ "InvalidValue" SG_ 1025 MHU_SET_BonnetState "3h";
BA_ "GenSigSendType" SG_ 1025 MHU_SET_TrunkState 2;
BA_ "InvalidValue" SG_ 1025 MHU_SET_TrunkState "3h";
BA_ "GenSigSendType" SG_ 1025 MHU_SET_SunroofShaderLevel 2;
BA_ "GenSigStartValue" SG_ 1025 MHU_SET_SunroofShaderLevel 255;
BA_ "InvalidValue" SG_ 1025 MHU_SET_SunroofShaderLevel "7Fh";
BA_ "GenSigSendType" SG_ 1025 MHU_SET_DoorSpeedLock 2;
BA_ "GenSigStartValue" SG_ 1025 MHU_SET_DoorSpeedLock 6;
BA_ "InvalidValue" SG_ 1025 MHU_SET_DoorSpeedLock "6h";
BA_ "GenSigSendType" SG_ 1025 MHU_SET_WelcomeTriggerCondition 2;
BA_ "GenSigStartValue" SG_ 1025 MHU_SET_WelcomeTriggerCondition 3;
BA_ "InvalidValue" SG_ 1025 MHU_SET_WelcomeTriggerCondition "3h";
BA_ "GenSigSendType" SG_ 1025 MHU_SET_AutoSunroof 2;
BA_ "GenSigStartValue" SG_ 1025 MHU_SET_AutoSunroof 3;
BA_ "InvalidValue" SG_ 1025 MHU_SET_AutoSunroof "3h";
BA_ "GenSigSendType" SG_ 1025 MHU_SET_RemoteDoorUnlock 2;
BA_ "GenSigStartValue" SG_ 1025 MHU_SET_RemoteDoorUnlock 3;
BA_ "InvalidValue" SG_ 1025 MHU_SET_RemoteDoorUnlock "3h";
BA_ "GenSigSendType" SG_ 1025 MHU_SET_RemoteLockFeedback 2;
BA_ "GenSigStartValue" SG_ 1025 MHU_SET_RemoteLockFeedback 4;
BA_ "InvalidValue" SG_ 1025 MHU_SET_RemoteLockFeedback "4h";
BA_ "GenSigSendType" SG_ 1025 MHU_SET_FootkickSensor 2;
BA_ "GenSigStartValue" SG_ 1025 MHU_SET_FootkickSensor 3;
BA_ "InvalidValue" SG_ 1025 MHU_SET_FootkickSensor "3h";
BA_ "GenSigSendType" SG_ 1025 MHU_SET_AutoUnlockDoor 2;
BA_ "GenSigStartValue" SG_ 1025 MHU_SET_AutoUnlockDoor 3;
BA_ "InvalidValue" SG_ 1025 MHU_SET_AutoUnlockDoor "3h";
BA_ "GenSigSendType" SG_ 1025 MHU_SET_RemoteUnlockFeedback 2;
BA_ "GenSigStartValue" SG_ 1025 MHU_SET_RemoteUnlockFeedback 4;
BA_ "InvalidValue" SG_ 1025 MHU_SET_RemoteUnlockFeedback "4h";
BA_ "GenSigSendType" SG_ 1025 MHU_SET_Childlock 2;
BA_ "InvalidValue" SG_ 1025 MHU_SET_Childlock "null";
BA_ "GenSigSendType" SG_ 1025 MHU_SET_SunroofInitialize 2;
BA_ "InvalidValue" SG_ 1025 MHU_SET_SunroofInitialize "7h";
BA_ "GenSigSendType" SG_ 1025 WalkawayDoorLock 2;
BA_ "GenSigSendType" SG_ 1026 MHU_SET_DayTimeRunningLight 2;
BA_ "GenSigStartValue" SG_ 1026 MHU_SET_DayTimeRunningLight 1;
BA_ "InvalidValue" SG_ 1026 MHU_SET_DayTimeRunningLight "3h";
BA_ "GenSigSendType" SG_ 1026 MHU_SET_RearFogLight 2;
BA_ "GenSigStartValue" SG_ 1026 MHU_SET_RearFogLight 3;
BA_ "InvalidValue" SG_ 1026 MHU_SET_RearFogLight "3h";
BA_ "GenSigSendType" SG_ 1026 MHU_SET_FrontFogLight 2;
BA_ "GenSigStartValue" SG_ 1026 MHU_SET_FrontFogLight 3;
BA_ "InvalidValue" SG_ 1026 MHU_SET_FrontFogLight "3h";
BA_ "GenSigSendType" SG_ 1026 MHU_SET_WelcomeDimmingHeadlight 2;
BA_ "GenSigStartValue" SG_ 1026 MHU_SET_WelcomeDimmingHeadlight 3;
BA_ "InvalidValue" SG_ 1026 MHU_SET_WelcomeDimmingHeadlight "3h";
BA_ "GenSigSendType" SG_ 1026 MHU_SET_AmbientLightBrighness 2;
BA_ "InvalidValue" SG_ 1026 MHU_SET_AmbientLightBrighness "7Fh";
BA_ "GenSigSendType" SG_ 1026 MHU_SET_FootwellLightMode 2;
BA_ "GenSigStartValue" SG_ 1026 MHU_SET_FootwellLightMode 2;
BA_ "InvalidValue" SG_ 1026 MHU_SET_FootwellLightMode "3h";
BA_ "GenSigSendType" SG_ 1026 MHU_SET_ExteriorLight 2;
BA_ "GenSigStartValue" SG_ 1026 MHU_SET_ExteriorLight 4;
BA_ "InvalidValue" SG_ 1026 MHU_SET_ExteriorLight "4h";
BA_ "GenSigSendType" SG_ 1026 MHU_SET_TRWarningSignals 2;
BA_ "GenSigStartValue" SG_ 1026 MHU_SET_TRWarningSignals 3;
BA_ "InvalidValue" SG_ 1026 MHU_SET_TRWarningSignals "3h";
BA_ "GenSigSendType" SG_ 1026 MHU_SET_FrontDomeLamp 2;
BA_ "GenSigStartValue" SG_ 1026 MHU_SET_FrontDomeLamp 3;
BA_ "InvalidValue" SG_ 1026 MHU_SET_FrontDomeLamp "3h";
BA_ "GenSigSendType" SG_ 1026 MHU_SET_SwitchLightBrightness 2;
BA_ "GenSigStartValue" SG_ 1026 MHU_SET_SwitchLightBrightness 80;
BA_ "InvalidValue" SG_ 1026 MHU_SET_SwitchLightBrightness "4h";
BA_ "GenSigSendType" SG_ 1026 MHU_SET_HazardLight 2;
BA_ "InvalidValue" SG_ 1026 MHU_SET_HazardLight "3h";
BA_ "GenSigTimeoutTime_ALL" SG_ 1026 MHU_SET_HazardLight 500;
BA_ "GenSigSendType" SG_ 1026 MHU_SET_FollowMeHome 2;
BA_ "InvalidValue" SG_ 1026 MHU_SET_FollowMeHome "5h";
BA_ "GenSigSendType" SG_ 1026 MHU_SET_ADB_AHB 2;
BA_ "InvalidValue" SG_ 1026 MHU_SET_ADB_AHB "3h";
BA_ "GenSigSendType" SG_ 1026 MHU_SET_WelcomeAnimation 2;
BA_ "InvalidValue" SG_ 1026 MHU_SET_WelcomeAnimation "null";
BA_ "GenSigSendType" SG_ 1026 MHU_SET_ChargingAnimation 2;
BA_ "InvalidValue" SG_ 1026 MHU_SET_ChargingAnimation "0";
BA_ "GenSigSendType" SG_ 1026 MHU_SET_Auto_Leveling 2;
BA_ "GenSigStartValue" SG_ 1026 MHU_SET_Auto_Leveling 1;
BA_ "InvalidValue" SG_ 1026 MHU_SET_Auto_Leveling "3h";
BA_ "GenSigTimeoutTime_ALL" SG_ 1027 CHKSM_MHU_EVSetting 500;
BA_ "InvalidValue" SG_ 1027 CHKSM_MHU_EVSetting "null";
BA_ "GenSigTimeoutTime_ALL" SG_ 1027 ALV_MHU_EVSetting 500;
BA_ "InvalidValue" SG_ 1027 ALV_MHU_EVSetting "Fh";
BA_ "GenSigTimeoutTime_ALL" SG_ 1027 MHU_VCU_CreepDisable_stt 500;
BA_ "InvalidValue" SG_ 1027 MHU_VCU_CreepDisable_stt "null";
BA_ "GenSigTimeoutTime_ALL" SG_ 1027 MHU_BrakeRegenMode 500;
BA_ "GenSigStartValue" SG_ 1027 MHU_ChargeSetTargetSOC 80;
BA_ "GenSigTimeoutTime_ALL" SG_ 1027 MHU_ChargeSetTargetSOC 500;
BA_ "InvalidValue" SG_ 1027 MHU_ChargeSetTargetSOC "7Fh";
BA_ "GenSigStartValue" SG_ 1027 MHU_ChargeScheduleSet 2;
BA_ "GenSigTimeoutTime_ALL" SG_ 1027 MHU_ChargeScheduleSet 500;
BA_ "InvalidValue" SG_ 1027 MHU_ChargeScheduleSet "3h";
BA_ "GenSigStartValue" SG_ 1027 MHU_ChargingRequest 3;
BA_ "GenSigTimeoutTime_ALL" SG_ 1027 MHU_ChargingRequest 500;
BA_ "InvalidValue" SG_ 1027 MHU_ChargingRequest "null";
BA_ "GenSigTimeoutTime_ALL" SG_ 1027 MHU_ChgPort_Open_req 500;
BA_ "InvalidValue" SG_ 1027 MHU_ChgPort_Open_req "3h";
BA_ "GenSigStartValue" SG_ 1027 MHU_SET_DrivingModeSwitch 3;
BA_ "GenSigTimeoutTime_ALL" SG_ 1027 MHU_SET_DrivingModeSwitch 500;
BA_ "InvalidValue" SG_ 1027 MHU_SET_DrivingModeSwitch "3h";
BA_ "GenSigStartValue" SG_ 1027 MHU_ValetMode_Activation 2;
BA_ "GenSigTimeoutTime_ALL" SG_ 1027 MHU_ValetMode_Activation 500;
BA_ "InvalidValue" SG_ 1027 MHU_ValetMode_Activation "FFh";
BA_ "GenSigStartValue" SG_ 1027 MHU_ValetMode_MaxSpeed 255;
BA_ "GenSigTimeoutTime_ALL" SG_ 1027 MHU_ValetMode_MaxSpeed 500;
BA_ "InvalidValue" SG_ 1027 MHU_ValetMode_MaxSpeed "FFh";
BA_ "GenSigStartValue" SG_ 1027 MHU_ChargingCurrentLimit 6;
BA_ "GenSigTimeoutTime_ALL" SG_ 1027 MHU_ChargingCurrentLimit 500;
BA_ "InvalidValue" SG_ 1027 MHU_ChargingCurrentLimit "3Fh";
BA_ "GenSigSendType" SG_ 1028 MHU_SET_LeftMirrorPosX 2;
BA_ "GenSigStartValue" SG_ 1028 MHU_SET_LeftMirrorPosX 15;
BA_ "InvalidValue" SG_ 1028 MHU_SET_LeftMirrorPosX "FFh";
BA_ "GenSigSendType" SG_ 1028 MHU_SET_LeftMirrorPosY 2;
BA_ "GenSigStartValue" SG_ 1028 MHU_SET_LeftMirrorPosY 15;
BA_ "InvalidValue" SG_ 1028 MHU_SET_LeftMirrorPosY "FFh";
BA_ "GenSigSendType" SG_ 1028 MHU_SET_RightMirrorPosX 2;
BA_ "GenSigStartValue" SG_ 1028 MHU_SET_RightMirrorPosX 15;
BA_ "InvalidValue" SG_ 1028 MHU_SET_RightMirrorPosX "FFh";
BA_ "GenSigSendType" SG_ 1028 MHU_SET_RightMirrorPosY 2;
BA_ "GenSigStartValue" SG_ 1028 MHU_SET_RightMirrorPosY 15;
BA_ "InvalidValue" SG_ 1028 MHU_SET_RightMirrorPosY "FFh";
BA_ "GenSigSendType" SG_ 1028 MHU_SET_MirrorAdjustLeft 2;
BA_ "InvalidValue" SG_ 1028 MHU_SET_MirrorAdjustLeft "3h";
BA_ "GenSigSendType" SG_ 1028 MHU_SET_MirrorAdjustRight 2;
BA_ "InvalidValue" SG_ 1028 MHU_SET_MirrorAdjustRight "3h";
BA_ "GenSigSendType" SG_ 1028 MHU_SET_MirrorManual 2;
BA_ "GenSigStartValue" SG_ 1028 MHU_SET_MirrorManual 3;
BA_ "InvalidValue" SG_ 1028 MHU_SET_MirrorManual "3h";
BA_ "GenSigSendType" SG_ 1028 SECCAN_MirrorAdj 2;
BA_ "InvalidValue" SG_ 1028 SECCAN_MirrorAdj "null";
BA_ "GenSigSendType" SG_ 1029 MHU_SET_CCUF_AirCondition 2;
BA_ "InvalidValue" SG_ 1029 MHU_SET_CCUF_AirCondition "3h";
BA_ "GenSigSendType" SG_ 1029 MHU_SET_CCUF_AutoAC 2;
BA_ "InvalidValue" SG_ 1029 MHU_SET_CCUF_AutoAC "3h";
BA_ "GenSigSendType" SG_ 1029 MHU_SET_CCUF_MaxAc 2;
BA_ "InvalidValue" SG_ 1029 MHU_SET_CCUF_MaxAc "3h";
BA_ "GenSigSendType" SG_ 1029 MHU_SET_CCUF_FanSpeed 2;
BA_ "GenSigStartValue" SG_ 1029 MHU_SET_CCUF_FanSpeed 3;
BA_ "InvalidValue" SG_ 1029 MHU_SET_CCUF_FanSpeed "7h";
BA_ "GenSigSendType" SG_ 1029 MHU_SET_CCUF_Recirculation 2;
BA_ "GenSigStartValue" SG_ 1029 MHU_SET_CCUF_Recirculation 1;
BA_ "InvalidValue" SG_ 1029 MHU_SET_CCUF_Recirculation "3h";
BA_ "GenSigSendType" SG_ 1029 MHU_SET_CCUF_Ion 2;
BA_ "InvalidValue" SG_ 1029 MHU_SET_CCUF_Ion "3h";
BA_ "GenSigSendType" SG_ 1029 MHU_SET_CCUF_FlapPosition 2;
BA_ "InvalidValue" SG_ 1029 MHU_SET_CCUF_FlapPosition "4h";
BA_ "GenSigSendType" SG_ 1029 MHU_SET_CCUF_SyncClimateZone 2;
BA_ "InvalidValue" SG_ 1029 MHU_SET_CCUF_SyncClimateZone "3h";
BA_ "GenSigSendType" SG_ 1029 MHU_SET_CCUF_TempDriver 2;
BA_ "GenSigStartValue" SG_ 1029 MHU_SET_CCUF_TempDriver 40;
BA_ "InvalidValue" SG_ 1029 MHU_SET_CCUF_TempDriver "FFh";
BA_ "GenSigSendType" SG_ 1029 MHU_SET_CCUF_TempPassenger 2;
BA_ "GenSigStartValue" SG_ 1029 MHU_SET_CCUF_TempPassenger 40;
BA_ "InvalidValue" SG_ 1029 MHU_SET_CCUF_TempPassenger "FFh";
BA_ "GenSigSendType" SG_ 1029 MHU_SET_CCUF_FrontDefrost 2;
BA_ "InvalidValue" SG_ 1029 MHU_SET_CCUF_FrontDefrost "3h";
BA_ "GenSigSendType" SG_ 1030 MHU_SET_SeatHeatingFrontL 2;
BA_ "InvalidValue" SG_ 1030 MHU_SET_SeatHeatingFrontL "4h";
BA_ "GenSigSendType" SG_ 1030 MHU_SET_SeatHeatingFrontR 2;
BA_ "InvalidValue" SG_ 1030 MHU_SET_SeatHeatingFrontR "4h";
BA_ "GenSigSendType" SG_ 1030 MHU_SET_SeatHeatingReartL 2;
BA_ "InvalidValue" SG_ 1030 MHU_SET_SeatHeatingReartL "4h";
BA_ "GenSigSendType" SG_ 1030 MHU_SET_SeatHeatingRearR 2;
BA_ "InvalidValue" SG_ 1030 MHU_SET_SeatHeatingRearR "4h";
BA_ "GenSigSendType" SG_ 1030 MHU_SET_SeatCoolingFrontL 2;
BA_ "InvalidValue" SG_ 1030 MHU_SET_SeatCoolingFrontL "4h";
BA_ "GenSigSendType" SG_ 1030 MHU_SET_SeatCoolingFrontR 2;
BA_ "InvalidValue" SG_ 1030 MHU_SET_SeatCoolingFrontR "4h";
BA_ "GenSigSendType" SG_ 1030 MHU_SET_SeatCoolingRearL 2;
BA_ "InvalidValue" SG_ 1030 MHU_SET_SeatCoolingRearL "4h";
BA_ "GenSigSendType" SG_ 1030 MHU_SET_SeatCoolingRearR 2;
BA_ "InvalidValue" SG_ 1030 MHU_SET_SeatCoolingRearR "4h";
BA_ "GenSigSendType" SG_ 1032 MHU_SET_MirrorAuto 2;
BA_ "GenSigStartValue" SG_ 1032 MHU_SET_MirrorAuto 3;
BA_ "InvalidValue" SG_ 1032 MHU_SET_MirrorAuto "3h";
BA_ "GenSigSendType" SG_ 1032 MHU_SET_MirrorAutoUnfold 2;
BA_ "GenSigStartValue" SG_ 1032 MHU_SET_MirrorAutoUnfold 3;
BA_ "InvalidValue" SG_ 1032 MHU_SET_MirrorAutoUnfold "3h";
BA_ "GenSigSendType" SG_ 1032 MHU_SET_WLC 2;
BA_ "GenSigStartValue" SG_ 1032 MHU_SET_WLC 3;
BA_ "InvalidValue" SG_ 1032 MHU_SET_WLC "3h";
BA_ "GenSigSendType" SG_ 1032 MHU_SET_AutoRearWiper 2;
BA_ "GenSigStartValue" SG_ 1032 MHU_SET_AutoRearWiper 3;
BA_ "InvalidValue" SG_ 1032 MHU_SET_AutoRearWiper "3h";
BA_ "GenSigSendType" SG_ 1032 MHU_SET_RearHeatedWindow 2;
BA_ "InvalidValue" SG_ 1032 MHU_SET_RearHeatedWindow "3h";
BA_ "GenSigSendType" SG_ 1032 MHU_TPMSReset 2;
BA_ "InvalidValue" SG_ 1032 MHU_TPMSReset "3h";
BA_ "GenSigSendType" SG_ 1032 MHU_SET_MirrorDefaultSetting 2;
BA_ "GenSigStartValue" SG_ 1032 MHU_SET_MirrorDefaultSetting 3;
BA_ "InvalidValue" SG_ 1032 MHU_SET_MirrorDefaultSetting "3h";
BA_ "GenSigSendType" SG_ 1032 MHU_SET_MirrorReverseLink 2;
BA_ "GenSigStartValue" SG_ 1032 MHU_SET_MirrorReverseLink 1;
BA_ "GenSigSendType" SG_ 1032 MHU_SET_AntiTheftMode 2;
BA_ "GenSigStartValue" SG_ 1032 MHU_SET_AntiTheftMode 3;
BA_ "InvalidValue" SG_ 1032 MHU_SET_AntiTheftMode "3h";
BA_ "GenSigSendType" SG_ 1032 MHU_SET_WLCReminder 2;
BA_ "GenSigStartValue" SG_ 1032 MHU_SET_WLCReminder 1;
BA_ "InvalidValue" SG_ 1032 MHU_SET_WLCReminder "3h";
BA_ "GenSigSendType" SG_ 1032 MHU_SET_ClimateKeepOn 2;
BA_ "InvalidValue" SG_ 1032 MHU_SET_ClimateKeepOn "null";
BA_ "GenSigSendType" SG_ 1032 MHU_SET_WLC2 2;
BA_ "GenSigStartValue" SG_ 1032 MHU_SET_WLC2 1;
BA_ "InvalidValue" SG_ 1032 MHU_SET_WLC2 "3h";
BA_ "GenSigSendType" SG_ 1032 MHU_SET_WLC2Reminder 2;
BA_ "GenSigStartValue" SG_ 1032 MHU_SET_WLC2Reminder 1;
BA_ "InvalidValue" SG_ 1032 MHU_SET_WLC2Reminder "3h";
BA_ "GenSigSendType" SG_ 1032 MHU_IntrusionAlertStatus 2;
BA_ "GenSigStartValue" SG_ 1032 MHU_IntrusionAlertStatus 3;
BA_ "InvalidValue" SG_ 1032 MHU_IntrusionAlertStatus "3h";
BA_ "GenSigTimeoutTime_ALL" SG_ 1036 CHSKM_MHU_SEAT_CONTROL 1000;
BA_ "InvalidValue" SG_ 1036 CHSKM_MHU_SEAT_CONTROL "null";
BA_ "GenSigTimeoutTime_ALL" SG_ 1036 ALV_MHU_SEAT_CONTROL 1000;
BA_ "InvalidValue" SG_ 1036 ALV_MHU_SEAT_CONTROL "Fh";
BA_ "GenSigTimeoutTime_ALL" SG_ 1036 MHU_DrvSeat_Control_Status 1000;
BA_ "InvalidValue" SG_ 1036 MHU_DrvSeat_Control_Status "7h";
BA_ "GenSigTimeoutTime_ALL" SG_ 1036 MHU_ExpDrvReclinerPos 1000;
BA_ "InvalidValue" SG_ 1036 MHU_ExpDrvReclinerPos "7Fh";
BA_ "GenSigTimeoutTime_ALL" SG_ 1036 MHU_ExpDrvTiltPos 1000;
BA_ "InvalidValue" SG_ 1036 MHU_ExpDrvTiltPos "1Fh";
BA_ "GenSigTimeoutTime_ALL" SG_ 1036 MHU_ExpDrvTrackPos 1000;
BA_ "InvalidValue" SG_ 1036 MHU_ExpDrvTrackPos "FFh";
BA_ "GenSigTimeoutTime_ALL" SG_ 1036 MHU_ExpDrvHeightPos 1000;
BA_ "InvalidValue" SG_ 1036 MHU_ExpDrvHeightPos "3Fh";
BA_ "GenSigTimeoutTime_ALL" SG_ 1037 CHKSM_MHU_DIGIT_SPEED 1500;
BA_ "GenSigTimeoutTime_ALL" SG_ 1037 ALV_MHU_DIGIT_SPEED 1500;
BA_ "InvalidValue" SG_ 1037 ALV_MHU_DIGIT_SPEED "Fh";
BA_ "GenSigTimeoutTime_ALL" SG_ 1037 MHU_DigitSpeed 1500;
BA_ "InvalidValue" SG_ 1037 MHU_DigitSpeed "1FFh";
BA_ "GenSigTimeoutTime_ALL" SG_ 1044 CRC_SW_1 2500;
BA_ "GenSigTimeoutTime_ALL" SG_ 1044 Message_Counter_SW_1 2500;
BA_ "InvalidValue" SG_ 1044 Message_Counter_SW_1 "Fh";
BA_ "GenSigTimeoutTime_ALL" SG_ 1044 Calc_Threshold 2500;
BA_ "GenSigTimeoutTime_ALL" SG_ 1044 Real_Impedence 2500;
BA_ "GenSigTimeoutTime_ALL" SG_ 1044 Immag_Impedence 2500;
BA_ "GenSigTimeoutTime_ALL" SG_ 1044 ERR_ST_HOD 2500;
BA_ "GenSigTimeoutTime_ALL" SG_ 1044 RsErr_HOD 2500;
BA_ "GenSigTimeoutTime_ALL" SG_ 1044 HOD_status 2500;
BA_ "InvalidValue" SG_ 1044 HOD_status "Fh";
BA_ "GenSigStartValue" SG_ 1046 BCM_STAT_LeftMirrorPosX 15;
BA_ "GenSigTimeoutTime_ALL" SG_ 1046 BCM_STAT_LeftMirrorPosX 500;
BA_ "InvalidValue" SG_ 1046 BCM_STAT_LeftMirrorPosX "FFh";
BA_ "GenSigStartValue" SG_ 1046 BCM_STAT_LeftMirrorPosY 15;
BA_ "GenSigTimeoutTime_ALL" SG_ 1046 BCM_STAT_LeftMirrorPosY 500;
BA_ "InvalidValue" SG_ 1046 BCM_STAT_LeftMirrorPosY "FFh";
BA_ "GenSigStartValue" SG_ 1046 BCM_STAT_RightMirrorPosX 15;
BA_ "GenSigTimeoutTime_ALL" SG_ 1046 BCM_STAT_RightMirrorPosX 500;
BA_ "InvalidValue" SG_ 1046 BCM_STAT_RightMirrorPosX "FFh";
BA_ "GenSigStartValue" SG_ 1046 BCM_STAT_RightMirrorPosY 15;
BA_ "GenSigTimeoutTime_ALL" SG_ 1046 BCM_STAT_RightMirrorPosY 500;
BA_ "InvalidValue" SG_ 1046 BCM_STAT_RightMirrorPosY "FFh";
BA_ "GenSigTimeoutTime_ALL" SG_ 1046 BCM_STAT_Mirror 500;
BA_ "InvalidValue" SG_ 1046 BCM_STAT_Mirror "3h";
BA_ "GenSigTimeoutTime_ALL" SG_ 1046 BCM_STAT_MirrorAdjustLeft 500;
BA_ "InvalidValue" SG_ 1046 BCM_STAT_MirrorAdjustLeft "3h";
BA_ "GenSigTimeoutTime_ALL" SG_ 1046 BCM_STAT_MirrorAdjustRight 500;
BA_ "InvalidValue" SG_ 1046 BCM_STAT_MirrorAdjustRight "3h";
BA_ "GenSigSendType" SG_ 1049 SHVU_STAT_SeatHeatingFrontL 3;
BA_ "InvalidValue" SG_ 1049 SHVU_STAT_SeatHeatingFrontL "4h";
BA_ "GenSigSendType" SG_ 1049 SHVU_STAT_SeatHeatingFrontR 3;
BA_ "InvalidValue" SG_ 1049 SHVU_STAT_SeatHeatingFrontR "4h";
BA_ "GenSigSendType" SG_ 1049 SHVU_STAT_SeatCoolingFrontL 3;
BA_ "InvalidValue" SG_ 1049 SHVU_STAT_SeatCoolingFrontL "4h";
BA_ "GenSigSendType" SG_ 1049 SHVU_STAT_SeatCoolingFrontR 3;
BA_ "InvalidValue" SG_ 1049 SHVU_STAT_SeatCoolingFrontR "4h";
BA_ "GenSigSendType" SG_ 1049 SHVU_STAT_FrontSeatVentSts 3;
BA_ "InvalidValue" SG_ 1049 SHVU_STAT_FrontSeatVentSts "3h";
BA_ "GenSigSendType" SG_ 1050 SHVU_STAT_SeatCoolingRearL 3;
BA_ "InvalidValue" SG_ 1050 SHVU_STAT_SeatCoolingRearL "4h";
BA_ "GenSigSendType" SG_ 1050 SHVU_STAT_SeatCoolingRearR 3;
BA_ "InvalidValue" SG_ 1050 SHVU_STAT_SeatCoolingRearR "4h";
BA_ "GenSigSendType" SG_ 1050 SHVU_STAT_SeatHeatingReartL 3;
BA_ "InvalidValue" SG_ 1050 SHVU_STAT_SeatHeatingReartL "4h";
BA_ "GenSigSendType" SG_ 1050 SHVU_STAT_SeatHeatingRearR 3;
BA_ "InvalidValue" SG_ 1050 SHVU_STAT_SeatHeatingRearR "4h";
BA_ "GenSigSendType" SG_ 1050 SHVU_STAT_RearSeatVentSts 3;
BA_ "InvalidValue" SG_ 1050 SHVU_STAT_RearSeatVentSts "3h";
BA_ "GenSigTimeoutTime_ALL" SG_ 1052 CHKSM_PSM_SEAT_POSITION 5000;
BA_ "GenSigTimeoutTime_ALL" SG_ 1052 AVL_PSM_SEAT_POSITION 5000;
BA_ "InvalidValue" SG_ 1052 AVL_PSM_SEAT_POSITION "Fh";
BA_ "GenSigTimeoutTime_ALL" SG_ 1052 PSM_Seat_track_pos_Dri 5000;
BA_ "InvalidValue" SG_ 1052 PSM_Seat_track_pos_Dri "3h";
BA_ "GenSigTimeoutTime_ALL" SG_ 1052 PSM_Seat_track_posPas 5000;
BA_ "InvalidValue" SG_ 1052 PSM_Seat_track_posPas "3h";
BA_ "GenSigStartValue" SG_ 1053 BCM_STAT_AutoRearWiper 1;
BA_ "GenSigTimeoutTime_ALL" SG_ 1053 BCM_STAT_AutoRearWiper 500;
BA_ "InvalidValue" SG_ 1053 BCM_STAT_AutoRearWiper "3h";
BA_ "GenSigStartValue" SG_ 1053 BCM_STAT_MirrorFoldSetting 3;
BA_ "GenSigTimeoutTime_ALL" SG_ 1053 BCM_STAT_MirrorFoldSetting 500;
BA_ "InvalidValue" SG_ 1053 BCM_STAT_MirrorFoldSetting "3h";
BA_ "GenSigTimeoutTime_ALL" SG_ 1053 BCM_STAT_IMMO_KeyfobID2 500;
BA_ "GenSigTimeoutTime_ALL" SG_ 1053 BCM_STAT_MirrorAutoUnfold 500;
BA_ "InvalidValue" SG_ 1053 BCM_STAT_MirrorAutoUnfold "3h";
BA_ "GenSigStartValue" SG_ 1053 BCM_STAT_MirrorReverseLink 1;
BA_ "GenSigTimeoutTime_ALL" SG_ 1053 BCM_STAT_MirrorReverseLink 500;
BA_ "GenSigTimeoutTime_ALL" SG_ 1053 BCM_STAT_MirrorDefaultSTATting 500;
BA_ "InvalidValue" SG_ 1053 BCM_STAT_MirrorDefaultSTATting "3h";
BA_ "GenSigTimeoutTime_ALL" SG_ 1053 BCM_STAT_WelcomeTriggerCondition 500;
BA_ "InvalidValue" SG_ 1053 BCM_STAT_WelcomeTriggerCondition "3h";
BA_ "GenSigStartValue" SG_ 1053 BCM_STAT_FrontDomeLamp 1;
BA_ "GenSigTimeoutTime_ALL" SG_ 1053 BCM_STAT_FrontDomeLamp 500;
BA_ "InvalidValue" SG_ 1053 BCM_STAT_FrontDomeLamp "3h";
BA_ "GenSigTimeoutTime_ALL" SG_ 1053 BCM_STAT_FollowMeHome 500;
BA_ "InvalidValue" SG_ 1053 BCM_STAT_FollowMeHome "5h";
BA_ "GenSigTimeoutTime_ALL" SG_ 1053 BCM_STAT_ExteriorLight 500;
BA_ "InvalidValue" SG_ 1053 BCM_STAT_ExteriorLight "4h";
BA_ "GenSigStartValue" SG_ 1053 BCM_STAT_RemoteLockFeedback 7;
BA_ "GenSigTimeoutTime_ALL" SG_ 1053 BCM_STAT_RemoteLockFeedback 500;
BA_ "InvalidValue" SG_ 1053 BCM_STAT_RemoteLockFeedback "7h";
BA_ "GenSigStartValue" SG_ 1053 BCM_STAT_RemoteDoorUnlock 3;
BA_ "GenSigTimeoutTime_ALL" SG_ 1053 BCM_STAT_RemoteDoorUnlock 500;
BA_ "InvalidValue" SG_ 1053 BCM_STAT_RemoteDoorUnlock "3h";
BA_ "GenSigStartValue" SG_ 1053 BCM_STAT_AutoDoorUnlock 3;
BA_ "GenSigTimeoutTime_ALL" SG_ 1053 BCM_STAT_AutoDoorUnlock 500;
BA_ "InvalidValue" SG_ 1053 BCM_STAT_AutoDoorUnlock "3h";
BA_ "GenSigTimeoutTime_ALL" SG_ 1053 BCM_STAT_WalkawayDoorLock 500;
BA_ "GenSigSendType" SG_ 1053 BCM_STAT_WalkawayDoorLock 2;
BA_ "GenSigStartValue" SG_ 1053 BCM_STAT_AmbientLightBrighness 80;
BA_ "GenSigTimeoutTime_ALL" SG_ 1053 BCM_STAT_AmbientLightBrighness 500;
BA_ "InvalidValue" SG_ 1053 BCM_STAT_AmbientLightBrighness "7Fh";
BA_ "GenSigStartValue" SG_ 1053 BCM_STAT_WiperServiceMode 3;
BA_ "GenSigTimeoutTime_ALL" SG_ 1053 BCM_STAT_WiperServiceMode 500;
BA_ "InvalidValue" SG_ 1053 BCM_STAT_WiperServiceMode "3h";
BA_ "GenSigStartValue" SG_ 1053 BCM_STAT_IMMO_KeyfobID 3;
BA_ "GenSigTimeoutTime_ALL" SG_ 1053 BCM_STAT_IMMO_KeyfobID 500;
BA_ "InvalidValue" SG_ 1053 BCM_STAT_IMMO_KeyfobID "3h";
BA_ "GenSigTimeoutTime_ALL" SG_ 1053 BCM_STAT_RearHeatedWindowMirror 500;
BA_ "InvalidValue" SG_ 1053 BCM_STAT_RearHeatedWindowMirror "3h";
BA_ "GenSigStartValue" SG_ 1053 BCM_STAT_AntiTheftMode 3;
BA_ "GenSigTimeoutTime_ALL" SG_ 1053 BCM_STAT_AntiTheftMode 500;
BA_ "InvalidValue" SG_ 1053 BCM_STAT_AntiTheftMode "4h";
BA_ "GenSigTimeoutTime_ALL" SG_ 1053 BCM_STAT_ClimateKeepOnSts 500;
BA_ "InvalidValue" SG_ 1053 BCM_STAT_ClimateKeepOnSts "null";
BA_ "GenSigTimeoutTime_ALL" SG_ 1053 BCM_STAT_FKSfeedback 500;
BA_ "InvalidValue" SG_ 1053 BCM_STAT_FKSfeedback "3h";
BA_ "GenSigTimeoutTime_ALL" SG_ 1053 SECCAN_CmftCnfrm 500;
BA_ "InvalidValue" SG_ 1053 SECCAN_CmftCnfrm "null";
BA_ "GenSigTimeoutTime_ALL" SG_ 1055 OCS_P_CHKSM 2500;
BA_ "GenSigTimeoutTime_ALL" SG_ 1055 OCS_P_AVL 2500;
BA_ "InvalidValue" SG_ 1055 OCS_P_AVL "Fh";
BA_ "GenSigStartValue" SG_ 1055 OCS_Passenger_class_stat 1;
BA_ "GenSigTimeoutTime_ALL" SG_ 1055 OCS_Passenger_class_stat 2500;
BA_ "InvalidValue" SG_ 1055 OCS_Passenger_class_stat "3h";
BA_ "GenSigTimeoutTime_ALL" SG_ 1058 CHKSM_MHU_STAT 5000;
BA_ "InvalidValue" SG_ 1058 CHKSM_MHU_STAT "null";
BA_ "GenSigTimeoutTime_ALL" SG_ 1058 ALV_MHU_STAT 5000;
BA_ "InvalidValue" SG_ 1058 ALV_MHU_STAT "Fh";
BA_ "GenSigTimeoutTime_ALL" SG_ 1058 MHU_STAT_Cluster 5000;
BA_ "InvalidValue" SG_ 1058 MHU_STAT_Cluster "3h";
BA_ "GenSigTimeoutTime_ALL" SG_ 1058 MHU_STAT_Infotainment 5000;
BA_ "InvalidValue" SG_ 1058 MHU_STAT_Infotainment "3h";
BA_ "GenSigStartValue" SG_ 1058 MHU_STAT_MileageUnit 3;
BA_ "GenSigTimeoutTime_ALL" SG_ 1058 MHU_STAT_MileageUnit 5000;
BA_ "InvalidValue" SG_ 1058 MHU_STAT_MileageUnit "3h";
BA_ "GenSigStartValue" SG_ 1058 MHU_STAT_PressureUnit 3;
BA_ "GenSigTimeoutTime_ALL" SG_ 1058 MHU_STAT_PressureUnit 5000;
BA_ "InvalidValue" SG_ 1058 MHU_STAT_PressureUnit "3h";
BA_ "GenSigStartValue" SG_ 1058 MHU_STAT_TemperatureUnit 3;
BA_ "GenSigTimeoutTime_ALL" SG_ 1058 MHU_STAT_TemperatureUnit 5000;
BA_ "InvalidValue" SG_ 1058 MHU_STAT_TemperatureUnit "3h";
BA_ "GenSigTimeoutTime_ALL" SG_ 1058 MHU_Operation_State 5000;
BA_ "InvalidValue" SG_ 1058 MHU_Operation_State "7h";
BA_ "GenSigStartValue" SG_ 1058 MHU_STAT_Language 31;
BA_ "GenSigTimeoutTime_ALL" SG_ 1058 MHU_STAT_Language 5000;
BA_ "InvalidValue" SG_ 1058 MHU_STAT_Language "1Fh";
BA_ "GenSigStartValue" SG_ 1058 MHU_STAT_EnergyConsumptionUnit 7;
BA_ "GenSigTimeoutTime_ALL" SG_ 1058 MHU_STAT_EnergyConsumptionUnit 5000;
BA_ "InvalidValue" SG_ 1058 MHU_STAT_EnergyConsumptionUnit "Fh";
BA_ "GenSigTimeoutTime_ALL" SG_ 1058 BAS_version 5000;
BA_ "GenSigStartValue" SG_ 1058 MHU_STAT_SaleCountry 1023;
BA_ "GenSigTimeoutTime_ALL" SG_ 1058 MHU_STAT_SaleCountry 5000;
BA_ "InvalidValue" SG_ 1058 MHU_STAT_SaleCountry "3FFh";
BA_ "GenSigTimeoutTime_ALL" SG_ 1068 CHSKM_PSM_D_SEAT_CONTROL 1000;
BA_ "InvalidValue" SG_ 1068 CHSKM_PSM_D_SEAT_CONTROL "null";
BA_ "GenSigTimeoutTime_ALL" SG_ 1068 ALV_PSM_D_SEAT_CONTROL 1000;
BA_ "InvalidValue" SG_ 1068 ALV_PSM_D_SEAT_CONTROL "Fh";
BA_ "GenSigTimeoutTime_ALL" SG_ 1068 PSM_D_DrvSeat_Control_Status 1000;
BA_ "InvalidValue" SG_ 1068 PSM_D_DrvSeat_Control_Status "7h";
BA_ "GenSigTimeoutTime_ALL" SG_ 1068 PSM_D_DrvReclinerPos 1000;
BA_ "InvalidValue" SG_ 1068 PSM_D_DrvReclinerPos "7Fh";
BA_ "GenSigTimeoutTime_ALL" SG_ 1068 PSM_D_DrvTiltPos 1000;
BA_ "InvalidValue" SG_ 1068 PSM_D_DrvTiltPos "1Fh";
BA_ "GenSigTimeoutTime_ALL" SG_ 1068 PSM_D_DrvTrackPos 1000;
BA_ "InvalidValue" SG_ 1068 PSM_D_DrvTrackPos "FFh";
BA_ "GenSigTimeoutTime_ALL" SG_ 1068 PSM_D_DrvHeightPos 1000;
BA_ "InvalidValue" SG_ 1068 PSM_D_DrvHeightPos "3Fh";
BA_ "GenSigTimeoutTime_ALL" SG_ 1074 MHU_FOTA_Checksum 2500;
BA_ "InvalidValue" SG_ 1074 MHU_FOTA_Checksum "null";
BA_ "GenSigTimeoutTime_ALL" SG_ 1074 MHU_FOTA_Alive_Counter 2500;
BA_ "InvalidValue" SG_ 1074 MHU_FOTA_Alive_Counter "Fh";
BA_ "GenSigTimeoutTime_ALL" SG_ 1074 MHU_FOTA_State 2500;
BA_ "InvalidValue" SG_ 1074 MHU_FOTA_State "7h";
BA_ "GenSigTimeoutTime_ALL" SG_ 1074 MHU_FOTA_Error_Code 2500;
BA_ "InvalidValue" SG_ 1074 MHU_FOTA_Error_Code "null";
BA_ "GenSigSendType" SG_ 1077 BCM_SCM_BC_Button 4;
BA_ "InvalidValue" SG_ 1077 BCM_SCM_BC_Button "3h";
BA_ "GenSigTimeoutTime_ALL" SG_ 1082 CRC_VCU_MHU_info 1000;
BA_ "InvalidValue" SG_ 1082 CRC_VCU_MHU_info "null";
BA_ "GenSigTimeoutTime_ALL" SG_ 1082 ALIV_VCU_MHU_info 500;
BA_ "InvalidValue" SG_ 1082 ALIV_VCU_MHU_info "Fh";
BA_ "GenSigTimeoutTime_ALL" SG_ 1082 VCU_BrakeRegenMode 1000;
BA_ "GenSigTimeoutTime_ALL" SG_ 1082 VCU_CreepDisable_stt 1000;
BA_ "InvalidValue" SG_ 1082 VCU_CreepDisable_stt "null";
BA_ "GenSigStartValue" SG_ 1082 VCU_PowerRegenGaugeDisplay 100;
BA_ "GenSigTimeoutTime_ALL" SG_ 1082 VCU_PowerRegenGaugeDisplay 1000;
BA_ "InvalidValue" SG_ 1082 VCU_PowerRegenGaugeDisplay "FFh";
BA_ "GenSigTimeoutTime_ALL" SG_ 1082 VCU_Charging_Authen_stt 500;
BA_ "InvalidValue" SG_ 1082 VCU_Charging_Authen_stt "null";
BA_ "GenSigTimeoutTime_ALL" SG_ 1082 VCU_ChgGun_BadConn_stt 500;
BA_ "InvalidValue" SG_ 1082 VCU_ChgGun_BadConn_stt "null";
BA_ "GenSigTimeoutTime_ALL" SG_ 1082 VCU_ChgPort_Open_stt 1000;
BA_ "InvalidValue" SG_ 1082 VCU_ChgPort_Open_stt "null";
BA_ "GenSigStartValue" SG_ 1082 VCU_Regen_available 1;
BA_ "GenSigTimeoutTime_ALL" SG_ 1082 VCU_Regen_available 500;
BA_ "InvalidValue" SG_ 1082 VCU_Regen_available "null";
BA_ "GenSigTimeoutTime_ALL" SG_ 1082 VCU_VehChg_STS 1000;
BA_ "InvalidValue" SG_ 1082 VCU_VehChg_STS "null";
BA_ "GenSigTimeoutTime_ALL" SG_ 1082 VCU_SOC_display 500;
BA_ "InvalidValue" SG_ 1082 VCU_SOC_display "null";
BA_ "GenSigStartValue" SG_ 1082 VCU_ChgGun_Status 7;
BA_ "GenSigTimeoutTime_ALL" SG_ 1082 VCU_ChgGun_Status 500;
BA_ "InvalidValue" SG_ 1082 VCU_ChgGun_Status "7h";
BA_ "GenSigTimeoutTime_ALL" SG_ 1082 VCU_ChgPort_Lock_stt 1000;
BA_ "InvalidValue" SG_ 1082 VCU_ChgPort_Lock_stt "null";
BA_ "GenSigTimeoutTime_ALL" SG_ 1082 VCU_Hvbatt_charging_stt 1000;
BA_ "InvalidValue" SG_ 1082 VCU_Hvbatt_charging_stt "null";
BA_ "GenSigSendType" SG_ 1089 CHKSM_RESP_REM_FUNC_APM 2;
BA_ "InvalidValue" SG_ 1089 CHKSM_RESP_REM_FUNC_APM "null";
BA_ "GenSigSendType" SG_ 1089 RESP_REM_ResponseID_APM 2;
BA_ "InvalidValue" SG_ 1089 RESP_REM_ResponseID_APM "FFh";
BA_ "GenSigSendType" SG_ 1089 RESP_REM_DataByte0_APM 2;
BA_ "InvalidValue" SG_ 1089 RESP_REM_DataByte0_APM "FFh";
BA_ "GenSigSendType" SG_ 1089 RESP_REM_DataByte1_APM 2;
BA_ "InvalidValue" SG_ 1089 RESP_REM_DataByte1_APM "FFh";
BA_ "GenSigSendType" SG_ 1089 RESP_REM_DataByte2_APM 2;
BA_ "InvalidValue" SG_ 1089 RESP_REM_DataByte2_APM "FFh";
BA_ "GenSigSendType" SG_ 1089 RESP_REM_DataByte3_APM 2;
BA_ "InvalidValue" SG_ 1089 RESP_REM_DataByte3_APM "FFh";
BA_ "GenSigSendType" SG_ 1089 RESP_REM_DataByte4_APM 2;
BA_ "InvalidValue" SG_ 1089 RESP_REM_DataByte4_APM "FFh";
BA_ "GenSigSendType" SG_ 1089 RESP_REM_LengthTyp_APM 2;
BA_ "InvalidValue" SG_ 1089 RESP_REM_LengthTyp_APM "3h";
BA_ "GenSigSendType" SG_ 1089 RESP_REM_DataLength_APM 2;
BA_ "InvalidValue" SG_ 1089 RESP_REM_DataLength_APM "3Fh";
BA_ "GenSigTimeoutTime_ALL" SG_ 1090 WLC_IC_Error 2500;
BA_ "InvalidValue" SG_ 1090 WLC_IC_Error "null";
BA_ "GenSigTimeoutTime_ALL" SG_ 1090 WLC_FAN_Error 2500;
BA_ "InvalidValue" SG_ 1090 WLC_FAN_Error "null";
BA_ "GenSigTimeoutTime_ALL" SG_ 1090 WLC_TempSNSR_Error 2500;
BA_ "InvalidValue" SG_ 1090 WLC_TempSNSR_Error "null";
BA_ "GenSigStartValue" SG_ 1090 WLC_Setting_standard 2;
BA_ "GenSigTimeoutTime_ALL" SG_ 1090 WLC_Setting_standard 2500;
BA_ "InvalidValue" SG_ 1090 WLC_Setting_standard "null";
BA_ "GenSigTimeoutTime_ALL" SG_ 1090 Transmit_WLC_situation 2500;
BA_ "InvalidValue" SG_ 1090 Transmit_WLC_situation "null";
BA_ "GenSigTimeoutTime_ALL" SG_ 1090 WLC_VehSpeed_Error 2500;
BA_ "InvalidValue" SG_ 1090 WLC_VehSpeed_Error "null";
BA_ "GenSigTimeoutTime_ALL" SG_ 1090 WLC_Resp_Error 2500;
BA_ "InvalidValue" SG_ 1090 WLC_Resp_Error "null";
BA_ "GenSigTimeoutTime_ALL" SG_ 1090 WLC_FOD_Error 2500;
BA_ "InvalidValue" SG_ 1090 WLC_FOD_Error "null";
BA_ "GenSigTimeoutTime_ALL" SG_ 1090 WLC_Curr_Error 2500;
BA_ "InvalidValue" SG_ 1090 WLC_Curr_Error "null";
BA_ "GenSigTimeoutTime_ALL" SG_ 1090 WLC_Temp_Error 2500;
BA_ "InvalidValue" SG_ 1090 WLC_Temp_Error "null";
BA_ "GenSigTimeoutTime_ALL" SG_ 1091 WLC_IC_Error_2 2500;
BA_ "InvalidValue" SG_ 1091 WLC_IC_Error_2 "null";
BA_ "GenSigTimeoutTime_ALL" SG_ 1091 WLC_FAN_Error_2 2500;
BA_ "InvalidValue" SG_ 1091 WLC_FAN_Error_2 "null";
BA_ "GenSigTimeoutTime_ALL" SG_ 1091 WLC_TempSNSR_Error_2 2500;
BA_ "InvalidValue" SG_ 1091 WLC_TempSNSR_Error_2 "null";
BA_ "GenSigStartValue" SG_ 1091 WLC_Setting_standard_2 2;
BA_ "GenSigTimeoutTime_ALL" SG_ 1091 WLC_Setting_standard_2 2500;
BA_ "InvalidValue" SG_ 1091 WLC_Setting_standard_2 "null";
BA_ "GenSigTimeoutTime_ALL" SG_ 1091 Transmit_WLC_situation_2 2500;
BA_ "InvalidValue" SG_ 1091 Transmit_WLC_situation_2 "null";
BA_ "GenSigTimeoutTime_ALL" SG_ 1091 WLC_VehSpeed_Error_2 2500;
BA_ "InvalidValue" SG_ 1091 WLC_VehSpeed_Error_2 "null";
BA_ "GenSigTimeoutTime_ALL" SG_ 1091 WLC_Resp_Error_2 2500;
BA_ "InvalidValue" SG_ 1091 WLC_Resp_Error_2 "null";
BA_ "GenSigTimeoutTime_ALL" SG_ 1091 WLC_FOD_Error_2 2500;
BA_ "InvalidValue" SG_ 1091 WLC_FOD_Error_2 "null";
BA_ "GenSigTimeoutTime_ALL" SG_ 1091 WLC_Curr_Error_2 2500;
BA_ "InvalidValue" SG_ 1091 WLC_Curr_Error_2 "null";
BA_ "GenSigTimeoutTime_ALL" SG_ 1091 WLC_Temp_Error_2 2500;
BA_ "InvalidValue" SG_ 1091 WLC_Temp_Error_2 "null";
BA_ "GenSigTimeoutTime_ALL" SG_ 1093 RS_Sol_L 500;
BA_ "InvalidValue" SG_ 1093 RS_Sol_L "FFh";
BA_ "GenSigTimeoutTime_ALL" SG_ 1093 RS_Sol_R 500;
BA_ "InvalidValue" SG_ 1093 RS_Sol_R "FFh";
BA_ "GenSigTimeoutTime_ALL" SG_ 1093 RS_F_LightSensor 500;
BA_ "GenSigTimeoutTime_ALL" SG_ 1093 RS_F_HUD_Sensor 500;
BA_ "InvalidValue" SG_ 1093 RS_F_HUD_Sensor "null";
BA_ "GenSigTimeoutTime_ALL" SG_ 1093 RS_St_LampReq 500;
BA_ "InvalidValue" SG_ 1093 RS_St_LampReq "3h";
BA_ "GenSigTimeoutTime_ALL" SG_ 1093 RS_St_CurrentRain 500;
BA_ "InvalidValue" SG_ 1093 RS_St_CurrentRain "7h";
BA_ "GenSigTimeoutTime_ALL" SG_ 1093 RS_HUD_illuminance 500;
BA_ "InvalidValue" SG_ 1093 RS_HUD_illuminance "FFFFh";
BA_ "GenSigTimeoutTime_ALL" SG_ 1095 CHKSM_MHU_SET_CarMode 1000;
BA_ "InvalidValue" SG_ 1095 CHKSM_MHU_SET_CarMode "null";
BA_ "GenSigTimeoutTime_ALL" SG_ 1095 ALV_MHU_SET_CarMode 1000;
BA_ "InvalidValue" SG_ 1095 ALV_MHU_SET_CarMode "Fh";
BA_ "GenSigTimeoutTime_ALL" SG_ 1095 MHU_SET_TransportMode 1000;
BA_ "InvalidValue" SG_ 1095 MHU_SET_TransportMode "3h";
BA_ "GenSigTimeoutTime_ALL" SG_ 1095 MHU_Request_CarOFF 1000;
BA_ "InvalidValue" SG_ 1095 MHU_Request_CarOFF "3h";
BA_ "GenSigTimeoutTime_ALL" SG_ 1095 MHU_SET_ChildMode 1000;
BA_ "InvalidValue" SG_ 1095 MHU_SET_ChildMode "null";
BA_ "GenSigTimeoutTime_ALL" SG_ 1095 MHU_SET_GameMode 1000;
BA_ "InvalidValue" SG_ 1095 MHU_SET_GameMode "null";
BA_ "GenSigTimeoutTime_ALL" SG_ 1095 MHU_SET_KaraokeMode 1000;
BA_ "InvalidValue" SG_ 1095 MHU_SET_KaraokeMode "3h";
BA_ "GenSigTimeoutTime_ALL" SG_ 1095 MHU_SET_WashMode 1000;
BA_ "InvalidValue" SG_ 1095 MHU_SET_WashMode "3h";
BA_ "GenSigTimeoutTime_ALL" SG_ 1095 MHU_SET_StopMode 1000;
BA_ "InvalidValue" SG_ 1095 MHU_SET_StopMode "3h";
BA_ "GenSigTimeoutTime_ALL" SG_ 1095 MHU_AVH_Sw 1000;
BA_ "InvalidValue" SG_ 1095 MHU_AVH_Sw "3h";
BA_ "GenSigSendType" SG_ 1104 WindowLifterFrontL 2;
BA_ "InvalidValue" SG_ 1104 WindowLifterFrontL "7h";
BA_ "GenSigSendType" SG_ 1104 WindowLifterFrontR 2;
BA_ "InvalidValue" SG_ 1104 WindowLifterFrontR "7h";
BA_ "GenSigSendType" SG_ 1104 WindowLifterRearL 2;
BA_ "InvalidValue" SG_ 1104 WindowLifterRearL "7h";
BA_ "GenSigSendType" SG_ 1104 WindowLifterRearR 2;
BA_ "InvalidValue" SG_ 1104 WindowLifterRearR "7h";
BA_ "GenSigSendType" SG_ 1104 MHU_SET_WindowAutoClose 2;
BA_ "InvalidValue" SG_ 1104 MHU_SET_WindowAutoClose "3h";
BA_ "GenSigSendType" SG_ 1110 OP_WISW_SZL_LIN 3;
BA_ "InvalidValue" SG_ 1110 OP_WISW_SZL_LIN "null";
BA_ "GenSigSendType" SG_ 1110 COMM_ERR_SZL_LIN 3;
BA_ "InvalidValue" SG_ 1110 COMM_ERR_SZL_LIN "null";
BA_ "GenSigSendType" SG_ 1110 BCM_Wiper_Front_Status 3;
BA_ "InvalidValue" SG_ 1110 BCM_Wiper_Front_Status "null";
BA_ "GenSigSendType" SG_ 1110 OP_WIPO_SZL_LIN 3;
BA_ "InvalidValue" SG_ 1110 OP_WIPO_SZL_LIN "null";
BA_ "GenSigSendType" SG_ 1110 OP_COLS_SZL_LIN 3;
BA_ "InvalidValue" SG_ 1110 OP_COLS_SZL_LIN "null";
BA_ "GenSigSendType" SG_ 1110 NOD_ERR_SZL_LIN 3;
BA_ "InvalidValue" SG_ 1110 NOD_ERR_SZL_LIN "null";
BA_ "GenSigSendType" SG_ 1110 BCM_Wiper_Rear_Status 3;
BA_ "InvalidValue" SG_ 1110 BCM_Wiper_Rear_Status "null";
BA_ "GenSigSendType" SG_ 1110 ALIV_WISW_SZL_LIN 3;
BA_ "InvalidValue" SG_ 1110 ALIV_WISW_SZL_LIN "Fh";
BA_ "GenSigSendType" SG_ 1111 AmbLight_Error_Z5 3;
BA_ "InvalidValue" SG_ 1111 AmbLight_Error_Z5 "null";
BA_ "GenSigSendType" SG_ 1111 AmbLight_Error_Z4 3;
BA_ "InvalidValue" SG_ 1111 AmbLight_Error_Z4 "null";
BA_ "GenSigSendType" SG_ 1111 AmbLight_Error_Z3 3;
BA_ "InvalidValue" SG_ 1111 AmbLight_Error_Z3 "null";
BA_ "GenSigSendType" SG_ 1111 AmbLight_Error_Z2 3;
BA_ "InvalidValue" SG_ 1111 AmbLight_Error_Z2 "null";
BA_ "GenSigSendType" SG_ 1111 AmbLight_Error_Z1 3;
BA_ "InvalidValue" SG_ 1111 AmbLight_Error_Z1 "null";
VAL_ 584 NDoorFRHomeSignal 0 "Home" 1 "not Home" ;
VAL_ 584 NDoorFRSecondarySignal 0 "Secondary" 1 "Not Secondary" ;
VAL_ 584 NDoorFRPrimarySignal 0 "Primary" 1 "Not Primary" ;
VAL_ 584 NDoorFRClawSignal 0 "Claw" 1 "not Claw" ;
VAL_ 584 NDoorFRClawStatus 0 "Closed" 1 "Secondary" 2 "Signal Invalid" 3 "Signal Invalid" 4 "Signal Invalid" 5 "Open" 6 "Signal Invalid" 7 "Signal Invalid" 8 "Signal Invalid" 9 "Signal Invalid" 10 "Signal Invalid" 11 "Signal Invalid" 12 "Signal Invalid" 13 "Signal Invalid" 14 "Signal Invalid" 15 "Default" ;
VAL_ 584 BDLFRResponseError 0 "no error" 1 "error" ;
VAL_ 584 NDoorFROutsideHandleFailure 0 "Default (No Failure)" 1 "EEPROM, ROM and DSP self-test" 2 "Magnetic field is too low" 3 "Magnetic field is too high" 4 "Overvoltage" 5 "Undervoltage" 6 "A/D converter clipping" 7 "Reserved" ;
VAL_ 584 NDoorFROutsideHandleStatus 0 "Trigger" 1 "Not trigger" ;
VAL_ 584 NDoorLatchFRFailure 0 "No Fault" 1 "Fault Code" 2 "Fault Code" 3 "Fault Code" 4 "Fault Code" 5 "Fault Code" 6 "Fault Code" 7 "Fault Code" 8 "Fault Code" 9 "Fault Code" 10 "Fault Code" 11 "Fault Code" 12 "Fault Code" 13 "Fault Code" 14 "Fault Code" 127 "Fault Code" ;
VAL_ 592 BMS_VCU_PTCOnOff_Req 0 "OFF" 1 "ON" ;
VAL_ 592 BMS_VCU_ValveOnOff_Req 0 "close" 1 "open" ;
VAL_ 592 BMS_PreHeatCoolReq 0 "Precondition OFF" 1 "Precondition Heating ON" 2 "Precondition Cooling ON" 3 "Invalid value";
VAL_ 593 NDoorRLVehicleLocked 0 "default (locked)" 2 "unlocked (inactive)" 3 "locked (full decouple)" ;
VAL_ 593 NDoorRLVehicleMoving 0 "default (in motion)" 1 "Reserved" 2 "static (inactive)" 3 "in motion (decouple external)" ;
VAL_ 593 NDoorRLOpenInvRequested 0 "default (release inactive)" 1 "Reserved" 2 "open (active release request)" 3 "close (release inactive)" ;
VAL_ 593 NDoorRLOpenRequested 0 "close (release inactive)" 1 "open (release request active)" 3 "default (release inactive)" ;
VAL_ 593 NDoorRLChildLocked 0 "default (locked)" 2 "unlocked (inactive)" 3 "locked (full decouple)" ;
VAL_ 593 NDoorRLVehicleCrash 0 "default (locked)" 2 "Not trigger (inactive)" 3 "Trigger (full decouple)" ;
VAL_ 593 NDoorRLCloseInvRequested 0 "Default (Cinch Latching Inactive)" 1 "Reserved" 2 "Open (Active Cinch Latching Request)" 3 "Close (Cinch Latching Inactive)" ;
VAL_ 593 NDoorRLCloseRequested 0 "Default (Cinch Latching Inactive)" 1 "Reserved" 2 "Open (Active Cinch Latching Request)" 3 "Close (Cinch Latching Inactive)" ;
VAL_ 596 QU_AVL_RPM_WHL_RLH 1 "Signal value is valid and secured and checked for plausibility" 2 "Reserved" 3 "Reserved" 4 "Substitute value is set in the useful signal" 6 "Signal value is invalid (Electrical fault, can be repaired)" 7 "Reserved" 8 "initialization" 9 "Reserved" 10 "Reserved" 11 "Signal quality or monitoring restricted, state / status temporary" 12 "Substitute value is set in the useful signal State / status temporary" 14 "Signal value is invalid (Electrical fault, can not repaired)" 15 "Signal invalid" ;
VAL_ 596 QU_AVL_RPM_WHL_RRH 1 "Signal value is valid and secured and checked for plausibility" 2 "Reserved" 3 "Reserved" 4 "Substitute value is set in the useful signal" 6 "Signal value is invalid (Electrical fault, can be repaired)" 7 "Reserved" 8 "initialization" 9 "Reserved" 10 "Reserved" 11 "Signal quality or monitoring restricted, state / status temporary" 12 "Substitute value is set in the useful signal State / status temporary" 14 "Signal value is invalid (Electrical fault, can not repaired)" 15 "Signal invalid" ;
VAL_ 597 QU_AVL_RPM_WHL_FLH 1 "Signal value is valid and secured and checked for plausibility" 2 "Reserved" 3 "Reserved" 4 "Substitute value is set in the useful signal" 6 "Signal value is invalid (Electrical fault, can be repaired)" 7 "Reserved" 8 "initialization" 9 "Reserved" 10 "Reserved" 11 "Signal quality or monitoring restricted, state / status temporary" 12 "Substitute value is set in the useful signal State / status temporary" 14 "Signal value is invalid (Electrical fault, can not repaired)" 15 "Signal invalid" ;
VAL_ 597 QU_AVL_RPM_WHL_FRH 1 "Signal value is valid and secured and checked for plausibility" 2 "Reserved" 3 "Reserved" 4 "Substitute value is set in the useful signal" 6 "Signal value is invalid (Electrical fault, can be repaired)" 7 "Reserved" 8 "initialization" 9 "Reserved" 10 "Reserved" 11 "Signal quality or monitoring restricted, state / status temporary" 12 "Substitute value is set in the useful signal State / status temporary" 14 "Signal value is invalid (Electrical fault, can not repaired)" 15 "Signal invalid" ;
VAL_ 598 BCM_Animation_Req 0 "not active" 1 "welcome mode1 request" 2 "welcome mode 2 request" 3 "welcome mode 3 request" 4 "shutdown mode 1 request" 5 "shutdowm mode 2 request" 6 "shutdowm mode 3 request" 7 "invalid" ;
VAL_ 598 BCM_Charging_Sts 0 "not plug-in" 1 "plug-in but not charging" 2 "plug-in and charging" 3 "charging error" 4 "reserved" 5 "reserved" 6 "reserved" 7 "invalid" ;
VAL_ 598 BCM_Lock_Sts 0 "unlocked" 1 "locked" 2 "reserved" 3 "invalid" ;
VAL_ 598 BCM_Panic_Status 0 "panic not active" 1 "panic active" ;
VAL_ 598 BCM_Charging_SOC 0 "0%-10%" 1 "10%-20%" 2 "20%-30%" 3 "30%-40%" 4 "40%-50%" 5 "50%-60%" 6 "60%-70%" 7 "70%-80%" 8 "80%-90%" 9 "90%-100%" 10 "100%" 11 "reserved" 12 "reserved" 13 "reserved" 14 "reserved" 15 "invalid" ;
VAL_ 598 BCM_LeftPosLmpSts 0 "Pos Left OFF" 1 "Pos Left ON" 2 "Fault (Reserved)" 3 "Signal Invalid" ;
VAL_ 598 BCM_RightPosLmpSts 0 "Pos Right OFF" 1 "Pos Right ON" 2 "Fault (Reserved)" 3 "Signal Invalid" ;
VAL_ 618 ST_ECU_ST_LCS_VEH 0 "Zustand Initialisierung" 1 "Zustand Normalbetrieb" 2 "Zustand Normalbetrieb/Überspannu" 3 "Zustand Normalbetrieb/Unterspann" 4 "Zustand Diagnose" 5 "Zustand Diagnose/Überspannung se" 6 "Zustand Diagnose/Unterspannung s" 7 "Zustand Powerdown" 8 "Zustand PowerSave" 9 "Zustand Nicht verfügbar" 10 "Zustand Reset" 11 "Zustand Reserviert 11" 12 "Zustand Reserviert 12" 13 "Zustand Reserviert 13" 14 "Zustand Reserviert 14" 15 "Signal ungültig" ;
VAL_ 618 QU_FN_LCS_VEH 16533 "Signal invalid" ;
VAL_ 641 NDoorRLHomeSignal 0 "Home" 1 "not Home" ;
VAL_ 641 NDoorRLSecondarySignal 0 "Secondary" 1 "not Secondary" ;
VAL_ 641 NDoorRLPrimarySignal 0 "Primary" 1 "Not Primary" ;
VAL_ 641 NDoorRLClawSignal 0 "Claw" 1 "Not Claw" ;
VAL_ 641 NDoorRLClawStatus 0 "Closed" 1 "Secondary" 2 "Signal Invalid" 3 "Signal Invalid" 4 "Signal Invalid" 5 "Open" 6 "Signal Invalid" 7 "Signal Invalid" 8 "Signal Invalid" 9 "Signal Invalid" 10 "Signal Invalid" 11 "Signal Invalid" 12 "Signal Invalid" 13 "Signal Invalid" 14 "Signal Invalid" 15 "Default" ;
VAL_ 641 BDLRLResponseError 0 "no error" 1 "error" ;
VAL_ 641 NDoorRLOutsideHandleFailure 0 "Default (No Failure)" 1 "EEPROM, ROM and DSP self-test" 2 "Magnetic field is too low" 3 "Magnetic field is too high" 4 "Overvoltage" 5 "Undervoltage" 6 "A/D converter clipping" 7 "Reserved" ;
VAL_ 641 NDoorRLOutsideHandleStatus 0 "Trigger" 1 "Not trigger" ;
VAL_ 641 NDoorLatchRLFailure 0 "no fault" 1 "fault code" 2 "fault code" 3 "fault code" 4 "fault code" 5 "fault code" 6 "fault code" 63 "fault code" ;
VAL_ 649 AxOutStatus 0 "Valid" 1 "Invalid" ;
VAL_ 649 QU_VYAW_VEH 0 "Description for the value '0x0'" 1 "Description for the value '0x1'" ;
VAL_ 649 AyOutStatus 0 "Valid" 1 "Invalid" ;
VAL_ 649 AcceleratorY 16533 "Invalid" ;
VAL_ 649 AcceleratorX 16533 "Invalid" ;
VAL_ 654 Window_PosFL 0 "Closed (top)" 1 "Open (bottom)" 2 "Between 80% to closed" 3 "Between open to 80%" 4 "Reserved" 5 "Reserved" 6 "Reserved" 7 "Signal Invalid" ;
VAL_ 654 Window_Warning 0 "Not active" 1 "Active" 2 "Reserved" 3 "Signal Invalid" ;
VAL_ 654 Wndow_PosRL 0 "Closed (top)" 1 "Open (bottom)" 2 "Between 80% to closed" 3 "Between open to 80%" 4 "Reserved" 5 "Reserved" 6 "Reserved" 7 "Signal Invalid" ;
VAL_ 654 Window_PosFR 0 "Closed (top)" 1 "Open (bottom)" 2 "Between 80% to closed" 3 "Between open to 80%" 4 "Reserved" 5 "Reserved" 6 "Reserved" 7 "Signal Invalid" ;
VAL_ 654 Global_close 0 "Deactivated" 1 "Activated" 2 "Reserved" 3 "Signal Invalid" ;
VAL_ 654 Global_open 0 "Deactivated" 1 "Activated" 2 "Reserved" 3 "Signal Invalid" ;
VAL_ 654 Window_PosRR 0 "Closed (top)" 1 "Open (bottom)" 2 "Between 80% to closed" 3 "Between open to 80%" 4 "Reserved" 5 "Reserved" 6 "Reserved" 7 "Signal Invalid" ;
VAL_ 657 NDoorRRVehicleLocked 0 "Default (Locked)" 1 "Reserved" 2 "Unlocked (Inactive)" 3 "Locked (Full Decouple)" ;
VAL_ 657 NDoorRRVehicleMoving 0 "default (in motion)" 2 "static (inactive)" 3 "in motion (decouple external)" ;
VAL_ 657 NDoorRROpenInvRequested 0 "default (release inactive)" 2 "open (active release request)" 3 "close (release inactive)" ;
VAL_ 657 NDoorRROpenRequested 0 "close (release inactive)" 1 " open (release request active)" 2 "Reserved" 3 "default (release inactive)" ;
VAL_ 657 NDoorRRChildLocked 0 "default (locked)" 1 "Reserved" 2 " unlocked (inactive)" 3 " locked (full decouple)" ;
VAL_ 657 NDoorRRVehicleCrash 0 "default (locked)" 2 "Not trigger (inactive)" 3 "Trigger (full decouple)" ;
VAL_ 657 NDoorRRCloseInvRequested 0 "Default (Cinch Latching Inactive)" 1 "Reserved" 2 "Open (Active Cinch Latching Request)" 3 "Close (Cinch Latching Inactive)" ;
VAL_ 657 NDoorRRCloseRequested 0 "Close (Cinch latching Inactive)" 1 "Open (Cinch latching request active)" 2 "Reserved" 3 "Default (Cinch latching inactive)" ;
VAL_ 673 DrvSeatMsgStrLvl 0 "OFF" 1 "Initial value" 2 "Level 1(Weak)" 3 "Level 2(General)" 4 "Level 3(Strong)" 5 "Not used" 6 "Not used" 7 "Not used" ;
VAL_ 673 PassSeatMsgStrLvl 0 "OFF" 1 "Intial value" 2 "Level 1 (Weak)" 3 "Level 2 (General)" 4 "Level 3 (Strong)" 5 "Not used" 6 "Not used" 7 "Not used" ;
VAL_ 673 RearDrvSeatMsgStrLvl 0 "Invalid" 1 "Initial value" 2 "Level 1 (Weak)" 3 "Level 2 (General)" 4 "Level 3 (Strong)" 5 "Not used" 6 "Not used" 7 "Not used" ;
VAL_ 673 RearPassSeatMsgStrLvl 0 "OFF" 1 "Initial value" 2 "Level 1(Weak)" 3 "Level 2(General)" 4 "Level 3(Strong)" 5 "Not used" 6 "Not used" 7 "Not used" ;
VAL_ 673 DrvSeatMsgMode 0 "OFF" 1 "Wave Mode" 2 "Cat Paw Mode" 3 "Cross Mode" 4 "Relieve Mode" 5 "Jump Mode" 6 "Invalid" 7 "Not used" ;
VAL_ 673 PassSeatMsgMode 0 "OFF" 1 "Wave Mode" 2 "Cat Paw Mode" 3 "Cross Mode" 4 "Relieve Mode" 5 "Jump Mode" 6 "Invalid" 7 "Not used" ;
VAL_ 673 RearDrvSeatMsgMode 0 "OFF" 1 "Wave Mode" 2 "Cat Paw Mode" 3 "Cross Mode" 4 "Relieve Mode" 5 "Jump Mode" 6 "Invalid" 7 "Not used" ;
VAL_ 673 RearPassSeatMsgMode 0 "OFF" 1 "Wave mode" 2 "Cat Paw Mode" 3 "Cross Mode" 4 "Relieve Mode" 5 "Jump Mode" 6 "invalid" 7 "Not used" ;
VAL_ 674 DrvSeatMsgModeStat 0 "OFF" 1 "Wave Mode" 2 "Cat Paw Mode" 3 "Cross Mode" 4 "Relieve Mode" 5 "Jump Mode" 6 "Invalid" 7 "Not used" ;
VAL_ 674 PassSeatMsgModeStat 0 "OFF" 1 "Wave Mode" 2 "Cat Paw Mode" 3 "Cross Mode" 4 "Relieve Mode" 5 "Jump Mode" 6 "Invalid" 7 "Not used" ;
VAL_ 674 RearDrvSeatMsgModeStat 0 "OFF" 1 "Wave mode" 2 "Cat Paw Mode" 3 "Cross Mode" 4 "Relieve Mode" 5 "Jump Mode" 6 "invalid" 7 "Not used" ;
VAL_ 674 RearPassSeatMsgModeStat 0 "OFF" 1 "Wave mode" 2 "Cat Paw Mode" 3 "Cross Mode" 4 "Relieve Mode" 5 "Jump Mode" 6 "invalid" 7 "Not used" ;
VAL_ 674 LSSM_ALINResErr 0 "No Error" 1 "Error" ;
VAL_ 674 LSSM_APumpFail 0 "Invalid" 1 "No Error" 2 "Error" 3 "Reserved" ;
VAL_ 674 DrvSeatMsgStrLvlStat 0 "OFF" 1 "Initial value" 2 "Level 1(Weak)" 3 "Level 2(General)" 4 "Level 3(Strong)" 5 "Not used" 6 "Not used" 7 "Not used" ;
VAL_ 674 LSSM_BLINResErr 0 "No Error" 1 "Error" ;
VAL_ 674 LSSM_BPumpFail 0 "Invalid" 1 "No Error" 2 "Error" 3 "Reserved" ;
VAL_ 674 PassSeatMsgStrLvlStat 0 "Invalid" 1 "Initial value" 2 "Level 1 (Weak)" 3 "Level 2 (General)" 4 "Level 3 (Strong)" 5 "Not used" 6 "Not used" 7 "Not used" ;
VAL_ 674 LSSM_CLINResErr 0 "No Error" 1 "Error" ;
VAL_ 674 LSSM_CPumpFail 0 "Invalid" 1 "No Error" 2 "Error" 3 "Reserved" ;
VAL_ 674 RearDrvSeatMsgStrLvlStat 0 "Invalid" 1 "Initial value" 2 "Level 1 (Weak)" 3 "Level 2 (General)" 4 "Level 3 (Strong)" 5 "Not used" 6 "Not used" 7 "Not used" ;
VAL_ 674 LSSM_DLINResErr 0 "No Error" 1 "Error" ;
VAL_ 674 LSSM_DPumpFail 0 "Invalid" 1 "No Error" 2 "Error" 3 "Reserved" ;
VAL_ 674 RearPassSeatMsgStrLvlStat 0 "OFF" 1 "Initial value" 2 "Level 1(Weak)" 3 "Level 2(General)" 4 "Level 3(Strong)" 5 "Not used" 6 "Not used" 7 "Not used" ;
VAL_ 676 ECU_ID_WUPREG 255 "Signal invalid" ;
VAL_ 676 ID_FN_INQY 161 "Operation button Entertainment" 246 "Control exterior mirror" 426 "Effect ErgoCommander" 482 "Safe VIN" 525 "Position steering column" 550 "Rain sensor wiper speed" 570 "Status key" 594 "Wiper status" 615 "Operation pushbutton operating menu" 638 "Status soft top convertible" 742 "Status Climate Air distribution drivere" 746 "Status Climate Air distribution passenger" 748 "Status Climate " 750 "Status climate additional programs" 752 "Status Climate Stand functions" 759 "Unit" 760 "Time date" 768 "Status RSE" 783 "Status Service Call TeleX" 787 "Status Service Call Teleservice" 806 "Wirkungsgrad Information Data" 818 "Consumption information" 822 "Display checkcontrol message" 826 "Status Monitor Front" 828 "Status Monitor Rear 1" 830 "Status Monitor Rear 2" 833 "Status card data" 841 "Raw value fuel tank" 860 "Status Bordcomputer" 864 "Daten Bordcomputer 1" 896 "VIN" 897 "Electronic engine oil stick" 904 "vehicle type" 917 "Coding Powermanagement" 921 "Status M-Drive" 937 "Status ECM CKM" 939 "Status Shiftlights CKM" 950 "Position window regulator driver" 951 "Position window regulator driver rear" 952 "Position window regulator passenger" 953 "Position window regulator passenger rear" 954 "Position sliding roof" 956 "Position window lift sec" 959 "Position window lift tailgate" 960 "Configuration FAS" 961 "Configuration BFS" 962 "Configuration FASH" 963 "Configuration BFSH" 964 "Status EDCK CKM" 976 "Status lane departure warning system" 981 "Status cental lock" 983 "Status DWA CKM" 985 "Status RLS CKM" 987 "Status Memoryposition CKM" 989 "Status Light CKM" 991 "Status Climate CKM" 993 "Status ALC CKM" 995 "Status tailgateCKM" 1003 "Limits swing left" 1004 "Limits swing right" 1009 "Status light Extended  CKM" 1013 "Status of cargo compartment cover CKM" 1050 "Status Configuration IC 4" 1060 "Status Configuration IC" 1063 "Configuration DSC" 1070 "Status M-Drive 2" 1076 "Configuration EPS" 1077 "Measure engine oil" 1087 "Identification number Sensorcluster" 65535 "Signal invalid" ;
VAL_ 676 ID_FN_RQ_BUS 1 "Entertainment function" 2 "Remote Services" 3 "Residual heat function / burnout" 4 "Auxiliary heating/parking ventilation" 5 "Extension N-Holding Phase" 6 "Operation parking brake" 7 "Follow-up / connection RSE" 8 "Remote horn" 25 "Switch on / extension clamp" 43 "Alarm" 44 "EMF-button" 45 "roll monitoring" 46 "Requirement outside lighting" 47 "transhipment function" 51 "KL15Wup-Signal" 53 "Coolant temperature" 54 "IC display" 257 "switch on preventer" 258 "Wacke up " 259 "Switch OFF KL30F Stand time" 260 "Switch OFF KL30F CarSharing" 272 "OBD-Diagnostic" 273 "Exstension time water pump" 275 "Exstension time E-fan" 276 "Exstension time water pump additional Waterpumpe" 277 "Exstension time water pump hyb" 278 "Standl ventilation" 280 "Third-party charge detection hybrid / charging" 281 "Battery monitor  TSR" 288 "Leveling" 289 "Exstension time ventilation cooling" 304 "Trailer connection AAG" 305 "Req IK" 306 "Req IK OSFG" 513 "Domainmaster  ICE" 514 "Domainmaster elec motor" 515 "Domainmaster entertainment" 516 "Domainmaster body" 517 "Domainmaster Chasis" 769 "BDC Internal 30B Request inlight" 770 "BDC Internal 30B Request outlight" 771 "BDC Internal 30B Request FA-CAN " 772 "BDC Internal 30B Request Telesta" 773 "BDC Internal 30B Request Battery" 774 "CO2 Sensor" 65535 "Signal invalid" ;
VAL_ 676 NO_CC_MESS_STD 0 "No Error" 1 "Error(CurveBehavrestricted)" 2 "Error (Limited driving comfort)" ;
VAL_ 676 WACA 0 "ECU reset" 1 "Car alarm" 2 "Residual heat" 3 "CO2-recognition" 4 "CD/DVD Eject/CD/DVD insert" 5 "OFF switch light" 6 "Mirror" 7 "Remote Services" 8 "Emergency Call" 9 "CAS-Bus, button tailgate" 10 "CID-flap button" 11 "Smart Opener" 12 "Start charging" 14 "Switch for hitch" 16 "Door contact front driver" 17 "Door contact front passenger" 18 "Door contact front driver rear" 19 "Door contact front driver rear" 20 "Button driver door CA" 21 "Button passenger door CA" 22 "Button opener tailgate inner" 23 "Button opener tailgate" 24 "Button opener tailgate window" 25 "Tailgate contact" 26 "Input tailgate window" 27 "Bonnet" 28 "Unlock door lock / comfort opening" 29 "Lock door lock / comfort lock" 30 "Short circuit terminal 30 B" 32 "Start Stop button A" 33 "Start Stop button B" 34 "Hallsensor Eject" 35 "Center lock unlock" 36 "Park Automatic" 37 "Light swich ON" 38 "Hazard switch" 39 "Steering column switch to flash" 40 "Lenkstocktaster towards" 41 "Lenkstocktaster towards light" 42 "interior switch" 43 "Gear switch" 44 "EMF- Button" 45 "Entertainmen" 46 "Steering colunm adjustment switch" 47 "Regulation air spring" 48 "RKE" 49 "Wakeup-Signal TCU" 50 "Hotel switch" 51 "IBS" 52 "Parking heater / ventilate / climate" 53 "Coolant query by IC" 54 "Klemme 15 Wakeu line" 55 "Button Driver's door rear release" 56 "Button passenger door rear release" 57 "Button Driver's door" 58 "Button passenger door release" 59 "Button Driver's door rear release" 60 "Button passenger door rear release" 61 "Brake light switch" 62 "Clutch switch" 63 "Invalid wake-up reason, wake-up reason" 64 "Fog light" 65 "Rear fog light" 66 "Sarah- button" 67 "FES-button" 68 "PDC-button" 69 "Side-View-button" 70 "Rear spoiler-Taster" 71 "VDP-" 72 "MSA-button" 73 "Button audio volume steering wheel" 74 "Button special function" 75 "Button knurled steering wheel" 76 "Push-button telephone steering wheel" 77 "Push-button PTT steering wheel" 78 "Push-button seat heating driver" 79 "Push-button seat heating passenger" 80 "Push-button seat heating driver rear" 81 "Push-button seat heating passenger rear" 82 "Seat memory driver" 83 "Switch block door China long" 84 "Steering switch light" 85 "Door control unit" 88 "Car Sharing Modul" 89 "seat switch" 90 "AC control" 91 "PWF state change" 93 "Park light switch" 96 "Seat memory driver rear" 97 "Seat memory passenger" 98 "Seat memory pasenger rear" 99 "Nox-Diagnosis" 102 "Closing aid" 112 "Wake up" 255 "Signal invalid" ;
VAL_ 676 ST_CC_MESS_STD 0 "No Error" 1 "Error" ;
VAL_ 676 TRANF_CC_MESS_STD 0 "No Error" 1 "Error" ;
VAL_ 676 ST_IDC_CCLK_CC_MESS_STD 0 "No Error" 1 "Error" ;
VAL_ 714 MHU_STAT_CoolantLevelStatus 0 "Normal condition" 1 "Low level condition" 2 "Reserved" 3 "Signal Invalid" ;
VAL_ 753 MHU_STAT_AirbagWarnLamp 0 "Lamp off" 1 "Lamp on" 2 "Lamp failure" 3 "Signal invalid" ;
VAL_ 760 DISP_DATE_WDAY 1 "Monday" 2 "Tuesday" 3 "Wednesday" 4 "Thursday" 5 "Friday" 6 "Saturday" 7 "Sunday" 15 "Signal invalid" ;
VAL_ 760 ST_DISP_CTI_DATE 0 "data not valid" 1 "data valid" 3 "UTC" 5 "winter time" 6 "Manually set time" 7 "summer time" 15 "signal invalid" ;
VAL_ 768 CCU_STAT_SyncClimateZone 0 "OFF" 1 "ON" 2 "Reserved" 3 "Signal invalid" ;
VAL_ 768 CCU_STAT_Auto 0 "OFF" 1 "ON" 2 "Reserved" 3 "Signal invalid" ;
VAL_ 768 CCU_STAT_Aircondition 0 "OFF" 1 "ON" 2 "Reserved" 3 "Signal invalid" ;
VAL_ 768 CCU_STAT_IonButton 0 "OFF" 1 "ON" 2 "Reserved" 3 "Signal invalid" ;
VAL_ 768 CCU_STAT_MaxAc 0 "OFF" 1 "ON" 2 "Reserved" 3 "Signal invalid" ;
VAL_ 768 CCU_STAT_OnOff 0 "OFF" 1 "ON" 2 "Reserved" 3 "Signal invalid" ;
VAL_ 768 CCU_STAT_FanSpeed 0 "OFF" 1 "Level 1" 2 "Level 2" 3 "Level 3" 4 "Level 4" 5 "Level 5" 6 "Level 6" 7 "Reserved" 8 "Reserved" 9 "Reserved" 10 "Reserved" 11 "Reserved" 12 "Reserved" 13 "Reserved" 14 "Reserved" 15 "Signal invalid" ;
VAL_ 768 CCU_STAT_RecircFlap 0 "Inside" 1 "Outside" 2 "Auto" 3 "Signal invalid" ;
VAL_ 768 CCU_STAT_FlapPos 0 "OFF" 1 "Vent" 2 "Vent/Foot" 3 "Foot" 4 "Foot/Defrost" 5 "Defrost" 6 "Default" 7 "Signal invalid" ;
VAL_ 768 CCU_STAT_Defrost 0 "OFF" 1 "ON" 2 "Reserved" 3 "Signal invalid" ;
VAL_ 768 CCU_STAT_PTC_Heater 0 "OFF" 1 "Stage 1" 2 "Stage 2" 3 "Stage 3" 4 "Reserved" 5 "Reserved" 6 "Reserved" 7 "Signal invalid" ;
VAL_ 773 CcuHtrOnOffSts 0 "HV PTC off / HV_PTC_OFF" 1 "HV PTC on / HV_PTC_ON" 2 "HV PTC degraded / HV_PTC_DEG" 3 "HV PTC stopped / HV_PTC_STOP" 4 "HV PTC shutdown / HV_PTC_SHUTDOWN" 5 "HV PTC shorted / HV_PTC_SHORTED" 6 "HV PTC reset not possible / HV_PTC_NO_RESET" 7 "SNA" ;
VAL_ 773 EcompOnOffSts 0 "Off" 1 "On" 2 "Reserved" 3 "Signal invalid" ;
VAL_ 774 CCU_EcompOnOffRequest 0 "Off" 1 "On" 2 "Reserved" 3 "Signal invalid" ;
VAL_ 774 CCU_HtrOnOffRequest 0 "Off" 1 "On" 2 "Reserved" 3 "Signal invalid" ;
VAL_ 775 OUT_Alert_TO_BCM 0 "Init" 1 "Warning level 1" 2 "Warning level 2" 3 "Warning level 3" 4 "Deactivate Warning" 5 "Invalid Value" ;
VAL_ 775 CPD_State_information 0 "Enable" 1 "Disable" 2 "Child Mode" 3 "Pet Mode" 4 "Reserved" 5 "Reserved" 6 "Reserved" 7 "Reserved" ;
VAL_ 784 CCUR_STAT_IonButton 0 "OFF" 1 "ON" 2 "Reserved" 3 "Signal invalid" ;
VAL_ 784 CCUR_STAT_Defrost 0 "OFF" 1 "ON" 2 "Reserved" 3 "Signal invalid" ;
VAL_ 784 CCUR_STAT_Auto 0 "OFF" 1 "ON" 2 "Reserved" 3 "Signal invalid" ;
VAL_ 784 CCUR_STAT_Aircondition 0 "OFF" 1 "ON" 2 "Reserved" 3 "Signal invalid" ;
VAL_ 784 CCUR_STAT_FlapPos 0 "OFF" 1 "Vent" 2 "Vent/Foot" 3 "Foot" 4 "Foot/Defrost" 5 "Defrost" 6 "Default" 7 "Signal invalid" ;
VAL_ 784 CCUR_STAT_FanSpeed 0 "OFF" 1 "Level 1" 2 "Level 2" 3 "Level 3" 4 "Level 4" 5 "Level 5" 6 "Level 6" 7 "Reserved" 8 "Reserved" 9 "Reserved" 10 "Reserved" 11 "Reserved" 12 "Reserved" 13 "Reserved" 14 "Reserved" 15 "Signal invalid" ;
VAL_ 784 CCUR_STAT_PTC_Heater 0 "OFF" 1 "Stage 1" 2 "Stage 2" 3 "Stage 3" 4 "Reserved" 5 "Reserved" 6 "Reserved" 7 "Signal invalid" ;
VAL_ 784 CCUR_STAT_OnOff 0 "OFF" 1 "ON" 2 "Reserved" 3 "Signal invalid" ;
VAL_ 784 CCUR_STAT_MaxAc 0 "OFF" 1 "ON" 2 "Reserved" 3 "Signal invalid" ;
VAL_ 784 CCUR_STAT_SyncClimateZone 0 "OFF" 1 "ON" 2 "Reserved" 3 "Signal invalid" ;
VAL_ 784 CCUR_STAT_RecircFlap 0 "Inside" 1 "Outside" 2 "Auto" 3 "Signal invalid" ;
VAL_ 806 POD_statusDCDC 0 "DCDC_OFF" 1 "DCDC_STANDBY" 2 "DCDC_ON" 3 "DCDC_RESERVED" 4 "DCDC_DEGRADED" 5 "DCDC_FAULT_SHUTDOWN" 6 "DCDC_EMERGENCY_SHUTDOWN" 7 "DCDC_STS_SNA";
VAL_ 812 QU_HGLV_RLH_EHC 1 "Signal value" 3 "Signal quality monitoring" 6 "Signal value not valid" 8 "Initialisierung" 21 "Signal invalid" ;
VAL_ 812 QU_HGLV_RRH_EHC 1 "Signal value valid" 3 "Signal quality monitoring" 6 "Signal value not valid" 8 "Init" 21 "Signal invalid" ;
VAL_ 816 ST_FLLV_FUTA_SPAR 0 "No active" 1 "Active" 2 "Reserved" 3 "Signal invalid" ;
VAL_ 880 SBR_STAT_Chime 0 "Off" 1 "Durable" 2 "Blinking 3Hz" 3 "SNA" ;
VAL_ 880 SBR_STAT_Telltale 0 "No chime" 1 "1 Hz" 2 "3 Hz" 3 "SNA" ;
VAL_ 880 SBR_STAT_Active 0 "Not active" 1 "Active" ;
VAL_ 897 ACM_Seat_Occupancy_Passenger 0 "Seat_Not_Occupied" 1 "Seat Occupied" 2 "Not_Available" 3 "Failure" ;
VAL_ 897 ACM_Seat_Occupancy_2nd_Row_Dri 0 "Seat_Not_Occupied" 1 "Seat Occupied" 2 "Not_Available" 3 "Failure" ;
VAL_ 897 ACM_Seat_Occupancy_2nd_Row_Pas 0 "Seat_Not_Occupied" 1 "Seat Occupied" 2 "Not_Available" 3 "Failure" ;
VAL_ 897 ACM_Seat_Occupancy_2nd_Row_Mid 0 "Seat_Not_Occupied" 1 "Seat Occupied" 2 "Not_Available" 3 "Failure" ;
VAL_ 897 ACM_Seat_Belt_Status_Passenger 0 "Not_buckled" 1 "Buckled" 2 "Not_Available" 3 "Failure" ;
VAL_ 897 ACM_Seat_Belt_Status_Driver 0 "Not_buckled" 1 "Buckled" 2 "Not_Available" 3 "Failure" ;
VAL_ 897 ACM_Seat_Belt_Status_2nd_Row_Dri 0 "Not_buckled" 1 "Buckled" 2 "Not_Available" 3 "Failure" ;
VAL_ 897 ACM_Seat_Belt_Status_2nd_Row_Mid 0 "Not_buckled" 1 "Buckled" 2 "Not_Available" 3 "Failure" ;
VAL_ 897 ACM_Seat_Belt_Status_2nd_Row_Pas 0 "Not_buckled" 1 "Buckled" 2 "Not_Available" 3 "Failure" ;
VAL_ 905 VCU_IMMO_Sts 0 "init" 1 "pass" 2 "failed" ;
VAL_ 924 ADAS_AHB_LBPos 0 "Off or low beam" 1 "high beam" 2 "Reserved" 3 "Reserved" 4 "Reserved" 5 "Reserved" 6 "Reserved" 7 "Reserved" ;
VAL_ 924 ADAS_AHB_RBPos 0 "Off or low beam" 1 "high beam" 2 "Reserved" 3 "Reserved" 4 "Reserved" 5 "Reserved" 6 "Reserved" 7 "Reserved" ;
VAL_ 925 BCM_AHB_Override 0 "not used" 1 "Automatic High Beam request" 2 "AHB  Inhibit by Driver" 3 "invalid" ;
VAL_ 925 BCM_ADAS_AHB_RBPos_feed 0 "Off or low beam" 1 "high beam" 2 "Reserved" 3 "Reserved" 4 "Reserved" 5 "Reserved" 6 "Reserved" 7 "Reserved" ;
VAL_ 925 BCM_ADAS_AHB_LBPos_feed 0 "Off or low beam" 1 "high beam" 2 "Reserved" 3 "Reserved" 4 "Reserved" 5 "Reserved" 6 "Reserved" 7 "Reserved" ;
VAL_ 926 ADAS_DOW_LockReqRight 0 "No Request" 1 "Lock" ;
VAL_ 926 ADAS_DOW_LockReqLeft 0 "No Request" 1 "Lock" ;
VAL_ 926 ADAS_AmbLightLeft 0 "No request" 1 "Level 1" 2 "Level 2" 3 "Reserved" ;
VAL_ 926 ADAS_AmbLightRight 0 "No request" 1 "Level 1" 2 "Level 2" 3 "Reserved" ;
VAL_ 1015 MFS_VoiceRecognitionOn_Off 0 "Button not Pressed" 1 "Short Press" 2 "Long Press" 3 "Reserved" 4 "Signal invalid" ;
VAL_ 1015 MFS_ISAControl 0 "Button not Pressed" 1 "Short Press" 2 "Long Press" 3 "Reserved" ;
VAL_ 1015 MFS_CruiseSpeedIncrease 0 "Button not Pressed" 1 "Short Press" 2 "Long Press" 3 "Reserved" 4 "Signal invalid" ;
VAL_ 1015 MFS_TelephoneCall_EndCall 0 "Button not Pressed" 1 "Short Press" 2 "Long Press" 3 "Reserved" 4 "Signal invalid" ;
VAL_ 1015 MFS_LKAControl 0 "Button not Pressed" 1 "Short Press" 2 "Long Press" 3 "Reserved" ;
VAL_ 1015 MFS_CruiseGapIncrease 0 "Button not Pressed" 1 "Short Press" 2 "Long Press" 3 "Reserved" 4 "Signal invalid" ;
VAL_ 1015 MFS_CruiseOn_Off 0 "Button not Pressed" 1 "Short Press" 2 "Long Press" 3 "Reserved" 4 "Signal invalid" ;
VAL_ 1015 MFS_CruiseGapDecrease 0 "Button not Pressed" 1 "Short Press" 2 "Long Press" 3 "Reserved" 4 "Signal invalid" ;
VAL_ 1015 MFS_CAN_RESControl 0 "Button not Pressed" 1 "Short Press" 2 "Long Press" 3 "Reserved" ;
VAL_ 1015 MFS_CruiseSpeedDecrease 0 "Button not Pressed" 1 "Short Press" 2 "Long Press" 3 "Reserved" 4 "Signal invalid" ;
VAL_ 1015 MFS_M2Control 0 "Button not Pressed" 1 "Short Press" 2 "Long Press" 3 "Reserved" ;
VAL_ 1015 MFS_SourseControl 0 "Button not Pressed" 1 "Short Press" 2 "Long Press" 3 "Reserved" 4 "Signal invalid" ;
VAL_ 1015 MFS_UpControl 0 "Button not Pressed" 1 "Short Press" 2 "Long Press" 3 "Reserved" 4 "Signal invalid" ;
VAL_ 1015 MFS_DownControl 0 "Button not Pressed" 1 "Short Press" 2 "Long Press" 3 "Reserved" 4 "Signal invalid" ;
VAL_ 1015 MFS_LeftControl 0 "Button not Pressed" 1 "Short Press" 2 "Long Press" 3 "Reserved" 4 "Signal invalid" ;
VAL_ 1015 MFS_Failure 0 "No Error" 1 "Error" ;
VAL_ 1015 MFS_RightControl 0 "Button not Pressed" 1 "Short Press" 2 "Long Press" 3 "Reserved" 4 "Signal invalid" ;
VAL_ 1015 MFS_OK_Control 0 "Button not Pressed" 1 "Short Press" 2 "Long Press" 3 "Reserved" 4 "Signal invalid" ;
VAL_ 1025 MHU_SET_SunroofGlassLevel 0 "Closed" 127 "Vent" 150 "Stop" 255 "No Request" ;
VAL_ 1025 MHU_SET_BonnetState 0 "Not pressed" 1 "Pressed" 2 "Reserved" 3 "Signal invalid" ;
VAL_ 1025 MHU_SET_TrunkState 0 "Not pressed" 1 "Pressed" 2 "Reserved" 3 "Signal invalid" ;
VAL_ 1025 MHU_SET_SunroofShaderLevel 0 "Closed" 150 "Stop" 255 "No Request" ;
VAL_ 1025 MHU_SET_DoorSpeedLock 0 "OFF" 1 "5KMH" 2 "10KMH" 3 "15KMH" 4 "20KMH" 5 "25KMH" 6 "Signal invalid" ;
VAL_ 1025 MHU_SET_WelcomeTriggerCondition 0 "Vehicle unLock" 1 "Driver walk toward" 2 "OFF" 3 "Signal invalid" ;
VAL_ 1025 MHU_SET_AutoSunroof 0 "OFF" 1 "Glass Only" 2 "Glass & Shade" 3 "Signal invalid" ;
VAL_ 1025 MHU_SET_RemoteDoorUnlock 0 "Driver door" 1 "All doors" 2 "Reserved" 3 "Signal invalid" ;
VAL_ 1025 MHU_SET_RemoteLockFeedback 0 "Light" 1 "Horn" 2 "Light/Horn" 3 "OFF" 4 "Signal Invalid" ;
VAL_ 1025 MHU_SET_FootkickSensor 0 "OFF" 1 "ON" 2 "Reserved" 3 "Signal invalid" ;
VAL_ 1025 MHU_SET_AutoUnlockDoor 0 "OFF" 1 "On" 2 "Reserved" 3 "Signal Invalid" ;
VAL_ 1025 MHU_SET_RemoteUnlockFeedback 0 "Blinking" 1 "Dimming" 2 "Low Beam ON" 3 "OFF" 4 "Signal Invalid" ;
VAL_ 1025 MHU_SET_Childlock 0 "OFF" 1 "ON" 2 "Reserved" 3 "Signal invalid" ;
VAL_ 1025 MHU_SET_SunroofInitialize 0 "Inactive - Default" 1 "Initialisation" 2 "Manual Open Sunroof" 3 "Manual Close Sunroof" 4 "Manual Open Sunshade" 5 "Manuel Close Sunshade" 6 "Reserved" 7 "Signal invalid" ;
VAL_ 1025 WalkawayDoorLock 0 "OFF" 1 "ON";
VAL_ 1026 MHU_SET_DayTimeRunningLight 0 "OFF" 1 "ON" 2 "Reserved" 3 "Signal invalid" ;
VAL_ 1026 MHU_SET_RearFogLight 0 "OFF" 1 "ON" 2 "Reserved" 3 "Signal invalid" ;
VAL_ 1026 MHU_SET_FrontFogLight 0 "OFF" 1 "ON" 2 "Reserved" 3 "Signal invalid" ;
VAL_ 1026 MHU_SET_WelcomeDimmingHeadlight 0 "OFF" 1 "ON" 2 "Reserved" 3 "Signal invalid" ;
VAL_ 1026 MHU_SET_FootwellLightMode 0 "OFF" 1 "ON" 2 "AUTO" 3 "Signal invalid" ;
VAL_ 1026 MHU_SET_ExteriorLight 0 "OFF" 1 "Parking" 2 "ON" 3 "AUTO" 4 "Signal invalid" ;
VAL_ 1026 MHU_SET_TRWarningSignals 0 "Off BCM warning signals" 1 "On BCM warning signals" 2 "Reserved" 3 "Signal Invalid";
VAL_ 1026 MHU_SET_FrontDomeLamp 0 "OFF" 1 "ON" 2 "AUTO" 3 "Signal invalid" ;
VAL_ 1026 MHU_SET_HazardLight 3 "Signal Invalid" 2 "Reserved" 1 "ON" 0 "OFF" ;
VAL_ 1026 MHU_SET_FollowMeHome 0 "OFF" 1 "30 secs" 2 "60 secs" 3 "90 secs" 4 "120 secs" 5 "Signal invalid" ;
VAL_ 1026 MHU_SET_ADB_AHB 0 "OFF" 1 "ON" 2 "Reserved" 3 "Signal Invalid" ;
VAL_ 1026 MHU_SET_WelcomeAnimation 0 "OFF" 1 "Light dance" 2 "Vegas blink" 3 "Pulse and blink" 4 "Reserved" 5 "Signal invalid" ;
VAL_ 1026 MHU_SET_ChargingAnimation 0 "OFF" 1 "ON" 2 "Reserved" 3 "Signal invalid" ;
VAL_ 1026 MHU_SET_Auto_Leveling 0 "OFF" 1 "ON" 2 "Reserved" 3 "Signal Invalid" ;
VAL_ 1027 MHU_VCU_CreepDisable_stt 0 "No request" 1 "Creep Disable request" ;
VAL_ 1027 MHU_BrakeRegenMode 0 "HIGH" 1 "MID" 2 "LOW" 3 "OFF";
VAL_ 1027 MHU_ChargeScheduleSet 0 "disable" 1 "Enable" 2 "No effect" 3 "Invalid" ;
VAL_ 1027 MHU_ChargingRequest 0 "Stop charging" 1 "Start charging" 2 "Pause charging" 3 "No effect" ;
VAL_ 1027 MHU_ChgPort_Open_req 0 "No request" 1 "Requesting" 2 "Reserved" 3 "Signal invalid" ;
VAL_ 1027 MHU_SET_DrivingModeSwitch 0 "NORMAL" 1 "ECO" 2 "SPORT" 3 "Signal invalid" ;
VAL_ 1027 MHU_ValetMode_Activation 0 "Inactive" 1 "Active" 2 "No effect" 255 "Invalid" ;
VAL_ 1028 MHU_SET_MirrorAdjustLeft 0 "OFF" 1 "ON" 2 "Reserved" 3 "Signal invalid" ;
VAL_ 1028 MHU_SET_MirrorAdjustRight 0 "OFF" 1 "ON" 2 "Reserved" 3 "Signal invalid" ;
VAL_ 1028 MHU_SET_MirrorManual 0 "Fold" 1 "Unfold" 2 "Reserved" 3 "Signal invalid" ;
VAL_ 1029 MHU_SET_CCUF_AirCondition 0 "Not pressed" 1 "Pressed" 2 "Reserved" 3 "Signal invalid" ;
VAL_ 1029 MHU_SET_CCUF_AutoAC 0 "Not pressed" 1 "Pressed" 2 "Reserved" 3 "Signal invalid" ;
VAL_ 1029 MHU_SET_CCUF_MaxAc 0 "Not pressed" 1 "Pressed" 2 "Reserved" 3 "Signal invalid" ;
VAL_ 1029 MHU_SET_CCUF_FanSpeed 0 "OFF" 1 "Level1" 2 "Level2" 3 "Level3" 4 "Level4" 5 "Level5" 6 "Level6" 7 "Signal invalid" ;
VAL_ 1029 MHU_SET_CCUF_Recirculation 0 "Inside" 1 "Outside" 2 "Auto" 3 "Signal invalid" ;
VAL_ 1029 MHU_SET_CCUF_Ion 0 "Not pressed" 1 "Pressed" 2 "Reserved" 3 "Signal invalid" ;
VAL_ 1029 MHU_SET_CCUF_FlapPosition 0 "OFF" 1 "Face" 2 "Face and Feet" 3 "Feet" 4 "Feet and Defrost" 5 "Defrost" 6 "Default" 7 "Signal Invalid" ;
VAL_ 1029 MHU_SET_CCUF_SyncClimateZone 0 "Not pressed" 1 "Pressed" 2 "Reserved" 3 "Signal invalid" ;
VAL_ 1029 MHU_SET_CCUF_TempDriver 32 "16" 33 "16.5" 34 "17" 35 "17.5" 36 "18" 37 "18.5" 38 "19" 39 "19.5" 40 "20" 41 "20.5" 42 "21" 43 "21.5" 44 "22" 45 "22.5" 46 "23" 47 "23.5" 48 "24" 49 "24.5" 50 "25" 51 "25.5" 52 "26" 53 "26.5" 54 "27" 55 "27.5" 56 "28" 57 "28.5" 58 "29" 59 "29.5" 60 "30" 61 "30.5" 62 "31" 63 "31.5" 64 "32" 255 "Invalid Value" ;
VAL_ 1029 MHU_SET_CCUF_TempPassenger 32 "16" 33 "16.5" 34 "17" 35 "17.5" 36 "18" 37 "18.5" 38 "19" 39 "19.5" 40 "20" 41 "20.5" 42 "21" 43 "21.5" 44 "22" 45 "22.5" 46 "23" 47 "23.5" 48 "24" 49 "24.5" 50 "25" 51 "25.5" 52 "26" 53 "26.5" 54 "27" 55 "27.5" 56 "28" 57 "28.5" 58 "29" 59 "29.5" 60 "30" 61 "30.5" 62 "31" 63 "31.5" 64 "32" 255 "Invalid Value" ;
VAL_ 1029 MHU_SET_CCUF_FrontDefrost 0 "Not pressed" 1 "Pressed" 2 "Reserved" 3 "Signal invalid" ;
VAL_ 1030 MHU_SET_SeatHeatingFrontL 0 "OFF" 1 "Level1" 2 "Level2" 3 "Level3" 4 "Signal invalid" ;
VAL_ 1030 MHU_SET_SeatHeatingFrontR 0 "OFF" 1 "Level1" 2 "Level2" 3 "Level3" 4 "Signal invalid" ;
VAL_ 1030 MHU_SET_SeatHeatingReartL 0 "OFF" 1 "Level1" 2 "Level2" 3 "Level3" 4 "Signal invalid" ;
VAL_ 1030 MHU_SET_SeatHeatingRearR 0 "OFF" 1 "Level1" 2 "Level2" 3 "Level3" 4 "Signal invalid" ;
VAL_ 1030 MHU_SET_SeatCoolingFrontL 0 "OFF" 1 "Level1" 2 "Level2" 3 "Level3" 4 "Signal invalid" ;
VAL_ 1030 MHU_SET_SeatCoolingFrontR 0 "OFF" 1 "Level1" 2 "Level2" 3 "Level3" 4 "Signal invalid" ;
VAL_ 1030 MHU_SET_SeatCoolingRearL 0 "OFF" 1 "Level1" 2 "Level2" 3 "Level3" 4 "Signal invalid" ;
VAL_ 1030 MHU_SET_SeatCoolingRearR 0 "OFF" 1 "Level1" 2 "Level2" 3 "Level3" 4 "Signal invalid" ;
VAL_ 1032 MHU_SET_MirrorAuto 0 "OFF" 1 "ON" 2 "Reserved" 3 "Signal invalid" ;
VAL_ 1032 MHU_SET_MirrorAutoUnfold 0 "Vehicle Unlock" 1 "Driver walk toward" 2 "OFF" 3 "Signal invalid" ;
VAL_ 1032 MHU_SET_WLC 0 "OFF" 1 "ON" 2 "Reserved" 3 "Signal invalid" ;
VAL_ 1032 MHU_SET_AutoRearWiper 0 "OFF" 1 "ON" 2 "Reserved" 3 "Signal invalid" ;
VAL_ 1032 MHU_SET_RearHeatedWindow 0 "Not pressed" 1 "Pressed" 2 "Reserved" 3 "Signal invalid" ;
VAL_ 1032 MHU_TPMSReset 0 "Noreset" 1 "Reset" 2 "Reserved" 3 "Signal invalid" ;
VAL_ 1032 MHU_SET_MirrorDefaultSetting 0 "Not pressed" 1 "Pressed" 2 "Reserved" 3 "Signal invalid" ;
VAL_ 1032 MHU_SET_MirrorReverseLink 0 "OFF" 1 "Right Mirror" 2 "Left Mirror" 3 "Both Mirror";
VAL_ 1032 MHU_SET_AntiTheftMode 0 "OFF" 1 "Light Only" 2 "Horn Only" 3 "Light and Horn" ;
VAL_ 1032 MHU_SET_WLCReminder 0 "OFF" 1 "ON" 2 "Reserved" 3 "Signal invalid" ;
VAL_ 1032 MHU_SET_ClimateKeepOn 0 "OFF" 1 "PET" 2 "CAMP" 3 "REMOTE CONTROL" ;
VAL_ 1032 MHU_SET_WLC2 0 "OFF" 1 "ON" 2 "Reserved" 3 "Signal invalid" ;
VAL_ 1032 MHU_SET_WLC2Reminder 0 "OFF" 1 "ON" 2 "Reserved" 3 "Signal invalid" ;
VAL_ 1032 MHU_IntrusionAlertStatus 0 "OFF" 1 "ON" 2 "Stop Alarm" 3 "Signal invalid" ;
VAL_ 1036 MHU_DrvSeat_Control_Status 0 "Idle" 1 "Request seat moving" 2 "Reserved" 3 "Invalid value" ;
VAL_ 1044 ERR_ST_HOD 0 "NO_ERROR" 1 "HOD_EEPROM_ERROR" 2 "HOD_ROM_ERROR" 3 "HOD_WATCHDOG_ERROR" 4 "HOD_CPU_ERROR" 5 "HOD_GUARD_INTERRUPTION_ERROR" 6 "HOD_SENSE_INTERRUPTION_ERROR" 7 "HOD_CPU_DEFECT_OR_MAT_SHORTAGE" 8 "UNDERVOLTAGE_ERROR" 9 "OVERVOLTAGE_ERROR" 10 "HOD_CODING_ERROR" 11 "HOD_GENERIC_SYSTEM_ERROR" 15 "Not Available" ;
VAL_ 1044 RsErr_HOD 0 "No_error" 1 "error" ;
VAL_ 1044 HOD_status 0 "Init" 1 "Hands OFF" 2 "Hands ON" 3 "Energie_Save_Mode" 4 "HOD error" 5 "Invalid value" 6 "Reserved" 7 "Reserved" 8 "Reserved" 9 "Reserved" 10 "Reserved" 11 "Reserved" 12 "Reserved" 13 "Reserved" 14 "Reserved" 15 "Reserved" ;
VAL_ 1046 BCM_STAT_Mirror 0 "Fold" 1 "Unfold" 2 "Reserved" 3 "Signal Invalid" ;
VAL_ 1046 BCM_STAT_MirrorAdjustLeft 0 "OFF" 1 "ON" 2 "Reserved" 3 "Signal invalid" ;
VAL_ 1046 BCM_STAT_MirrorAdjustRight 0 "OFF" 1 "ON" 2 "Reserved" 3 "Signal invalid" ;
VAL_ 1049 SHVU_STAT_SeatHeatingFrontL 0 "OFF" 1 "Level1" 2 "Level2" 3 "Level3" 4 "Signal invalid" ;
VAL_ 1049 SHVU_STAT_SeatHeatingFrontR 0 "OFF" 1 "Level1" 2 "Level2" 3 "Level3" 4 "Signal invalid" ;
VAL_ 1049 SHVU_STAT_SeatCoolingFrontL 0 "OFF" 1 "Level1" 2 "Level2" 3 "Level3" 4 "Signal invalid" ;
VAL_ 1049 SHVU_STAT_SeatCoolingFrontR 0 "OFF" 1 "Level1" 2 "Level2" 3 "Level3" 4 "Signal invalid" ;
VAL_ 1049 SHVU_STAT_FrontSeatVentSts 0 "Normal Operation" 1 "Failure" 2 "Reserved" 3 "Signal invalid" ;
VAL_ 1050 SHVU_STAT_SeatCoolingRearL 0 "OFF" 1 "Level1" 2 "Level2" 3 "Level3" 4 "Signal invalid" ;
VAL_ 1050 SHVU_STAT_SeatCoolingRearR 0 "OFF" 1 "Level1" 2 "Level2" 3 "Level3" 4 "Signal invalid" ;
VAL_ 1050 SHVU_STAT_SeatHeatingReartL 0 "OFF" 1 "Level1" 2 "Level2" 3 "Level3" 4 "Signal invalid" ;
VAL_ 1050 SHVU_STAT_SeatHeatingRearR 0 "OFF" 1 "Level1" 2 "Level2" 3 "Level3" 4 "Signal invalid" ;
VAL_ 1050 SHVU_STAT_RearSeatVentSts 0 "Normal Operation" 1 "Failure" 2 "Reserved" 3 "Signal invalid" ;
VAL_ 1052 PSM_Seat_track_pos_Dri 0 "Front position" 1 "Not Front position" 2 "Failure" 3 "Invalid Value" ;
VAL_ 1052 PSM_Seat_track_posPas 0 "Front position" 1 "Not Front position" 2 "Failure" 3 "Invalid Value" ;
VAL_ 1053 BCM_STAT_AutoRearWiper 0 "OFF" 1 "ON" 2 "Reserved" 3 "Signal invalid" ;
VAL_ 1053 BCM_STAT_MirrorFoldSetting 0 "Auto Fold OFF" 1 "Auto Fold ON" 2 "Reserved" 3 "Signal invalid" ;
VAL_ 1053 BCM_STAT_IMMO_KeyfobID2 0 "No trigger from MHU" 1 "Fob1" 2 "Fob2" 3 "key illegal" 4 "No key found" 5 "Searching" 6 "Reserved" 7 "Signal invalid" ;
VAL_ 1053 BCM_STAT_MirrorAutoUnfold 0 "Vehicle Unlock" 1 "Driver walk toward" 2 "OFF" 3 "Signal invalid" ;
VAL_ 1053 BCM_STAT_MirrorReverseLink 0 "OFF" 1 "Right Mirror" 2 "Left Mirror" 3 "Both Mirror";
VAL_ 1053 BCM_STAT_MirrorDefaultSTATting 0 "Not pressed" 1 "Pressed" 2 "Reserved" 3 "Signal invalid" ;
VAL_ 1053 BCM_STAT_WelcomeTriggerCondition 0 "Vehicle unLock" 1 "Driver walk toward" 2 "OFF" 3 "Signal invalid" ;
VAL_ 1053 BCM_STAT_FrontDomeLamp 0 "OFF" 1 "ON" 2 "AUTO" 3 "Signal invalid" ;
VAL_ 1053 BCM_STAT_FollowMeHome 0 "OFF" 1 "30 secs" 2 "60 secs" 3 "90 secs" 4 "120 secs" 5 "Signal invalid" ;
VAL_ 1053 BCM_STAT_ExteriorLight 0 "OFF" 1 "Parking" 2 "ON" 3 "AUTO" 4 "Signal invalid" ;
VAL_ 1053 BCM_STAT_RemoteLockFeedback 0 "OFF" 1 "Lights and Horn" 2 "Lights Only" 3 "Horn Only" 4 "Reserved" 5 "Reserved" 6 "Reserved" 7 "Signal invalid" ;
VAL_ 1053 BCM_STAT_RemoteDoorUnlock 0 "Reserved" 1 "Driver door" 2 "All doors" 3 "Signal invalid" ;
VAL_ 1053 BCM_STAT_AutoDoorUnlock 0 "OFF" 1 "ON" 2 "Reserved" 3 "Signal invalid" ;
VAL_ 1053 BCM_STAT_WalkawayDoorLock 0 "OFF" 1 "ON";
VAL_ 1053 BCM_STAT_WiperServiceMode 0 "OFF" 1 "ON" 2 "Reserved" 3 "Signal Invalid" ;
VAL_ 1053 BCM_STAT_IMMO_KeyfobID 0 "No Key Found" 1 "ID1" 2 "ID2" 3 "Signal Invalid" ;
VAL_ 1053 BCM_STAT_RearHeatedWindowMirror 0 "OFF" 1 "ON" 2 "Reserved" 3 "Signal invalid" ;
VAL_ 1053 BCM_STAT_AntiTheftMode 0 "OFF" 1 "Light Only" 2 "Horn Only" 3 "Light and Horn" 4 "Signal invalid" ;
VAL_ 1053 BCM_STAT_ClimateKeepOnSts 0 "OFF" 1 "PET" 2 "CAMP" 3 "REMOTE CONTROL" ;
VAL_ 1053 BCM_STAT_FKSfeedback 0 "OFF" 1 "ON" 2 "Reserved" 3 "Signal Invalid" ;
VAL_ 1055 OCS_Passenger_class_stat 1 "Seat Empty or Childseat (Class1)" 2 "Adult (Class2)" 3 "OSC Failure" ;
VAL_ 1058 MHU_STAT_Cluster 0 "OFF" 1 "ON" 2 "Reserved" 3 "Signal invalid" ;
VAL_ 1058 MHU_STAT_Infotainment 0 "OFF" 1 "ON" 2 "Reserved" 3 "Signal invalid" ;
VAL_ 1058 MHU_STAT_MileageUnit 0 "Mile" 1 "KM" 2 "Reserved" 3 "Signal invalid" ;
VAL_ 1058 MHU_STAT_PressureUnit 0 "Bar" 1 "Psi" 2 "Kpa" 3 "Signal invalid" ;
VAL_ 1058 MHU_STAT_TemperatureUnit 0 "Celcius" 1 "Fahrenheit" 2 "Reserved" 3 "Signal invalid" ;
VAL_ 1058 MHU_Operation_State 0 "Sleep - Low power mode" 1 "Standby/Screen OFF" 2 "Booting/Rebooting" 3 "Running" 4 "Standby/Fullscreen" 5 "OTA progess" 6 "Fault" 7 "Signal Invalid" ;
VAL_ 1058 MHU_STAT_Language 0 "Vietnamese" 1 "English" 2 "Spanish" 3 "French" 4 "German" 5 "Dutch" 6 "English (CANADA)" 7 "French (CANADA)" 8 "Russian" 9 "Spanish (Latin America)" 10 "Portuguese" 11 "Portuguese (Brasil)" 12 "Chinese, simplipied" 13 "Chinese, traditional" 14 "Reserved" 15 "Reserved" 16 "Reserved" 17 "Reserved" 18 "Reserved" 19 "Reserved" 20 "Reserved" 21 "Reserved" 22 "Reserved" 23 "Reserved" 24 "Reserved" 25 "Reserved" 26 "Reserved" 27 "Reserved" 28 "Reserved" 29 "Reserved" 30 "Reserved" 31 "Signal invalid" ;
VAL_ 1058 MHU_STAT_EnergyConsumptionUnit 0 "KWH/100KM" 1 "KM/KWH" 2 "Mile per KWH" 3 "KWH/100mil" 4 "Reserved" 5 "Reserved" 6 "Reserved" 7 "Signal invalid" ;
VAL_ 1068 PSM_D_DrvSeat_Control_Status 0 "Idle" 1 "Moving by MHU" 2 "Moving by switch" 3 "Failure" 4 "Reserved" 5 "Reserved" 6 "Reserved" 7 "Invalid" ;
VAL_ 1074 MHU_FOTA_State 0 "INIT" 1 "NORMAL" 2 "FOTA FLASHING" 3 "FOTA-SUSPENDED" 4 "FAIL-SAFE-ERROR" 5 "SHUTDOWN" 6 "REMOTE DIAGNOSTICS" 7 "Invalid" ;
VAL_ 1077 BCM_SCM_BC_Button 0 "Button not Pressed" 1 "Short Press" 2 "Long Press" 3 "Signal invalid" ;
VAL_ 1082 VCU_BrakeRegenMode 0 "HIGH" 1 "MID" 2 "LOW" 3 "OFF";
VAL_ 1082 VCU_CreepDisable_stt 0 "Enable" 1 "Disable" ;
VAL_ 1082 VCU_Charging_Authen_stt 0 "Not authencating" 1 "Authenticating" 2 "Authen success" 3 "Authen failed" 4 "Forbidden vehicle" 5 "reserved" 6 "reserved" 7 "reserved" ;
VAL_ 1082 VCU_ChgGun_BadConn_stt 0 "No error" 1 "Bad connection" ;
VAL_ 1082 VCU_ChgPort_Open_stt 0 "Closed" 1 "Opening" ;
VAL_ 1082 VCU_Regen_available 0 "Not available" 1 "Available" 2 "Regen limit" 3 "Regen faut" ;
VAL_ 1082 VCU_VehChg_STS 0 "Charging not in progress and gun not plug-in" 1 "Charging in progress" 2 "Charging complete" 3 "Charge fault" 4 "Gun plugged-in, Standby" 5 "Gun plugged-in, Waiting" 6 "Reserved" 7 "Signal Invalid" ;
VAL_ 1082 VCU_ChgGun_Status 0 "Charging gun not plugged" 1 "Locked" 2 "Released" 3 "Error due to plug voltage is higher than 60V." 4 "Error due to electrical failure of lock motor drive pins." 5 "Error due to electrical failure of lock feedback pins" 6 "Error plug lock feedback is received as error from BSW" 7 "Invalid" ;
VAL_ 1082 VCU_ChgPort_Lock_stt 0 "Locked" 1 "Released" ;
VAL_ 1082 VCU_Hvbatt_charging_stt 0 "Not charging" 1 "Charging" ;
VAL_ 1089 RESP_REM_LengthTyp_APM 0 "Functional status" 1 "Active function change" 2 "Reserved" 3 "Signal invalid" ;
VAL_ 1090 WLC_IC_Error 0 "No Error" 1 "Error" ;
VAL_ 1090 WLC_FAN_Error 0 "No Error" 1 "Error" ;
VAL_ 1090 WLC_TempSNSR_Error 0 "No Error" 1 "Error" ;
VAL_ 1090 WLC_Setting_standard 0 "OFF (Disable)" 1 "ON (Enable)" 2 "Default" 3 "Invalid" ;
VAL_ 1090 Transmit_WLC_situation 0 "Power OFF" 1 "Cellphone reminder" 2 "Charging" 3 "Charging complete" 4 "Wakeup" 5 "Error" 6 "Reserved" 7 "Invalid" ;
VAL_ 1090 WLC_VehSpeed_Error 0 "No Error" 1 "Error" ;
VAL_ 1090 WLC_Resp_Error 0 "No Error" 1 "Error" ;
VAL_ 1090 WLC_FOD_Error 0 "No Error" 1 "Error" ;
VAL_ 1090 WLC_Curr_Error 0 "No Error" 1 "Error" ;
VAL_ 1090 WLC_Temp_Error 0 "No Error" 1 "Error" ;
VAL_ 1091 WLC_IC_Error_2 0 "No Error" 1 "Error" ;
VAL_ 1091 WLC_FAN_Error_2 0 "No Error" 1 "Error" ;
VAL_ 1091 WLC_TempSNSR_Error_2 0 "No Error" 1 "Error" ;
VAL_ 1091 WLC_Setting_standard_2 0 "OFF (Disable)" 1 "ON (Enable)" 2 "Default" 3 "Invalid" ;
VAL_ 1091 Transmit_WLC_situation_2 0 "Power OFF" 1 "Cellphone reminder" 2 "Charging" 3 "Charging complete" 4 "Wakeup" 5 "Error" 6 "Reserved" 7 "Invalid" ;
VAL_ 1091 WLC_VehSpeed_Error_2 0 "No Error" 1 "Error" ;
VAL_ 1091 WLC_Resp_Error_2 0 "No Error" 1 "Error" ;
VAL_ 1091 WLC_FOD_Error_2 0 "No Error" 1 "Error" ;
VAL_ 1091 WLC_Curr_Error_2 0 "No Error" 1 "Error" ;
VAL_ 1091 WLC_Temp_Error_2 0 "No Error" 1 "Error" ;
VAL_ 1093 RS_Sol_L 254 "HW failure solar sensor" 255 "Signal invalid" ;
VAL_ 1093 RS_Sol_R 254 "HW failure solar sensor" 255 "Signal invalid" ;
VAL_ 1093 RS_F_LightSensor 0 "No error" 1 "Light sensor error" ;
VAL_ 1093 RS_F_HUD_Sensor 0 "No error" 1 "HUD error" ;
VAL_ 1093 RS_St_LampReq 0 "OFF" 1 "ON" 2 "Reserved" 3 "Invalid" ;
VAL_ 1093 RS_St_CurrentRain 0 "No rain" 1 "level 1(light rain)" 2 "level 2(moderate rain)" 3 "level 3(heavy rain)" 4 "Reserved" 5 "Reserved" 6 "Reserved" 7 "Signal invalid" ;
VAL_ 1093 RS_HUD_illuminance 65535 "Invalid" ;
VAL_ 1095 MHU_SET_TransportMode 0 "No request" 1 "Request ON"  2 "Request OFF" 3 "Signal Invalid";
VAL_ 1095 MHU_Request_CarOFF 0 "Not Request" 1 "Request Car goes to OFF" 2 "Reserved" 3 "Signal Invalid" ;
VAL_ 1095 MHU_SET_ChildMode 0 "Child Mode OFF" 1 "Child mode ON" 2 "Reserved" 3 "Signal Invalid" ;
VAL_ 1095 MHU_SET_GameMode 0 "Game mode OFF" 1 "Game mode ON" 2 "Reserved" 3 "Signal Invalid" ;
VAL_ 1095 MHU_SET_KaraokeMode 0 "Karaoke mode OFF" 1 "Karaoke ON" 2 "Reserved" 3 "Signal Invalid" ;
VAL_ 1095 MHU_SET_WashMode 0 "Wash mode OFFt" 1 "Wash mode ON" 2 "Reserved" 3 "Signal Invalid" ;
VAL_ 1095 MHU_SET_StopMode 0 "Creep" 1 "Hold" 2 "Roll" 3 "Signal Invalid" ;
VAL_ 1095 MHU_AVH_Sw 0 "No Action" 1 "ON" 2 "OFF" 3 "Reserved";
VAL_ 1104 WindowLifterFrontL 0 "No action" 1 "Manual open" 2 "Automatic open" 3 "Manual close" 4 "Automatic close" 5 "Slightly open" 6 "Reserved" 7 "Signal Invalid" ;
VAL_ 1104 WindowLifterFrontR 0 "No action" 1 "Manual open" 2 "Automatic open" 3 "Manual close" 4 "Automatic close" 5 "Slightly open" 6 "Reserved" 7 "Signal Invalid" ;
VAL_ 1104 WindowLifterRearL 0 "No action" 1 "Manual open" 2 "Automatic open" 3 "Manual close" 4 "Automatic close" 5 "Slightly open" 6 "Reserved" 7 "Signal Invalid" ;
VAL_ 1104 WindowLifterRearR 0 "No action" 1 "Manual open" 2 "Automatic open" 3 "Manual close" 4 "Automatic close" 5 "Slightly open" 6 "Reserved" 7 "Signal Invalid" ;
VAL_ 1104 MHU_SET_WindowAutoClose 0 "OFF" 1 "ON" 2 "Reserved" 3 "Signal invalid" ;
VAL_ 1110 OP_WISW_SZL_LIN 0 "No action" 255 "Signal Invalid" ;
VAL_ 1110 COMM_ERR_SZL_LIN 0 "No error" 1 "Error active" ;
VAL_ 1110 BCM_Wiper_Front_Status 0 "OFF" 1 "Mist" 2 "IntermittentAuto" 3 "Low Speed" 4 "High Speed" 5 "Reserved" 6 "Reserved" 7 "Invalid" ;
VAL_ 1110 OP_WIPO_SZL_LIN 0 "Step 1" 1 "Step 2" 2 "Step 3" 4 "Step 4" 7 "Signal Invalid" ;
VAL_ 1110 OP_COLS_SZL_LIN 0 "No action" 255 "Signal Invalid" ;
VAL_ 1110 NOD_ERR_SZL_LIN 0 "NO error" 1 "error active" 2 "error Stat change" 3 "Signal invalid" ;
VAL_ 1110 BCM_Wiper_Rear_Status 0 "OFF" 1 "ON" 2 "Reserved" 3 "Signal Invalid" ;
VAL_ 1111 AmbLight_Error_Z5 0 "No Error" 1 "Error" ;
VAL_ 1111 AmbLight_Error_Z4 0 "No Error" 1 "Error" ;
VAL_ 1111 AmbLight_Error_Z3 0 "No Error" 1 "Error" ;
VAL_ 1111 AmbLight_Error_Z2 0 "No Error" 1 "Error" ;
VAL_ 1111 AmbLight_Error_Z1 0 "No Error" 1 "Error" ;
